VERSION ""

NS_ :

BS_:

BU_: L_3HKBD L_FHPTC L_ATCU L_2HKBD L_PCM L_ATCU_vMON L_EVNT L_HKBD L_RHPTC

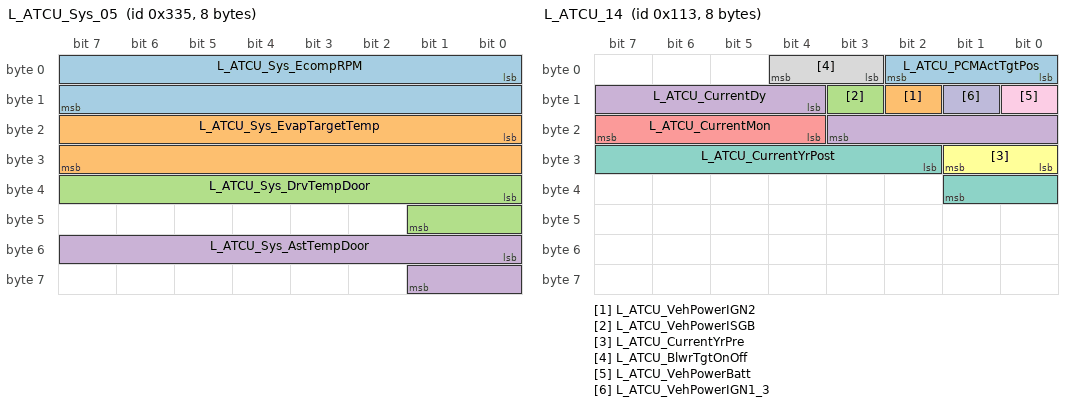
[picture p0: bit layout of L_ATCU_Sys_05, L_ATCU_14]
BO_ 821 L_ATCU_Sys_05: 8 L_ATCU
 SG_ L_ATCU_Sys_EcompRPM : 0|16@1+ (1,0) [0|65535] ""  L_ATCU_vMON
 SG_ L_ATCU_Sys_EvapTargetTemp : 16|16@1+ (0.1,-20) [-20|40] ""  L_ATCU_vMON
 SG_ L_ATCU_Sys_DrvTempDoor : 32|10@1+ (1,0) [0|1023] ""  L_ATCU_vMON
 SG_ L_ATCU_Sys_AstTempDoor : 48|10@1+ (1,0) [0|1023] ""  L_ATCU_vMON

BO_ 275 L_ATCU_14: 8 L_ATCU
 SG_ L_ATCU_PCMActTgtPos : 0|3@1+ (1,0) [0|0] ""  L_PCM
 SG_ L_ATCU_VehPowerIGN2 : 10|1@1+ (1,0) [0|0] ""  L_PCM
 SG_ L_ATCU_VehPowerISGB : 11|1@1+ (1,0) [0|0] ""  L_PCM
 SG_ L_ATCU_CurrentDy : 12|8@1+ (1,0) [0|0] ""  L_PCM
 SG_ L_ATCU_CurrentMon : 20|4@1+ (1,0) [0|0] ""  L_PCM
 SG_ L_ATCU_CurrentYrPre : 24|2@1+ (1,0) [0|0] ""  L_PCM
 SG_ L_ATCU_CurrentYrPost : 26|8@1+ (1,0) [0|0] ""  L_PCM
 SG_ L_ATCU_BlwrTgtOnOff : 3|2@1+ (0.5,0) [0|0] "RPM"  L_PCM
 SG_ L_ATCU_VehPowerBatt : 8|1@1+ (1,0) [0|0] ""  L_PCM
 SG_ L_ATCU_VehPowerIGN1_3 : 9|1@1+ (1,0) [0|0] ""  L_PCM

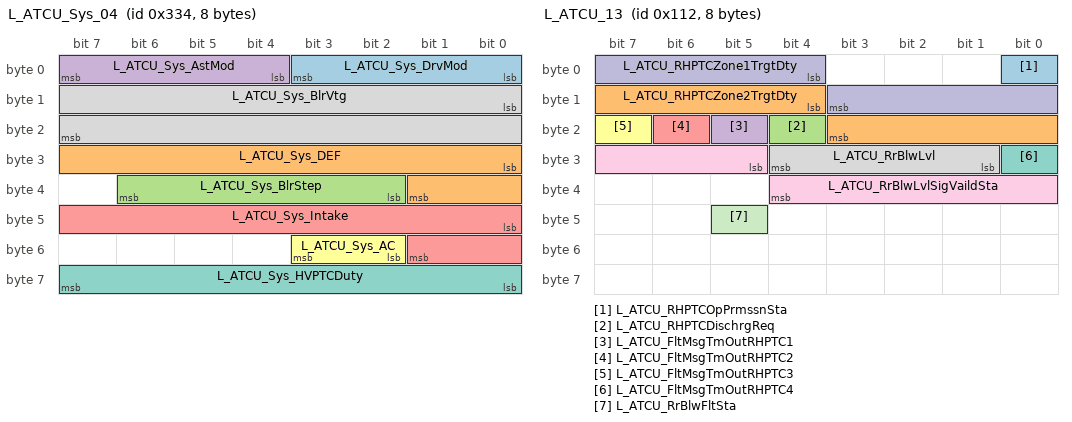
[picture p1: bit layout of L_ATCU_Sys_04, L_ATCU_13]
BO_ 820 L_ATCU_Sys_04: 8 L_ATCU
 SG_ L_ATCU_Sys_DrvMod : 0|4@1+ (1,0) [0|15] ""  L_ATCU_vMON
 SG_ L_ATCU_Sys_DEF : 24|10@1+ (1,0) [0|1023] ""  L_ATCU_vMON
 SG_ L_ATCU_Sys_BlrStep : 34|5@1+ (1,0) [0|31] ""  L_ATCU_vMON
 SG_ L_ATCU_Sys_AstMod : 4|4@1+ (1,0) [0|15] ""  L_ATCU_vMON
 SG_ L_ATCU_Sys_Intake : 40|10@1+ (1,0) [0|1023] ""  L_ATCU_vMON
 SG_ L_ATCU_Sys_AC : 50|2@1+ (1,0) [0|3] ""  L_ATCU_vMON
 SG_ L_ATCU_Sys_HVPTCDuty : 56|8@1+ (1,0) [0|255] ""  L_ATCU_vMON
 SG_ L_ATCU_Sys_BlrVtg : 8|16@1+ (1,0) [0|65535] ""  L_ATCU_vMON

BO_ 274 L_ATCU_13: 8 L_ATCU
 SG_ L_ATCU_RHPTCOpPrmssnSta : 0|1@1+ (1,0) [0|0] ""  L_FHPTC,L_RHPTC
 SG_ L_ATCU_RHPTCZone2TrgtDty : 12|8@1+ (0.5,0) [0|0] "%"  L_FHPTC,L_RHPTC
 SG_ L_ATCU_RHPTCDischrgReq : 20|1@1+ (1,0) [0|0] ""  L_FHPTC,L_RHPTC
 SG_ L_ATCU_FltMsgTmOutRHPTC1 : 21|1@1+ (1,0) [0|0] ""  L_FHPTC,L_RHPTC
 SG_ L_ATCU_FltMsgTmOutRHPTC2 : 22|1@1+ (1,0) [0|0] ""  L_FHPTC,L_RHPTC
 SG_ L_ATCU_FltMsgTmOutRHPTC3 : 23|1@1+ (1,0) [0|0] ""  L_FHPTC,L_RHPTC
 SG_ L_ATCU_FltMsgTmOutRHPTC4 : 24|1@1+ (1,0) [0|0] ""  L_FHPTC,L_RHPTC
 SG_ L_ATCU_RrBlwLvl : 25|4@1+ (1,0) [0|0] ""  L_EVNT,L_FHPTC,L_RHPTC
 SG_ L_ATCU_RrBlwLvlSigVaildSta : 29|8@1+ (1,0) [0|0] ""  L_FHPTC,L_RHPTC
 SG_ L_ATCU_RHPTCZone1TrgtDty : 4|8@1+ (0.5,0) [0|0] "%"  L_FHPTC,L_RHPTC
 SG_ L_ATCU_RrBlwFltSta : 45|1@1+ (1,0) [0|0] ""  L_FHPTC,L_RHPTC

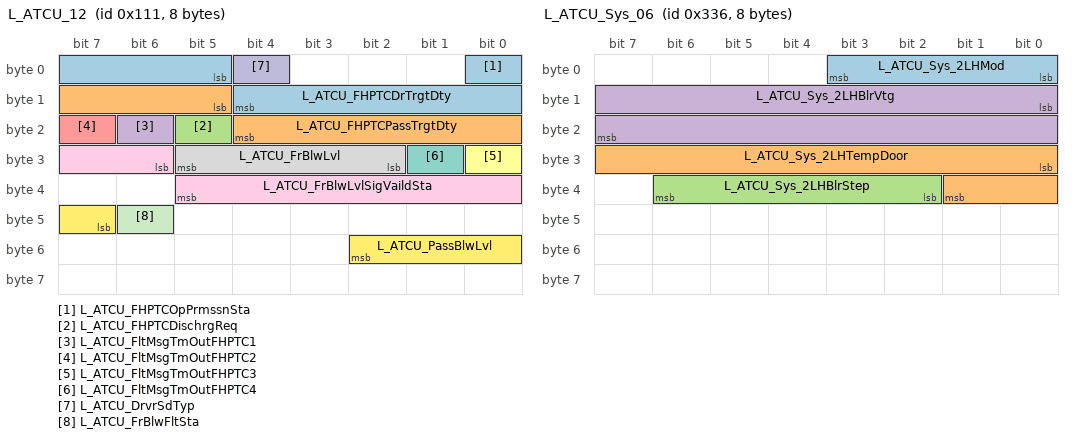
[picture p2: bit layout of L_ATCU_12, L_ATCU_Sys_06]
BO_ 273 L_ATCU_12: 8 L_ATCU
 SG_ L_ATCU_FHPTCOpPrmssnSta : 0|1@1+ (1,0) [0|0] ""  L_FHPTC,L_RHPTC
 SG_ L_ATCU_FHPTCPassTrgtDty : 13|8@1+ (0.5,0) [0|0] "%"  L_FHPTC,L_RHPTC
 SG_ L_ATCU_FHPTCDischrgReq : 21|1@1+ (1,0) [0|0] ""  L_FHPTC,L_RHPTC
 SG_ L_ATCU_FltMsgTmOutFHPTC1 : 22|1@1+ (1,0) [0|0] ""  L_FHPTC,L_RHPTC
 SG_ L_ATCU_FltMsgTmOutFHPTC2 : 23|1@1+ (1,0) [0|0] ""  L_FHPTC,L_RHPTC
 SG_ L_ATCU_FltMsgTmOutFHPTC3 : 24|1@1+ (1,0) [0|0] ""  L_FHPTC,L_RHPTC
 SG_ L_ATCU_FltMsgTmOutFHPTC4 : 25|1@1+ (1,0) [0|0] ""  L_FHPTC,L_RHPTC
 SG_ L_ATCU_FrBlwLvl : 26|4@1+ (1,0) [0|0] ""  L_EVNT,L_FHPTC,L_RHPTC
 SG_ L_ATCU_FrBlwLvlSigVaildSta : 30|8@1+ (1,0) [0|0] ""  L_FHPTC,L_RHPTC
 SG_ L_ATCU_DrvrSdTyp : 4|1@1+ (1,0) [0|0] ""  L_EVNT,L_FHPTC,L_HKBD,L_RHPTC
 SG_ L_ATCU_FrBlwFltSta : 46|1@1+ (1,0) [0|0] ""  L_FHPTC,L_RHPTC
 SG_ L_ATCU_PassBlwLvl : 47|4@1+ (1,0) [0|0] ""  L_EVNT,L_FHPTC,L_RHPTC
 SG_ L_ATCU_FHPTCDrTrgtDty : 5|8@1+ (0.5,0) [0|0] "%"  L_FHPTC,L_RHPTC

BO_ 822 L_ATCU_Sys_06: 8 L_ATCU
 SG_ L_ATCU_Sys_2LHMod : 0|4@1+ (1,0) [0|15] ""  L_ATCU_vMON
 SG_ L_ATCU_Sys_2LHTempDoor : 24|10@1+ (1,0) [0|1023] ""  L_ATCU_vMON
 SG_ L_ATCU_Sys_2LHBlrStep : 34|5@1+ (1,0) [0|31] ""  L_ATCU_vMON
 SG_ L_ATCU_Sys_2LHBlrVtg : 8|16@1+ (1,0) [0|65535] ""  L_ATCU_vMON

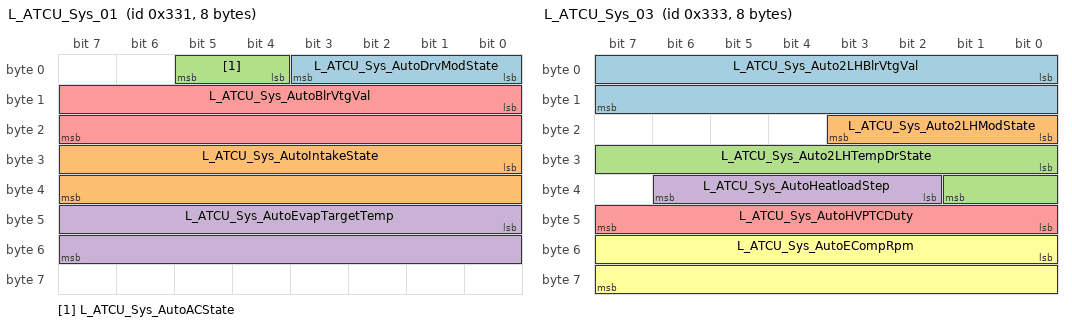
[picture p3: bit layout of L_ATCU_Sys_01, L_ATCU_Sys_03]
BO_ 817 L_ATCU_Sys_01: 8 L_ATCU
 SG_ L_ATCU_Sys_AutoDrvModState : 0|4@1+ (1,0) [0|15] ""  L_ATCU_vMON
 SG_ L_ATCU_Sys_AutoIntakeState : 24|16@1+ (1,0) [0|65535] ""  L_ATCU_vMON
 SG_ L_ATCU_Sys_AutoACState : 4|2@1+ (1,0) [0|3] ""  L_ATCU_vMON
 SG_ L_ATCU_Sys_AutoEvapTargetTemp : 40|16@1+ (0.1,-20) [-20|40] ""  L_ATCU_vMON
 SG_ L_ATCU_Sys_AutoBlrVtgVal : 8|16@1+ (1,0) [0|65535] ""  L_ATCU_vMON

BO_ 278 L_ATCU_17: 8 L_ATCU
 SG_ L_ATCU_HU_MasterProfile_ResetIndex : 0|4@1+ (1,0) [0|0] ""  L_2HKBD,L_3HKBD,L_EVNT,L_HKBD
 SG_ L_ATCU_HU_OptionInfo : 4|16@1+ (1,0) [0|0] ""  L_2HKBD,L_3HKBD,L_EVNT,L_HKBD

BO_ 819 L_ATCU_Sys_03: 8 L_ATCU
 SG_ L_ATCU_Sys_Auto2LHBlrVtgVal : 0|16@1+ (1,0) [0|65535] ""  L_ATCU_vMON
 SG_ L_ATCU_Sys_Auto2LHModState : 16|4@1+ (1,0) [0|15] ""  L_ATCU_vMON
 SG_ L_ATCU_Sys_Auto2LHTempDrState : 24|10@1+ (1,0) [0|1023] ""  L_ATCU_vMON
 SG_ L_ATCU_Sys_AutoHeatloadStep : 34|5@1+ (1,0) [0|31] ""  L_ATCU_vMON
 SG_ L_ATCU_Sys_AutoHVPTCDuty : 40|8@1+ (1,0) [0|255] ""  L_ATCU_vMON
 SG_ L_ATCU_Sys_AutoECompRpm : 48|16@1+ (1,0) [0|65535] ""  L_ATCU_vMON

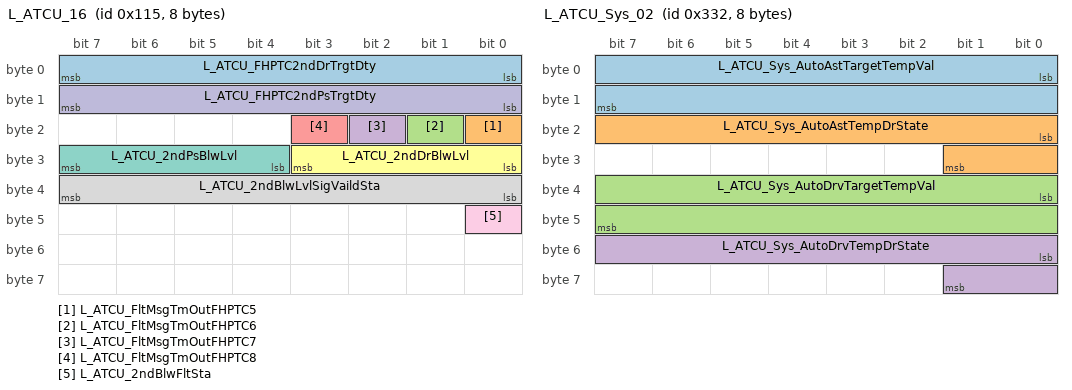
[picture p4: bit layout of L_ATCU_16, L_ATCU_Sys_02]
BO_ 277 L_ATCU_16: 8 L_ATCU
 SG_ L_ATCU_FHPTC2ndDrTrgtDty : 0|8@1+ (0.5,0) [0|0] "%"  L_FHPTC,L_RHPTC
 SG_ L_ATCU_FltMsgTmOutFHPTC5 : 16|1@1+ (1,0) [0|0] ""  L_FHPTC,L_RHPTC
 SG_ L_ATCU_FltMsgTmOutFHPTC6 : 17|1@1+ (1,0) [0|0] ""  L_FHPTC,L_RHPTC
 SG_ L_ATCU_FltMsgTmOutFHPTC7 : 18|1@1+ (1,0) [0|0] ""  L_FHPTC,L_RHPTC
 SG_ L_ATCU_FltMsgTmOutFHPTC8 : 19|1@1+ (1,0) [0|0] ""  L_FHPTC,L_RHPTC
 SG_ L_ATCU_2ndDrBlwLvl : 24|4@1+ (1,0) [0|0] ""  L_EVNT,L_FHPTC,L_RHPTC
 SG_ L_ATCU_2ndPsBlwLvl : 28|4@1+ (1,0) [0|0] ""  L_EVNT,L_FHPTC,L_RHPTC
 SG_ L_ATCU_2ndBlwLvlSigVaildSta : 32|8@1+ (1,0) [0|0] ""  L_FHPTC,L_RHPTC
 SG_ L_ATCU_2ndBlwFltSta : 40|1@1+ (1,0) [0|0] ""  L_FHPTC,L_RHPTC
 SG_ L_ATCU_FHPTC2ndPsTrgtDty : 8|8@1+ (0.5,0) [0|0] "%"  L_FHPTC,L_RHPTC

BO_ 818 L_ATCU_Sys_02: 8 L_ATCU
 SG_ L_ATCU_Sys_AutoAstTargetTempVal : 0|16@1+ (0.1,-40) [-40|60] ""  L_ATCU_vMON
 SG_ L_ATCU_Sys_AutoAstTempDrState : 16|10@1+ (1,0) [0|1023] ""  L_ATCU_vMON
 SG_ L_ATCU_Sys_AutoDrvTargetTempVal : 32|16@1+ (0.1,-40) [-40|60] ""  L_ATCU_vMON
 SG_ L_ATCU_Sys_AutoDrvTempDrState : 48|10@1+ (1,0) [0|1023] ""  L_ATCU_vMON

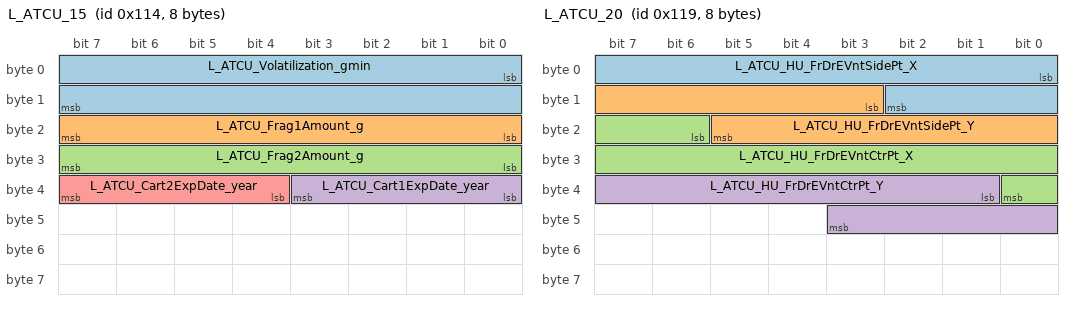
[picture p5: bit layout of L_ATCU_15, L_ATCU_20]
BO_ 276 L_ATCU_15: 8 L_ATCU
 SG_ L_ATCU_Volatilization_gmin : 0|16@1+ (1.0E-6,0) [0|0] "g/min"  L_PCM
 SG_ L_ATCU_Frag1Amount_g : 16|8@1+ (0.1,0) [0|0] "g"  L_PCM
 SG_ L_ATCU_Frag2Amount_g : 24|8@1+ (0.1,0) [0|0] "g"  L_PCM
 SG_ L_ATCU_Cart1ExpDate_year : 32|4@1+ (1,0) [0|0] "Year"  L_PCM
 SG_ L_ATCU_Cart2ExpDate_year : 36|4@1+ (1,0) [0|0] "Year"  L_PCM

BO_ 281 L_ATCU_20: 8 L_ATCU
 SG_ L_ATCU_HU_FrDrEVntSidePt_X : 0|11@1+ (1,0) [0|0] ""  L_EVNT
 SG_ L_ATCU_HU_FrDrEVntSidePt_Y : 11|11@1+ (1,0) [0|0] ""  L_EVNT
 SG_ L_ATCU_HU_FrDrEVntCtrPt_X : 22|11@1+ (1,0) [0|0] ""  L_EVNT
 SG_ L_ATCU_HU_FrDrEVntCtrPt_Y : 33|11@1+ (1,0) [0|0] ""  L_EVNT

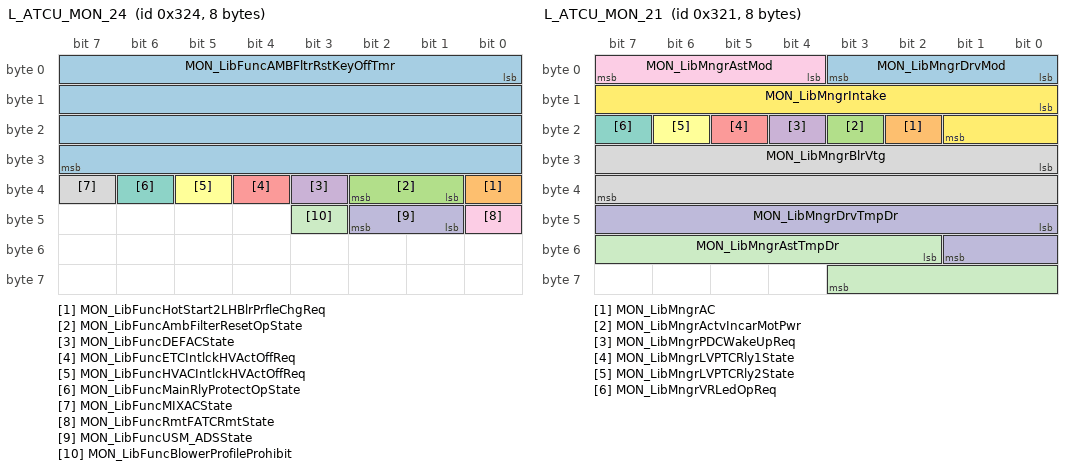
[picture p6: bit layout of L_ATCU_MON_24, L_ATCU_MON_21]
BO_ 804 L_ATCU_MON_24: 8 L_ATCU_vMON
 SG_ MON_LibFuncAMBFltrRstKeyOffTmr : 0|32@1+ (1,0) [0|0] "s"  L_ATCU
 SG_ MON_LibFuncHotStart2LHBlrPrfleChgReq : 32|1@1+ (1,0) [0|0] ""  L_ATCU
 SG_ MON_LibFuncAmbFilterResetOpState : 33|2@1+ (1,0) [0|0] ""  L_ATCU
 SG_ MON_LibFuncDEFACState : 35|1@1+ (1,0) [0|0] ""  L_ATCU
 SG_ MON_LibFuncETCIntlckHVActOffReq : 36|1@1+ (1,0) [0|0] ""  L_ATCU
 SG_ MON_LibFuncHVACIntlckHVActOffReq : 37|1@1+ (1,0) [0|0] ""  L_ATCU
 SG_ MON_LibFuncMainRlyProtectOpState : 38|1@1+ (1,0) [0|0] ""  L_ATCU
 SG_ MON_LibFuncMIXACState : 39|1@1+ (1,0) [0|0] ""  L_ATCU
 SG_ MON_LibFuncRmtFATCRmtState : 40|1@1+ (1,0) [0|0] ""  L_ATCU
 SG_ MON_LibFuncUSM_ADSState : 41|2@1+ (1,0) [0|0] ""  L_ATCU
 SG_ MON_LibFuncBlowerProfileProhibit : 43|1@1+ (1,0) [0|0] ""  L_ATCU

BO_ 805 L_ATCU_MON_25: 8 L_ATCU_vMON
 SG_ MON_LibMEMUSMROMWriteCmd : 0|32@1+ (1,0) [0|0] ""  L_ATCU
 SG_ MON_LibMEMROMWriteMEM : 32|32@1+ (1,0) [0|0] ""  L_ATCU

BO_ 806 L_ATCU_MON_26: 8 L_ATCU_vMON
 SG_ MON_LibFuncAfterBlowStandbyTime : 0|32@1+ (1,0) [0|0] "ms"  L_ATCU
 SG_ MON_LibFuncSchdldVentStandbyTime : 32|32@1+ (1,0) [0|0] "s"  L_ATCU

BO_ 807 L_ATCU_MON_27: 8 L_ATCU_vMON
 SG_ MON_LibFuncHICCSWVer : 0|32@1+ (1,0) [0|0] ""  L_ATCU

BO_ 801 L_ATCU_MON_21: 8 L_ATCU_vMON
 SG_ MON_LibMngrDrvMod : 0|4@1+ (1,0) [0|0] ""  L_ATCU
 SG_ MON_LibMngrAC : 18|1@1+ (1,0) [0|0] ""  L_ATCU
 SG_ MON_LibMngrActvIncarMotPwr : 19|1@1+ (1,0) [0|0] ""  L_ATCU
 SG_ MON_LibMngrPDCWakeUpReq : 20|1@1+ (1,0) [0|0] ""  L_ATCU
 SG_ MON_LibMngrLVPTCRly1State : 21|1@1+ (1,0) [0|0] ""  L_ATCU
 SG_ MON_LibMngrLVPTCRly2State : 22|1@1+ (1,0) [0|0] ""  L_ATCU
 SG_ MON_LibMngrVRLedOpReq : 23|1@1+ (1,0) [0|0] ""  L_ATCU
 SG_ MON_LibMngrBlrVtg : 24|16@1+ (0.001,0) [0|0] "V"  L_ATCU
 SG_ MON_LibMngrAstMod : 4|4@1+ (1,0) [0|0] ""  L_ATCU
 SG_ MON_LibMngrDrvTmpDr : 40|10@1+ (0.1,0) [0|0] "%"  L_ATCU
 SG_ MON_LibMngrAstTmpDr : 50|10@1+ (0.1,0) [0|0] "%"  L_ATCU
 SG_ MON_LibMngrIntake : 8|10@1+ (1,0) [0|0] ""  L_ATCU

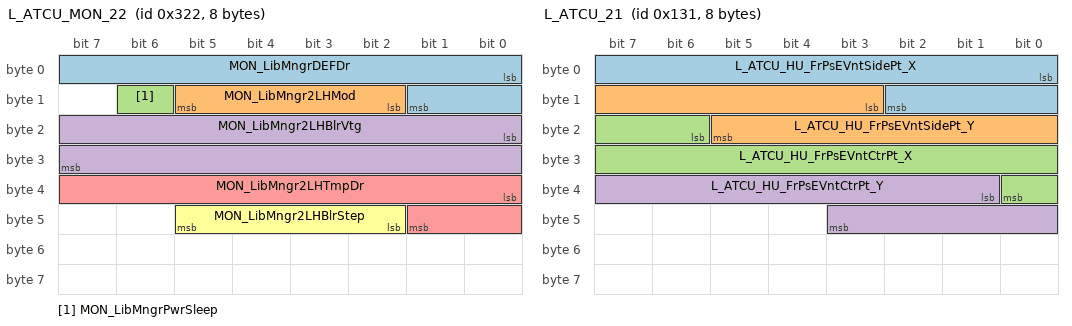
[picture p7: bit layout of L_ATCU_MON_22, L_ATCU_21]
BO_ 802 L_ATCU_MON_22: 8 L_ATCU_vMON
 SG_ MON_LibMngrDEFDr : 0|10@1+ (0.1,0) [0|0] "%"  L_ATCU
 SG_ MON_LibMngr2LHMod : 10|4@1+ (1,0) [0|0] ""  L_ATCU
 SG_ MON_LibMngrPwrSleep : 14|1@1+ (1,0) [0|0] ""  L_ATCU
 SG_ MON_LibMngr2LHBlrVtg : 16|16@1+ (0.001,0) [0|0] "V"  L_ATCU
 SG_ MON_LibMngr2LHTmpDr : 32|10@1+ (0.1,0) [0|0] "%"  L_ATCU
 SG_ MON_LibMngr2LHBlrStep : 42|4@1+ (1,0) [0|0] ""  L_ATCU

BO_ 803 L_ATCU_MON_23: 8 L_ATCU_vMON
 SG_ MON_LibFuncSysKeyState : 0|3@1+ (1,0) [0|0] ""  L_ATCU
 SG_ MON_LibFuncSwBlrStatus : 12|1@1+ (1,0) [0|0] ""  L_ATCU
 SG_ MON_LibFuncSwIntakeStatus : 13|1@1+ (1,0) [0|0] ""  L_ATCU
 SG_ MON_LibFuncSwACStatus : 14|1@1+ (1,0) [0|0] ""  L_ATCU
 SG_ MON_LibFuncAutoSw : 15|1@1+ (1,0) [0|0] ""  L_ATCU
 SG_ MON_LibFuncSwIntakeState : 16|10@1+ (0.1,0) [0|0] ""  L_ATCU
 SG_ MON_LibFuncIntakeRECSw : 26|1@1+ (1,0) [0|0] ""  L_ATCU
 SG_ MON_LibFuncSwDrvTempStepState : 27|5@1+ (1,0) [0|0] ""  L_ATCU
 SG_ MON_LibFuncSwModState : 3|4@1+ (1,0) [0|0] ""  L_ATCU
 SG_ MON_LibFunc2LHSwTempStepState : 32|5@1+ (1,0) [0|0] ""  L_ATCU
 SG_ MON_LibFuncIntakeFRESw : 37|1@1+ (1,0) [0|0] ""  L_ATCU
 SG_ MON_LibFunc2LHSwModStatus : 38|1@1+ (1,0) [0|0] ""  L_ATCU
 SG_ MON_LibFunc2LHBlowerProfileProhibit : 39|1@1+ (1,0) [0|0] ""  L_ATCU
 SG_ MON_LibFunc2LHSwModState : 40|4@1+ (1,0) [0|0] ""  L_ATCU
 SG_ MON_LibFunc2LHBlrStepState : 44|4@1+ (1,0) [0|0] ""  L_ATCU
 SG_ MON_LibFunc2LHAutoSw : 48|1@1+ (1,0) [0|0] ""  L_ATCU
 SG_ MON_LibFunc2LHSwBlrStatus : 49|1@1+ (1,0) [0|0] ""  L_ATCU
 SG_ MON_LibFuncSwModStatus : 7|1@1+ (1,0) [0|0] ""  L_ATCU
 SG_ MON_LibFuncBlrStepState : 8|4@1+ (1,0) [0|0] ""  L_ATCU

BO_ 791 L_ATCU_MON_42: 8 L_ATCU_vMON
 SG_ MON_StatMngr_2ndMngr : 0|64@1+ (1,0) [0|0] ""  L_ATCU

BO_ 305 L_ATCU_21: 8 L_ATCU
 SG_ L_ATCU_HU_FrPsEVntSidePt_X : 0|11@1+ (1,0) [0|0] ""  L_EVNT
 SG_ L_ATCU_HU_FrPsEVntSidePt_Y : 11|11@1+ (1,0) [0|0] ""  L_EVNT
 SG_ L_ATCU_HU_FrPsEVntCtrPt_X : 22|11@1+ (1,0) [0|0] ""  L_EVNT
 SG_ L_ATCU_HU_FrPsEVntCtrPt_Y : 33|11@1+ (1,0) [0|0] ""  L_EVNT

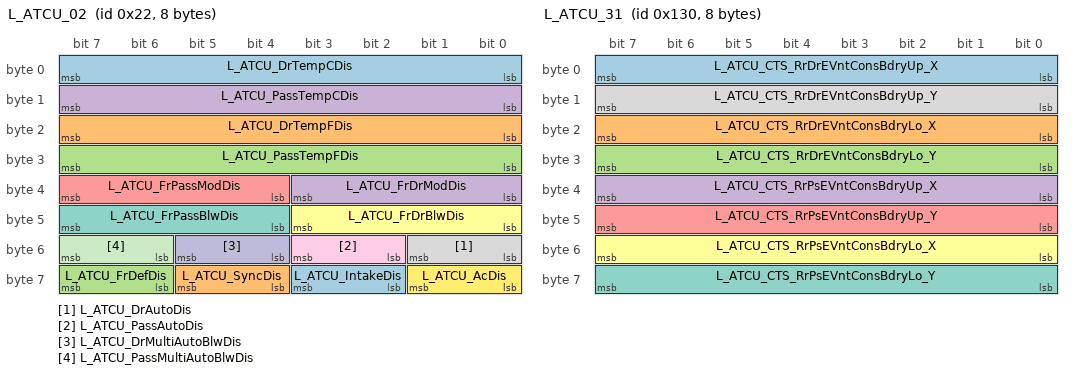
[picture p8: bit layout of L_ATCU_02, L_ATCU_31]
BO_ 34 L_ATCU_02: 8 L_ATCU
 SG_ L_ATCU_DrTempCDis : 0|8@1+ (0.5,14) [0|0] "¡É"  L_HKBD
 SG_ L_ATCU_DrTempFDis : 16|8@1+ (1,56) [0|0] "¢µ"  L_HKBD
 SG_ L_ATCU_PassTempFDis : 24|8@1+ (1,56) [0|0] "¢µ"  L_HKBD
 SG_ L_ATCU_FrDrModDis : 32|4@1+ (1,0) [0|0] ""  L_EVNT,L_HKBD
 SG_ L_ATCU_FrPassModDis : 36|4@1+ (1,0) [0|0] ""  L_EVNT,L_HKBD
 SG_ L_ATCU_FrDrBlwDis : 40|4@1+ (1,0) [0|0] ""  L_HKBD
 SG_ L_ATCU_FrPassBlwDis : 44|4@1+ (1,0) [0|0] ""  L_HKBD
 SG_ L_ATCU_DrAutoDis : 48|2@1+ (1,0) [0|0] ""  L_HKBD
 SG_ L_ATCU_PassAutoDis : 50|2@1+ (1,0) [0|0] ""  L_HKBD
 SG_ L_ATCU_DrMultiAutoBlwDis : 52|2@1+ (1,0) [0|0] ""  L_HKBD
 SG_ L_ATCU_PassMultiAutoBlwDis : 54|2@1+ (1,0) [0|0] ""  L_HKBD
 SG_ L_ATCU_AcDis : 56|2@1+ (1,0) [0|0] ""  L_HKBD
 SG_ L_ATCU_IntakeDis : 58|2@1+ (1,0) [0|0] ""  L_HKBD
 SG_ L_ATCU_SyncDis : 60|2@1+ (1,0) [0|0] ""  L_HKBD
 SG_ L_ATCU_FrDefDis : 62|2@1+ (1,0) [0|0] ""  L_HKBD
 SG_ L_ATCU_PassTempCDis : 8|8@1+ (0.5,14) [0|0] "¡É"  L_HKBD

BO_ 790 L_ATCU_MON_41: 8 L_ATCU_vMON
 SG_ MON_StatMngr_2ndSafetynCool : 0|64@1+ (1,0) [0|0] ""  L_ATCU

BO_ 304 L_ATCU_31: 8 L_ATCU
 SG_ L_ATCU_CTS_RrDrEVntConsBdryUp_X : 0|8@1+ (10,0) [0|0] ""  L_EVNT
 SG_ L_ATCU_CTS_RrDrEVntConsBdryLo_X : 16|8@1+ (10,0) [0|0] ""  L_EVNT
 SG_ L_ATCU_CTS_RrDrEVntConsBdryLo_Y : 24|8@1+ (10,0) [0|0] ""  L_EVNT
 SG_ L_ATCU_CTS_RrPsEVntConsBdryUp_X : 32|8@1+ (10,0) [0|0] ""  L_EVNT
 SG_ L_ATCU_CTS_RrPsEVntConsBdryUp_Y : 40|8@1+ (10,0) [0|0] ""  L_EVNT
 SG_ L_ATCU_CTS_RrPsEVntConsBdryLo_X : 48|8@1+ (10,0) [0|0] ""  L_EVNT
 SG_ L_ATCU_CTS_RrPsEVntConsBdryLo_Y : 56|8@1+ (10,0) [0|0] ""  L_EVNT
 SG_ L_ATCU_CTS_RrDrEVntConsBdryUp_Y : 8|8@1+ (10,0) [0|0] ""  L_EVNT

BO_ 35 L_ATCU_03: 8 L_ATCU
 SG_ L_ATCU_DrOnlyDis : 0|2@1+ (1,0) [0|0] ""  L_EVNT,L_HKBD
 SG_ L_ATCU_SmrtVntDis : 11|2@1+ (1,0) [0|0] ""  L_HKBD
 SG_ L_ATCU_FrWndShldHtInd : 13|2@1+ (1,0) [0|0] ""  L_HKBD
 SG_ L_ATCU_IncarMtrOnReq : 15|1@1+ (1,0) [0|0] ""  L_HKBD
 SG_ L_ATCU_LanguageInfo : 16|8@1+ (1,0) [0|0] ""  L_HKBD
 SG_ L_ATCU_RrDefInd : 2|1@1+ (1,0) [0|0] ""  L_HKBD
 SG_ L_ATCU_AfterBlowDisplay : 24|2@1+ (1,0) [0|0] ""  L_HKBD
 SG_ L_ATCU_SchdldVentDisplay : 26|2@1+ (1,0) [0|0] ""  L_HKBD
 SG_ L_ATCU_FLStHeatSwHInd : 28|1@1+ (1,0) [0|0] ""  L_HKBD
 SG_ L_ATCU_FLStHeatSwMInd : 29|1@1+ (1,0) [0|0] ""  L_HKBD
 SG_ L_ATCU_ADSBlinkDis : 3|2@1+ (1,0) [0|0] ""  L_HKBD
 SG_ L_ATCU_FLStHeatSwLInd : 30|1@1+ (1,0) [0|0] ""  L_HKBD
 SG_ L_ATCU_FLStVntSwHInd : 31|1@1+ (1,0) [0|0] ""  L_HKBD
 SG_ L_ATCU_FLStVntSwMInd : 32|1@1+ (1,0) [0|0] ""  L_HKBD
 SG_ L_ATCU_FLStVntSwLInd : 33|1@1+ (1,0) [0|0] ""  L_HKBD
 SG_ L_ATCU_FRStHeatSwHInd : 34|1@1+ (1,0) [0|0] ""  L_HKBD
 SG_ L_ATCU_FRStHeatSwMInd : 35|1@1+ (1,0) [0|0] ""  L_HKBD
 SG_ L_ATCU_FRStHeatSwLInd : 36|1@1+ (1,0) [0|0] ""  L_HKBD
 SG_ L_ATCU_FRStVntSwHInd : 37|1@1+ (1,0) [0|0] ""  L_HKBD
 SG_ L_ATCU_FRStVntSwMInd : 38|1@1+ (1,0) [0|0] ""  L_HKBD
 SG_ L_ATCU_FRStVntSwLInd : 39|1@1+ (1,0) [0|0] ""  L_HKBD
 SG_ L_ATCU_StrWhlHeatInd : 40|2@1+ (1,0) [0|0] ""  L_HKBD
 SG_ L_ATCU_RhstaLvlSta : 42|5@1+ (1,0) [0|0] ""  L_2HKBD,L_EVNT,L_HKBD
 SG_ L_ATCU_IntTailOnOff : 47|1@1+ (1,0) [0|0] ""  L_2HKBD,L_HKBD
 SG_ L_ATCU_AutoLightSta : 48|1@1+ (1,0) [0|0] ""  L_HKBD
 SG_ L_ATCU_FrBckLightSta : 49|1@1+ (1,0) [0|0] ""  L_HKBD
 SG_ L_ATCU_DisplayTheme : 50|2@1+ (1,0) [0|0] ""  L_HKBD
 SG_ L_ATCU_GUIBlankDis : 52|1@1+ (1,0) [0|0] ""  L_HKBD
 SG_ L_ATCU_HptIntnstySet : 53|4@1+ (1,0) [0|0] ""  L_HKBD
 SG_ L_ATCU_TlltLmpDis : 57|3@1+ (1,0) [0|0] ""  L_HKBD
 SG_ L_ATCU_AvTailOnOff : 60|1@1+ (1,0) [0|0] ""  L_HKBD
 SG_ L_ATCU_SchdldClimateDisplay : 61|2@1+ (1,0) [0|0] ""  L_HKBD
 SG_ L_ATCU_AirClnDis : 7|2@1+ (1,0) [0|0] ""  L_HKBD
 SG_ L_ATCU_CO2WrngDis : 9|2@1+ (1,0) [0|0] ""  L_HKBD

BO_ 789 L_ATCU_MON_40: 8 L_ATCU_vMON
 SG_ MON_StatMngr_2ndTemp : 0|64@1+ (1,0) [0|0] ""  L_ATCU

BO_ 788 L_ATCU_MON_39: 8 L_ATCU_vMON
 SG_ MON_StatMngr_2ndHumid : 0|64@1+ (1,0) [0|0] ""  L_ATCU

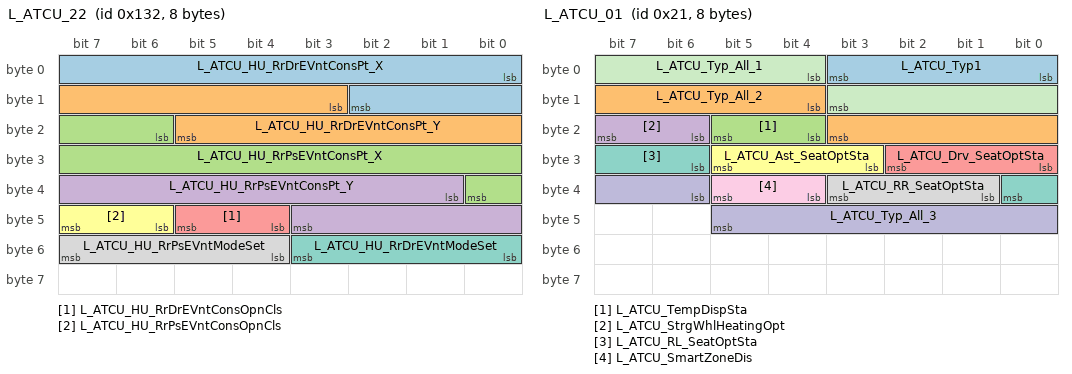
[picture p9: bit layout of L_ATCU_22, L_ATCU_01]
BO_ 306 L_ATCU_22: 8 L_ATCU
 SG_ L_ATCU_HU_RrDrEVntConsPt_X : 0|11@1+ (1,0) [0|0] ""  L_EVNT
 SG_ L_ATCU_HU_RrDrEVntConsPt_Y : 11|11@1+ (1,0) [0|0] ""  L_EVNT
 SG_ L_ATCU_HU_RrPsEVntConsPt_X : 22|11@1+ (1,0) [0|0] ""  L_EVNT
 SG_ L_ATCU_HU_RrPsEVntConsPt_Y : 33|11@1+ (1,0) [0|0] ""  L_EVNT
 SG_ L_ATCU_HU_RrDrEVntConsOpnCls : 44|2@1+ (1,0) [0|0] ""  L_EVNT
 SG_ L_ATCU_HU_RrPsEVntConsOpnCls : 46|2@1+ (1,0) [0|0] ""  L_EVNT
 SG_ L_ATCU_HU_RrDrEVntModeSet : 48|4@1+ (1,0) [0|0] ""  L_EVNT
 SG_ L_ATCU_HU_RrPsEVntModeSet : 52|4@1+ (1,0) [0|0] ""  L_EVNT

BO_ 33 L_ATCU_01: 8 L_ATCU
 SG_ L_ATCU_Typ1 : 0|4@1+ (1,0) [0|0] ""  L_HKBD
 SG_ L_ATCU_Typ_All_2 : 12|8@1+ (1,0) [0|0] ""  L_2HKBD,L_3HKBD,L_HKBD
 SG_ L_ATCU_TempDispSta : 20|2@1+ (1,0) [0|0] ""  L_2HKBD,L_3HKBD,L_HKBD
 SG_ L_ATCU_StrgWhlHeatingOpt : 22|2@1+ (1,0) [0|0] ""  L_2HKBD,L_3HKBD,L_HKBD
 SG_ L_ATCU_Drv_SeatOptSta : 24|3@1+ (1,0) [0|0] ""  L_2HKBD,L_3HKBD,L_HKBD
 SG_ L_ATCU_Ast_SeatOptSta : 27|3@1+ (1,0) [0|0] ""  L_2HKBD,L_3HKBD,L_HKBD
 SG_ L_ATCU_RL_SeatOptSta : 30|3@1+ (1,0) [0|0] ""  L_2HKBD,L_3HKBD,L_HKBD
 SG_ L_ATCU_RR_SeatOptSta : 33|3@1+ (1,0) [0|0] ""  L_2HKBD,L_3HKBD,L_HKBD
 SG_ L_ATCU_SmartZoneDis : 36|2@1+ (1,0) [0|0] ""  L_HKBD
 SG_ L_ATCU_Typ_All_3 : 38|8@1+ (1,0) [0|0] ""  L_2HKBD,L_3HKBD,L_HKBD
 SG_ L_ATCU_Typ_All_1 : 4|8@1+ (1,0) [0|0] ""  L_2HKBD,L_3HKBD,L_HKBD

BO_ 787 L_ATCU_MON_38: 8 L_ATCU_vMON
 SG_ MON_StatMngr_Snsr : 0|64@1+ (1,0) [0|0] ""  L_ATCU

BO_ 38 L_ATCU_06: 8 L_ATCU
 SG_ L_ATCU_3rdRrTempCDis : 0|8@1+ (0.5,14) [0|0] "¡É"  L_3HKBD,L_HKBD
 SG_ L_ATCU_3rdRrModDis : 16|4@1+ (1,0) [0|0] ""  L_3HKBD,L_HKBD
 SG_ L_ATCU_3rdRrBlwDis : 20|4@1+ (1,0) [0|0] ""  L_3HKBD,L_HKBD
 SG_ L_ATCU_3rdRrAutoDis : 24|2@1+ (1,0) [0|0] ""  L_3HKBD,L_HKBD
 SG_ L_ATCU_3rdRrMultiAutoBlwDis : 26|3@1+ (1,0) [0|0] ""  L_3HKBD,L_HKBD
 SG_ L_ATCU_3rdRrSyncDis : 29|2@1+ (1,0) [0|0] ""  L_3HKBD,L_HKBD
 SG_ L_ATCU_3rdRrOnInd : 31|2@1+ (1,0) [0|0] ""  L_3HKBD,L_HKBD
 SG_ L_ATCU_3rdRrLockDis : 33|2@1+ (1,0) [0|0] ""  L_3HKBD,L_HKBD
 SG_ L_ATCU_3rdRrLcdBckLightSta : 35|1@1+ (1,0) [0|0] ""  L_3HKBD,L_HKBD
 SG_ L_ATCU_3rdRrGUIBlankDis : 36|1@1+ (1,0) [0|0] ""  L_3HKBD,L_HKBD
 SG_ L_ATCU_3rdRLStHeatSwHInd : 37|1@1+ (1,0) [0|0] ""  L_3HKBD,L_HKBD
 SG_ L_ATCU_3rdRLStHeatSwMInd : 38|1@1+ (1,0) [0|0] ""  L_3HKBD,L_HKBD
 SG_ L_ATCU_3rdRLStHeatSwLInd : 39|1@1+ (1,0) [0|0] ""  L_3HKBD,L_HKBD
 SG_ L_ATCU_3rdRLStVntSwHInd : 40|1@1+ (1,0) [0|0] ""  L_3HKBD,L_HKBD
 SG_ L_ATCU_3rdRLStVntSwMInd : 41|1@1+ (1,0) [0|0] ""  L_3HKBD,L_HKBD
 SG_ L_ATCU_3rdRLStVntSwLInd : 42|1@1+ (1,0) [0|0] ""  L_3HKBD,L_HKBD
 SG_ L_ATCU_3rdRRStHeatSwHInd : 43|1@1+ (1,0) [0|0] ""  L_3HKBD,L_HKBD
 SG_ L_ATCU_3rdRRStHeatSwMInd : 44|1@1+ (1,0) [0|0] ""  L_3HKBD,L_HKBD
 SG_ L_ATCU_3rdRRStHeatSwLInd : 45|1@1+ (1,0) [0|0] ""  L_3HKBD,L_HKBD
 SG_ L_ATCU_3rdRRStVntSwHInd : 46|1@1+ (1,0) [0|0] ""  L_3HKBD,L_HKBD
 SG_ L_ATCU_3rdRRStVntSwMInd : 47|1@1+ (1,0) [0|0] ""  L_3HKBD,L_HKBD
 SG_ L_ATCU_3rdRRStVntSwLInd : 48|1@1+ (1,0) [0|0] ""  L_3HKBD,L_HKBD
 SG_ L_ATCU_3rdRrMTCOpSta : 49|2@1+ (1,0) [0|0] ""  L_3HKBD,L_HKBD
 SG_ L_ATCU_3rdRrMtcTempLvl : 51|4@1+ (1,0) [0|0] ""  L_3HKBD,L_HKBD
 SG_ L_ATCU_3rdAUTOStep : 55|3@1+ (1,0) [0|0] ""  L_3HKBD,L_HKBD
 SG_ L_ATCU_RrPassMultiAutoBlwDis : 58|3@1+ (1,0) [0|0] ""  L_2HKBD,L_HKBD
 SG_ L_ATCU_DisPnlState : 61|2@1+ (1,0) [0|0] ""  L_HKBD
 SG_ L_ATCU_3rdRrTempFDis : 8|8@1+ (1,56) [0|0] "¢µ"  L_3HKBD,L_HKBD

BO_ 786 L_ATCU_MON_37: 8 L_ATCU_vMON
 SG_ MON_StatMngr_FuelEfficiency : 0|64@1+ (1,0) [0|0] ""  L_ATCU

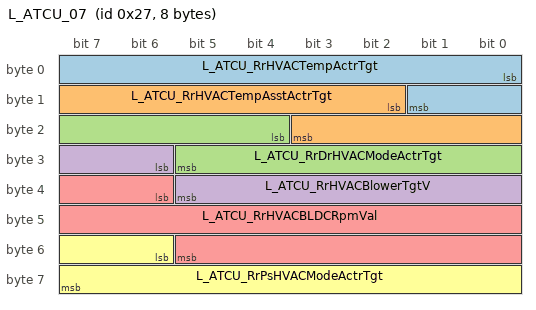
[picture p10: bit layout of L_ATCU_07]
BO_ 39 L_ATCU_07: 8 L_ATCU
 SG_ L_ATCU_RrHVACTempActrTgt : 0|10@1+ (1,0) [0|0] "AD"  L_2HKBD,L_3HKBD,L_HKBD
 SG_ L_ATCU_RrHVACTempAsstActrTgt : 10|10@1+ (1,0) [0|0] "AD"  L_2HKBD,L_3HKBD,L_HKBD
 SG_ L_ATCU_RrDrHVACModeActrTgt : 20|10@1+ (1,0) [0|0] ""  L_2HKBD,L_3HKBD,L_HKBD
 SG_ L_ATCU_RrHVACBlowerTgtV : 30|8@1+ (0.1,0) [0|0] "V"  L_2HKBD,L_3HKBD,L_HKBD
 SG_ L_ATCU_RrHVACBLDCRpmVal : 38|16@1+ (1,0) [0|0] "rpm"  L_2HKBD,L_3HKBD,L_HKBD
 SG_ L_ATCU_RrPsHVACModeActrTgt : 54|10@1+ (1,0) [0|0] ""  L_2HKBD,L_3HKBD,L_HKBD

BO_ 785 L_ATCU_MON_36: 8 L_ATCU_vMON
 SG_ MON_StatMngr_ETC : 0|64@1+ (1,0) [0|0] ""  L_ATCU

CM_ BO_ 33 "[PE] Periodic and On Event";
CM_ SG_ 33 L_ATCU_Typ1 "ATCU_Type1";
CM_ SG_ 33 L_ATCU_Drv_SeatOptSta "ATCU_Drvier_SeatOptionStaus";
CM_ SG_ 33 L_ATCU_Ast_SeatOptSta "ATCU_Ast_SeatOptionStatus";
CM_ SG_ 33 L_ATCU_RL_SeatOptSta "ATCU_RearLeft_SeatOptionStatus";
CM_ SG_ 33 L_ATCU_RR_SeatOptSta "ATCU_RearRight_SeatOperationStatus";
CM_ SG_ 33 L_ATCU_SmartZoneDis "L_ATCU_SmartZoneDisplay";
CM_ BO_ 34 "[PE] Periodic and On Event";
CM_ SG_ 34 L_ATCU_DrTempCDis "ATCU_DrvierTemperatureDisplay(¡É)";
CM_ SG_ 34 L_ATCU_DrTempFDis "ATCU_DriverTemperatureDisplay(¢µ)";
CM_ SG_ 34 L_ATCU_PassTempFDis "ATCU_PassengerTemperatureDisplay(¢µ)";
CM_ SG_ 34 L_ATCU_FrDrModDis "ATCU_FrontDriverModeDisplay";
CM_ SG_ 34 L_ATCU_FrPassModDis "ATCU_FrontPassengerModeDisplay";
CM_ SG_ 34 L_ATCU_FrDrBlwDis "ATCU_FrontDriverBlowerDisplay";
CM_ SG_ 34 L_ATCU_FrPassBlwDis "ATCU_FrontPassengerBlowerDisplay";
CM_ SG_ 34 L_ATCU_DrAutoDis "ATCU_DriverAutoDisplay";
CM_ SG_ 34 L_ATCU_PassAutoDis "ATCU_PassengerAutoDisplay";
CM_ SG_ 34 L_ATCU_DrMultiAutoBlwDis "ATCU_DriverMultiAutoBlowerDisplay";
CM_ SG_ 34 L_ATCU_PassMultiAutoBlwDis "ATCU_PassengerMultiAutoBlowerDisplay";
CM_ SG_ 34 L_ATCU_AcDis "ATCU_AcDisplay";
CM_ SG_ 34 L_ATCU_IntakeDis "ATCU_IntakeDisplay";
CM_ SG_ 34 L_ATCU_SyncDis "ATCU_SyncDisplay";
CM_ SG_ 34 L_ATCU_FrDefDis "ATCU_FrontDefrostDisplay";
CM_ SG_ 34 L_ATCU_PassTempCDis "ATCU_PassengerTemperatureDisplay(¡É)";
CM_ BO_ 35 "[PE] Periodic and On Event";
CM_ SG_ 35 L_ATCU_DrOnlyDis "ATCU_DriverOnlyDisplay";
CM_ SG_ 35 L_ATCU_SmrtVntDis "ATCU_SmartVentilationDisplay";
CM_ SG_ 35 L_ATCU_FrWndShldHtInd "ATCU_FrontWindShieldHeaterIndicator";
CM_ SG_ 35 L_ATCU_IncarMtrOnReq "ATCU_IncarMotorOnRequest";
CM_ SG_ 35 L_ATCU_LanguageInfo "ATCU_LanguageInformation";
CM_ SG_ 35 L_ATCU_RrDefInd "ATCU_RearDEFIndicator";
CM_ SG_ 35 L_ATCU_AfterBlowDisplay "ATCU_AfterBlow Display";
CM_ SG_ 35 L_ATCU_SchdldVentDisplay "ATCU_SchduledVentDispaly";
CM_ SG_ 35 L_ATCU_FLStHeatSwHInd "ATCU_FrontLeftSeatHeatSwitchHighIndicator";
CM_ SG_ 35 L_ATCU_FLStHeatSwMInd "ATCU_FrontLeftSeatHeatSwitchMiddleIndicator";
CM_ SG_ 35 L_ATCU_ADSBlinkDis "ATCU_ADSBlinkDisplay";
CM_ SG_ 35 L_ATCU_FLStHeatSwLInd "ATCU_FrontLeftSeatHeatSwitchLowIndicator";
CM_ SG_ 35 L_ATCU_FLStVntSwHInd "ATCU_FrontLeftSeatVentilationSwitchHighIndicator";
CM_ SG_ 35 L_ATCU_FLStVntSwMInd "ATCU_FrontLeftSeatVentilationSwitchMiddleIndicator";
CM_ SG_ 35 L_ATCU_FLStVntSwLInd "ATCU_FrontLeftSeatVentilationSwitchLowIndicator";
CM_ SG_ 35 L_ATCU_FRStHeatSwHInd "ATCU_FrontRightSeatHeatSwitchHighIndicator";
CM_ SG_ 35 L_ATCU_FRStHeatSwMInd "ATCU_FrontRightSeatHeatSwitchMiddleIndicator";
CM_ SG_ 35 L_ATCU_FRStHeatSwLInd "ATCU_FrontRightSeatHeatSwitchLowIndicator";
CM_ SG_ 35 L_ATCU_FRStVntSwHInd "ATCU_FrontRightSeatVentilationSwitchHighIndicator";
CM_ SG_ 35 L_ATCU_FRStVntSwMInd "ATCU_FrontRightSeatVentilationSwitchMiddleIndicator";
CM_ SG_ 35 L_ATCU_FRStVntSwLInd "ATCU_FrontRightSeatVentilationSwitchLowIndicator";
CM_ SG_ 35 L_ATCU_StrWhlHeatInd "ATCU_SteeringWheelHeatIndicator";
CM_ SG_ 35 L_ATCU_RhstaLvlSta "ATCU_RheostatLevelStatus";
CM_ SG_ 35 L_ATCU_IntTailOnOff "ATCU_InternalTailOnOff";
CM_ SG_ 35 L_ATCU_AutoLightSta "ATCU_AutoLightStatus";
CM_ SG_ 35 L_ATCU_FrBckLightSta "ATCU_FrontBackLightStatus";
CM_ SG_ 35 L_ATCU_DisplayTheme "ATCU_DisplayTheme";
CM_ SG_ 35 L_ATCU_GUIBlankDis "ATCU_GUIBlankDisplay";
CM_ SG_ 35 L_ATCU_HptIntnstySet "ATCU_HapticIntensityLevelSet";
CM_ SG_ 35 L_ATCU_TlltLmpDis "ATCU_TelltaleLampDisplay";
CM_ SG_ 35 L_ATCU_AvTailOnOff "ATCU_AVTailOnOff";
CM_ SG_ 35 L_ATCU_SchdldClimateDisplay "ATCU_ScheduledClimateDisplay";
CM_ SG_ 35 L_ATCU_AirClnDis "ATCU_AirCleaningDisplay";
CM_ SG_ 35 L_ATCU_CO2WrngDis "ATCU_CO2WarningDisplay";
CM_ BO_ 38 "[PE] Periodic and On Event";
CM_ SG_ 38 L_ATCU_3rdRrTempCDis "ATCU_3rdRearTemperature¡ÉDisplay";
CM_ SG_ 38 L_ATCU_3rdRrModDis "ATCU_3rdRearModeDisplay";
CM_ SG_ 38 L_ATCU_3rdRrBlwDis "ATCU_3rdRearBlowerDisplay";
CM_ SG_ 38 L_ATCU_3rdRrAutoDis "ATCU_3rdRearAutoDisplay";
CM_ SG_ 38 L_ATCU_3rdRrMultiAutoBlwDis "ATCU_3rdRearMultiAutoBlowerDisplay";
CM_ SG_ 38 L_ATCU_3rdRrSyncDis "ATCU_3rdRearSyncDisplay";
CM_ SG_ 38 L_ATCU_3rdRrOnInd "ATCU_3rdRearONIndicator";
CM_ SG_ 38 L_ATCU_3rdRrLockDis "ATCU_3rdRearLockDisplay";
CM_ SG_ 38 L_ATCU_3rdRrLcdBckLightSta "ATCU_3rdRearLCDBackLightStatus";
CM_ SG_ 38 L_ATCU_3rdRrGUIBlankDis "ATCU_3rdRearGUIBlankDisplay";
CM_ SG_ 38 L_ATCU_3rdRLStHeatSwHInd "ATCU_3rdRearLeftSeatHeatSwitchHighIndicator";
CM_ SG_ 38 L_ATCU_3rdRLStHeatSwMInd "ATCU_3rdRearLeftSeatHeatSwitchMiddleIndicator";
CM_ SG_ 38 L_ATCU_3rdRLStHeatSwLInd "ATCU_3rdRearLeftSeatHeatSwitchLowIndicator";
CM_ SG_ 38 L_ATCU_3rdRLStVntSwHInd "ATCU_3rdRearLeftSeatVentilationSwitchHighIndicator";
CM_ SG_ 38 L_ATCU_3rdRLStVntSwMInd "ATCU_3rdRearLeftSeatVentilationSwitchMiddleIndicator";
CM_ SG_ 38 L_ATCU_3rdRLStVntSwLInd "ATCU_3rdRearLeftSeatVentilationSwitchLowIndicator";
CM_ SG_ 38 L_ATCU_3rdRRStHeatSwHInd "ATCU_3rdRearRightSeatHeatSwitchHighIndicator";
CM_ SG_ 38 L_ATCU_3rdRRStHeatSwMInd "ATCU_3rdRearRightSeatHeatSwitchMiddleIndicator";
CM_ SG_ 38 L_ATCU_3rdRRStHeatSwLInd "ATCU_3rdRearRightSeatHeatSwitchLowIndicator";
CM_ SG_ 38 L_ATCU_3rdRRStVntSwHInd "ATCU_3rdRearRightSeatVentilationSwitchHighIndicator";
CM_ SG_ 38 L_ATCU_3rdRRStVntSwMInd "ATCU_3rdRearRightSeatVentilationSwitchMiddleIndicator";
CM_ SG_ 38 L_ATCU_3rdRRStVntSwLInd "ATCU_3rdRearRightSeatVentilationSwitchLowIndicator";
CM_ SG_ 38 L_ATCU_3rdRrMTCOpSta "ATCU_3rdRearMTCOperationStatus";
CM_ SG_ 38 L_ATCU_3rdRrMtcTempLvl "ATCU_3rdRearMTCTemperatureLevel";
CM_ SG_ 38 L_ATCU_3rdAUTOStep "ATCU_3rdAUTOStep";
CM_ SG_ 38 L_ATCU_RrPassMultiAutoBlwDis "ATCU_RrPassengerMultiAutoBlowerDisplay";
CM_ SG_ 38 L_ATCU_DisPnlState "ATCU_DisplayPanelState";
CM_ SG_ 38 L_ATCU_3rdRrTempFDis "ATCU_3rdRearTemperature¢µDisplay";
CM_ BO_ 39 "[P] Periodic";
CM_ SG_ 39 L_ATCU_RrHVACTempActrTgt "ATCU_RearHVACTemperatureActuatorTarget";
CM_ SG_ 39 L_ATCU_RrHVACTempAsstActrTgt "ATCU_RearHVCACTempAsstanceActuatorTarget";
CM_ SG_ 39 L_ATCU_RrDrHVACModeActrTgt "ATCU_RearDriverHVACModeActuatorTarget";
CM_ SG_ 39 L_ATCU_RrHVACBlowerTgtV "ATCU_RearHVACBlowerTargetVoltage";
CM_ SG_ 39 L_ATCU_RrHVACBLDCRpmVal "ATCU_RearHVAC BLDC Motor RPM Value";
CM_ SG_ 39 L_ATCU_RrPsHVACModeActrTgt "ATCU_RearPassengerHVACModeActuatorTarget";
CM_ BO_ 273 "[P] Periodic";
CM_ SG_ 273 L_ATCU_FHPTCOpPrmssnSta "ATCU_FHPTCOperationPermissionStatus";
CM_ SG_ 273 L_ATCU_FHPTCPassTrgtDty "ATCU_FHPTCPassengerTargetDuty";
CM_ SG_ 273 L_ATCU_FHPTCDischrgReq "ATCU_FHPTCDischrgeRequest";
CM_ SG_ 273 L_ATCU_FltMsgTmOutFHPTC1 "ATCU_FltMsgTmOutFHPTC1";
CM_ SG_ 273 L_ATCU_FltMsgTmOutFHPTC2 "ATCU_FltMsgTmOutFHPTC2";
CM_ SG_ 273 L_ATCU_FltMsgTmOutFHPTC3 "ATCU_FltMsgTmOutFHPTC3";
CM_ SG_ 273 L_ATCU_FltMsgTmOutFHPTC4 "ATCU_FltMsgTmOutFHPTC4";
CM_ SG_ 273 L_ATCU_FrBlwLvl "ATCU_FrBlowerLevel";
CM_ SG_ 273 L_ATCU_FrBlwLvlSigVaildSta "ATCU_FrBlowrLevelSignalVaildStatus";
CM_ SG_ 273 L_ATCU_DrvrSdTyp "ATCU_DriverSideType";
CM_ SG_ 273 L_ATCU_FrBlwFltSta "ATCU_FrontBlowerFaultStatus";
CM_ SG_ 273 L_ATCU_PassBlwLvl "ATCU_PasssengerBlowerLevel";
CM_ SG_ 273 L_ATCU_FHPTCDrTrgtDty "ATCU_FHPTCDriverTargetDuty";
CM_ BO_ 274 "[P] Periodic";
CM_ SG_ 274 L_ATCU_RHPTCOpPrmssnSta "ATCU_RHPTCOperationPermissionStatus";
CM_ SG_ 274 L_ATCU_RHPTCZone2TrgtDty "ATCU_RHPTCZone2TargetDuty";
CM_ SG_ 274 L_ATCU_RHPTCDischrgReq "ATCU_RHPTCDischrgeRequest";
CM_ SG_ 274 L_ATCU_FltMsgTmOutRHPTC1 "ATCU_FltMsgTmOutRHPTC1";
CM_ SG_ 274 L_ATCU_FltMsgTmOutRHPTC2 "ATCU_FltMsgTmOutRHPTC2";
CM_ SG_ 274 L_ATCU_FltMsgTmOutRHPTC3 "ATCU_FltMsgTmOutRHPTC3";
CM_ SG_ 274 L_ATCU_FltMsgTmOutRHPTC4 "ATCU_FltMsgTmOutRHPTC4";
CM_ SG_ 274 L_ATCU_RrBlwLvl "ATCU_RrBlowerLevel";
CM_ SG_ 274 L_ATCU_RrBlwLvlSigVaildSta "ATCU_RrBlowrLevelSignalVaildStatus";
CM_ SG_ 274 L_ATCU_RHPTCZone1TrgtDty "ATCU_RHPTCZone1TargetDuty";
CM_ SG_ 274 L_ATCU_RrBlwFltSta "ATCU_BlowerFaultStatus";
CM_ BO_ 275 "[P] Periodic";
CM_ SG_ 275 L_ATCU_PCMActTgtPos "Position Target for Fragrance Actuator";
CM_ SG_ 275 L_ATCU_VehPowerIGN2 "Status of Vehicle Ignition #2 Power";
CM_ SG_ 275 L_ATCU_VehPowerISGB "Status of Vehicle ISG B+ Power";
CM_ SG_ 275 L_ATCU_CurrentDy "Current day";
CM_ SG_ 275 L_ATCU_CurrentMon "Current month";
CM_ SG_ 275 L_ATCU_CurrentYrPre "Current year (Prefix 2 digits)";
CM_ SG_ 275 L_ATCU_CurrentYrPost "Current year (Postfix 2 digits)";
CM_ SG_ 275 L_ATCU_BlwrTgtOnOff "On/Off Target for Fragrance Blower";
CM_ SG_ 275 L_ATCU_VehPowerBatt "Status of Vehicle Battery Power";
CM_ SG_ 275 L_ATCU_VehPowerIGN1_3 "Status of Vehicle Ignition #1 Power";
CM_ BO_ 276 "[P] Periodic";
CM_ SG_ 276 L_ATCU_Volatilization_gmin "Volatilized coefficient for Current Fragrance kind and Strength";
CM_ SG_ 276 L_ATCU_Frag1Amount_g "Total Amount of Fragrance #1";
CM_ SG_ 276 L_ATCU_Frag2Amount_g "Total Amount of Fragrance #2";
CM_ SG_ 276 L_ATCU_Cart1ExpDate_year "Expiration date of Fragrance #1";
CM_ SG_ 276 L_ATCU_Cart2ExpDate_year "Expiration date of Fragrance #2";
CM_ BO_ 277 "[P] Periodic";
CM_ SG_ 277 L_ATCU_FHPTC2ndDrTrgtDty "ATCU_FHPTC 2nd Driver Target Duty";
CM_ SG_ 277 L_ATCU_FltMsgTmOutFHPTC5 "ATCU_FltMsgTmOutFHPTC5";
CM_ SG_ 277 L_ATCU_FltMsgTmOutFHPTC6 "ATCU_FltMsgTmOutFHPTC6";
CM_ SG_ 277 L_ATCU_FltMsgTmOutFHPTC7 "ATCU_FltMsgTmOutFHPTC7";
CM_ SG_ 277 L_ATCU_FltMsgTmOutFHPTC8 "ATCU_FltMsgTmOutFHPTC8";
CM_ SG_ 277 L_ATCU_2ndDrBlwLvl "ATCU_2ndDriverBlowerLevel";
CM_ SG_ 277 L_ATCU_2ndPsBlwLvl "ATCU_2ndPassengerBlowerLevel";
CM_ SG_ 277 L_ATCU_2ndBlwLvlSigVaildSta "ATCU_2ndBlowerLevelSignalVaildStatus";
CM_ SG_ 277 L_ATCU_2ndBlwFltSta "ATCU_2ndBlowerFaultStatus";
CM_ SG_ 277 L_ATCU_FHPTC2ndPsTrgtDty "ATCU_FHPTC 2nd Passenger Target Duty";
CM_ BO_ 278 "[PE] Periodic and On Event";
CM_ SG_ 278 L_ATCU_HU_MasterProfile_ResetIndex "L_ATCU_HUMasterProfile_ResetIndex";
CM_ SG_ 278 L_ATCU_HU_OptionInfo "Information of H/U functions";
CM_ BO_ 281 "[EC] On Event and On Change";
CM_ SG_ 281 L_ATCU_HU_FrDrEVntSidePt_X "Front Driver Electric Vent Side Touch Point  X Value";
CM_ SG_ 281 L_ATCU_HU_FrDrEVntSidePt_Y "Front Driver Electric Vent Side Touch Point  Y Value";
CM_ SG_ 281 L_ATCU_HU_FrDrEVntCtrPt_X "Front Driver Electric Vent Center Touch Point  X Value";
CM_ SG_ 281 L_ATCU_HU_FrDrEVntCtrPt_Y "Front Driver Electric Vent Center Touch Point  Y Value";
CM_ BO_ 305 "[EC] On Event and On Change";
CM_ SG_ 305 L_ATCU_HU_FrPsEVntSidePt_X "Front Passenger Electric Vent Side Touch Point  X Value";
CM_ SG_ 305 L_ATCU_HU_FrPsEVntSidePt_Y "Front Passenger Electric Vent Side Touch Point  Y Value";
CM_ SG_ 305 L_ATCU_HU_FrPsEVntCtrPt_X "Front Passenger Electric Center Vent Touch Point  X Value";
CM_ SG_ 305 L_ATCU_HU_FrPsEVntCtrPt_Y "Front Passenger Electric Center Vent Touch Point  Y Value";
CM_ BO_ 306 "[EC] On Event and On Change";
CM_ SG_ 306 L_ATCU_HU_RrDrEVntConsPt_X "Rear Driver Electric Vent Console Touch Point  X Value";
CM_ SG_ 306 L_ATCU_HU_RrDrEVntConsPt_Y "Rear Driver Electric Vent Console Touch Point  Y Value";
CM_ SG_ 306 L_ATCU_HU_RrPsEVntConsPt_X "Rear Passenger Electric Vent Console Touch Point  X Value";
CM_ SG_ 306 L_ATCU_HU_RrPsEVntConsPt_Y "Rear Passenger Electric Vent Console Touch Point  Y Value";
CM_ SG_ 306 L_ATCU_HU_RrDrEVntConsOpnCls "Rear Driver Electric Vent Console Open Close Signal";
CM_ SG_ 306 L_ATCU_HU_RrPsEVntConsOpnCls "Rear Passenger Electric Vent Console Open Close Signal";
CM_ SG_ 306 L_ATCU_HU_RrDrEVntModeSet "Rear Driver Electric Vent Mode Set";
CM_ SG_ 306 L_ATCU_HU_RrPsEVntModeSet "Rear Passenger Electric Vent Mode Set";
CM_ BO_ 304 "[P] Periodic";
CM_ SG_ 304 L_ATCU_CTS_RrDrEVntConsBdryUp_X "Rear Driver Electric Vent Console Boundary Upper X Point";
CM_ SG_ 304 L_ATCU_CTS_RrDrEVntConsBdryLo_X "Rear Driver Electric Vent Console Boundary Lower X Point";
CM_ SG_ 304 L_ATCU_CTS_RrDrEVntConsBdryLo_Y "Rear Driver Electric Vent Console Boundary Lower Y Point";
CM_ SG_ 304 L_ATCU_CTS_RrPsEVntConsBdryUp_X "Rear Passenger Electric Vent Console Boundary Upper X Point";
CM_ SG_ 304 L_ATCU_CTS_RrPsEVntConsBdryUp_Y "Rear Passenger Electric Vent Console Boundary Upper Y Point";
CM_ SG_ 304 L_ATCU_CTS_RrPsEVntConsBdryLo_X "Rear Passenger Electric Vent Console Boundary Lower X Point";
CM_ SG_ 304 L_ATCU_CTS_RrPsEVntConsBdryLo_Y "Rear Passenger Electric Vent Console Boundary Lower Y Point";
CM_ SG_ 304 L_ATCU_CTS_RrDrEVntConsBdryUp_Y "Rear Driver Electric Vent Console Boundary Upper Y Point";
CM_ BO_ 801 "[PE] Periodic and On Event";
CM_ SG_ 801 MON_LibMngrDrvMod "MON_LibraryManagerDriverMode";
CM_ SG_ 801 MON_LibMngrAC "MON_LiabraryManagerAC";
CM_ SG_ 801 MON_LibMngrActvIncarMotPwr "MON_LibraryManagerActiveIncarMotorPower";
CM_ SG_ 801 MON_LibMngrPDCWakeUpReq "MON_LibraryManagerPDCWakeUpRequest";
CM_ SG_ 801 MON_LibMngrLVPTCRly1State "MON_LibraryManagerLowVoltagePTCRelay1State";
CM_ SG_ 801 MON_LibMngrLVPTCRly2State "MON_LibraryManagerLowVoltagePTCRelay12tate";
CM_ SG_ 801 MON_LibMngrVRLedOpReq "MON_LibraryManagerVRLedOperationRequest";
CM_ SG_ 801 MON_LibMngrBlrVtg "MON_LibraryManagerBlowerVoltage";
CM_ SG_ 801 MON_LibMngrAstMod "MON_LibraryManagerAssistanceMode";
CM_ SG_ 801 MON_LibMngrDrvTmpDr "MON_LibraryManagerDriverTempDoor";
CM_ SG_ 801 MON_LibMngrAstTmpDr "MON_LibraryManagerAssistanceTempDoor";
CM_ SG_ 801 MON_LibMngrIntake "MON_LibraryManagerIntake";
CM_ BO_ 802 "[PE] Periodic and On Event";
CM_ SG_ 802 MON_LibMngrDEFDr "MON_LibraryManagerDEFDoor";
CM_ SG_ 802 MON_LibMngr2LHMod "MON_LibraryManager2LHMode";
CM_ SG_ 802 MON_LibMngrPwrSleep "MON_LibraryManagerPowerSleep";
CM_ SG_ 802 MON_LibMngr2LHBlrVtg "MON_LibraryManager2LHBlowerVoltage";
CM_ SG_ 802 MON_LibMngr2LHTmpDr "MON_LibraryManager2LHTempDoor";
CM_ SG_ 802 MON_LibMngr2LHBlrStep "MON_LibraryManager2LHBlowerStep";
CM_ BO_ 803 "[PE] Periodic and On Event";
CM_ SG_ 803 MON_LibFuncSysKeyState "MON_LibraryFuncSystemKeyState";
CM_ SG_ 803 MON_LibFuncSwBlrStatus "MON_LibraryFuncSwBlowerStatus";
CM_ SG_ 803 MON_LibFuncSwIntakeStatus "MON_LibraryFuncSwIntakeStauts";
CM_ SG_ 803 MON_LibFuncSwACStatus "MON_LibraryFuncSwACStatus";
CM_ SG_ 803 MON_LibFuncAutoSw "MON_LibraryFuncAutoSw";
CM_ SG_ 803 MON_LibFuncSwIntakeState "MON_LibraryFuncSwIntakeState";
CM_ SG_ 803 MON_LibFuncIntakeRECSw "MON_LibraryFuncIntakeRECSw";
CM_ SG_ 803 MON_LibFuncSwDrvTempStepState "MON_LibraryFuncSwDriverTempStepState";
CM_ SG_ 803 MON_LibFuncSwModState "MON_LibraryFuncSwModeState";
CM_ SG_ 803 MON_LibFunc2LHSwTempStepState "MON_LibraryFunc2LHSwTempStepState";
CM_ SG_ 803 MON_LibFuncIntakeFRESw "MON_LibraryFuncIntakeFRESw";
CM_ SG_ 803 MON_LibFunc2LHSwModStatus "MON_LibraryFunc2LHSWModeStatus";
CM_ SG_ 803 MON_LibFunc2LHBlowerProfileProhibit "MON_LibraryFunc2LHBlowerProfileProhibit";
CM_ SG_ 803 MON_LibFunc2LHSwModState "MON_LibraryFunc2LHSWModeState";
CM_ SG_ 803 MON_LibFunc2LHBlrStepState "MON_LibraryFunc2LHBlowerStepState";
CM_ SG_ 803 MON_LibFunc2LHAutoSw "MON_LibraryFunc2LHAutoSw";
CM_ SG_ 803 MON_LibFunc2LHSwBlrStatus "MON_LibraryFunc2LHSwBlowerStatus";
CM_ SG_ 803 MON_LibFuncSwModStatus "MON_LibraryFuncSwModStatus";
CM_ SG_ 803 MON_LibFuncBlrStepState "MON_LibraryFuncBlowerStepState";
CM_ BO_ 804 "[PE] Periodic and On Event";
CM_ SG_ 804 MON_LibFuncAMBFltrRstKeyOffTmr "MON_LibraryFuncAmbFilterResetKeyOffTimer";
CM_ SG_ 804 MON_LibFuncHotStart2LHBlrPrfleChgReq "MON_LibraryFuncHotStart2LHBlowerProfileChangeRequest";
CM_ SG_ 804 MON_LibFuncAmbFilterResetOpState "MON_LibraryFuncAmbFilterResetOperationState";
CM_ SG_ 804 MON_LibFuncDEFACState "MON_LibraryFuncDEFACState";
CM_ SG_ 804 MON_LibFuncETCIntlckHVActOffReq "MON_LibraryFuncETCInterlockHVActuatorOffRequest";
CM_ SG_ 804 MON_LibFuncHVACIntlckHVActOffReq "MON_LibraryFuncHVACInterlockHVActuatorOffRequest";
CM_ SG_ 804 MON_LibFuncMainRlyProtectOpState "MON_LibraryFuncMainRelayProtectOperationState";
CM_ SG_ 804 MON_LibFuncMIXACState "MON_LibraryFuncMIXACState";
CM_ SG_ 804 MON_LibFuncRmtFATCRmtState "MON_LibraryFuncRemoteFATCRemoteState";
CM_ SG_ 804 MON_LibFuncUSM_ADSState "MON_LibraryFuncUSM_ADSState";
CM_ SG_ 804 MON_LibFuncBlowerProfileProhibit "MON_LibraryFuncBlowerProfileProhibit";
CM_ BO_ 805 "[PE] Periodic and On Event";
CM_ SG_ 805 MON_LibMEMUSMROMWriteCmd "MON_LibraryMEMUSMROMWriteCmd";
CM_ SG_ 805 MON_LibMEMROMWriteMEM "MON_LibraryMEMROMWriteMEM";
CM_ BO_ 806 "[PE] Periodic and On Event";
CM_ SG_ 806 MON_LibFuncAfterBlowStandbyTime "MON_LibraryFuncAfterBlowStandbyTime";
CM_ SG_ 806 MON_LibFuncSchdldVentStandbyTime "MON_LibraryFuncScheduledVentStandbyTime";
CM_ BO_ 807 "[PE] Periodic and On Event";
CM_ SG_ 807 MON_LibFuncHICCSWVer "MON_LibraryFuncHICCSWVer";
CM_ BO_ 785 "[PE] Periodic and On Event";
CM_ SG_ 785 MON_StatMngr_ETC "ATCU Monitoring Test mode StateManagement Control (ETC)";
CM_ BO_ 786 "[PE] Periodic and On Event";
CM_ SG_ 786 MON_StatMngr_FuelEfficiency "ATCU Monitoring Test mode StateManagement Control (FuelEfficiency)";
CM_ BO_ 787 "[PE] Periodic and On Event";
CM_ SG_ 787 MON_StatMngr_Snsr "ATCU Monitoring Test mode StateManagement Control (Snsr)";
CM_ BO_ 788 "[PE] Periodic and On Event";
CM_ SG_ 788 MON_StatMngr_2ndHumid "ATCU Monitoring Test mode StateManagement Control (2ndHumid)";
CM_ BO_ 789 "[PE] Periodic and On Event";
CM_ SG_ 789 MON_StatMngr_2ndTemp "ATCU Monitoring Test mode StateManagement Control (2ndTemp)";
CM_ BO_ 790 "[PE] Periodic and On Event";
CM_ SG_ 790 MON_StatMngr_2ndSafetynCool "ATCU Monitoring Test mode StateManagement Control (2ndSafetynCool)";
CM_ BO_ 791 "[PE] Periodic and On Event";
CM_ SG_ 791 MON_StatMngr_2ndMngr "ATCU Monitoring Test mode StateManagement Control (2ndMngr)";
CM_ BO_ 817 "[PE] Periodic and On Event";
CM_ SG_ 817 L_ATCU_Sys_AutoDrvModState "ATCU System AutoLogic Driverside Mode";
CM_ SG_ 817 L_ATCU_Sys_AutoIntakeState "ATCU System AutoLogic Intake";
CM_ SG_ 817 L_ATCU_Sys_AutoACState "ATCU System AutoLogic AC";
CM_ SG_ 817 L_ATCU_Sys_AutoEvapTargetTemp "ATCU System AutoLogic Evap Target Temp";
CM_ SG_ 817 L_ATCU_Sys_AutoBlrVtgVal "ATCU System AutoLogic Blower Voltage";
CM_ BO_ 818 "[PE] Periodic and On Event";
CM_ SG_ 818 L_ATCU_Sys_AutoAstTargetTempVal "ATCU System AutoLogic Assistside Target Temp";
CM_ SG_ 818 L_ATCU_Sys_AutoAstTempDrState "ATCU System AutoLogic Assistside Temp Door";
CM_ SG_ 818 L_ATCU_Sys_AutoDrvTargetTempVal "ATCU System AutoLogic Driverside Target Temp";
CM_ SG_ 818 L_ATCU_Sys_AutoDrvTempDrState "ATCU System AutoLogic Driverside Temp Door";
CM_ BO_ 819 "[PE] Periodic and On Event";
CM_ SG_ 819 L_ATCU_Sys_Auto2LHBlrVtgVal "ATCU System AutoLogic 2nd Leftside Blower Voltage";
CM_ SG_ 819 L_ATCU_Sys_Auto2LHModState "ATCU System AutoLogic 2nd Leftside Mode";
CM_ SG_ 819 L_ATCU_Sys_Auto2LHTempDrState "ATCU System AutoLogic 2nd Leftside Temp Door";
CM_ SG_ 819 L_ATCU_Sys_AutoHeatloadStep "ATCU System AutoLogic Heatload Step";
CM_ SG_ 819 L_ATCU_Sys_AutoHVPTCDuty "ATCU System AutoLogic High Voltage PTC Duty";
CM_ SG_ 819 L_ATCU_Sys_AutoECompRpm "ATCU System AutoLogic Electric Comprossor RPM";
CM_ BO_ 820 "[PE] Periodic and On Event";
CM_ SG_ 820 L_ATCU_Sys_DrvMod "ATCU System Output Driverside Mode Door";
CM_ SG_ 820 L_ATCU_Sys_DEF "ATCU System Output DEF Door";
CM_ SG_ 820 L_ATCU_Sys_BlrStep "ATCU System Output Blower Step";
CM_ SG_ 820 L_ATCU_Sys_AstMod "ATCU System Output Assistside Mode Door";
CM_ SG_ 820 L_ATCU_Sys_Intake "ATCU System Output Intake Door";
CM_ SG_ 820 L_ATCU_Sys_AC "ATCU System Output AC";
CM_ SG_ 820 L_ATCU_Sys_HVPTCDuty "ATCU System Output High Voltage PTC Duty";
CM_ SG_ 820 L_ATCU_Sys_BlrVtg "ATCU System Output Blower Voltage";
CM_ BO_ 821 "[PE] Periodic and On Event";
CM_ SG_ 821 L_ATCU_Sys_EcompRPM "ATCU System Output E Compressor RPM";
CM_ SG_ 821 L_ATCU_Sys_EvapTargetTemp "ATCU System Output Evap Target Temp";
CM_ SG_ 821 L_ATCU_Sys_DrvTempDoor "ATCU System Output Driverside Temp Door";
CM_ SG_ 821 L_ATCU_Sys_AstTempDoor "ATCU System Output Assistside Temp Door";
CM_ BO_ 822 "[PE] Periodic and On Event";
CM_ SG_ 822 L_ATCU_Sys_2LHMod "ATCU System Output 2nd Leftside Mode Door";
CM_ SG_ 822 L_ATCU_Sys_2LHTempDoor "ATCU System Output 2nd Leftside Temp Door";
CM_ SG_ 822 L_ATCU_Sys_2LHBlrStep "ATCU System Output 2nd Leftside Blower Step";
CM_ SG_ 822 L_ATCU_Sys_2LHBlrVtg "ATCU System Output 2nd Leftside Blower Voltage";
BA_DEF_ BO_ "UsrMsgIDSforwardDeviation" INT 0 100 ;
BA_DEF_ BO_ "UsrMsgIDSbackwardDeviation" INT 50 1000 ;
BA_DEF_ "BusType" STRING ;
BA_DEF_ "DBName" STRING ;
BA_DEF_ "Baudrate" INT 50000 1000000 ;
BA_DEF_ "GenEnvVarEndingDsp" STRING ;
BA_DEF_ "GenEnvVarEndingSnd" STRING ;
BA_DEF_ "GenEnvVarPrefix" STRING ;
BA_DEF_ "GenNWMApBusSleep" STRING ;
BA_DEF_ "GenNWMApCanNormal" STRING ;
BA_DEF_ "GenNWMApCanOff" STRING ;
BA_DEF_ "GenNWMApCanOn" STRING ;
BA_DEF_ "GenNWMApCanSleep" STRING ;
BA_DEF_ "GenNWMApCanWakeUp" STRING ;
BA_DEF_ "GenNWMGotoMode_Awake" STRING ;
BA_DEF_ "GenNWMGotoMode_BusSleep" STRING ;
BA_DEF_ "GenNWMSleepTime" INT 1375 1650 ;
BA_DEF_ "GenNWMTalkNM" STRING ;
BA_DEF_ "Manufacturer" STRING ;
BA_DEF_ "NmBaseAddress" HEX 0 2047 ;
BA_DEF_ "NmMessageCount" INT 0 128 ;
BA_DEF_ "NmType" STRING ;
BA_DEF_ "SamplePointMax" INT 50 85 ;
BA_DEF_ "SamplePointMin" INT 55 85 ;
BA_DEF_ "SyncJumpWidthMax" INT 1 8 ;
BA_DEF_ "SyncJumpWidthMin" INT 1 4 ;
BA_DEF_ "VersionDay" INT 1 31 ;
BA_DEF_ "VersionMonth" INT 1 12 ;
BA_DEF_ "VersionNumber" INT 0 999999 ;
BA_DEF_ "VersionNumberInternal" INT 0 9999 ;
BA_DEF_ "VersionWeek" INT 1 53 ;
BA_DEF_ "VersionYear" INT 0 9999 ;
BA_DEF_ BU_ "NmStationAddress" HEX 0 255 ;
BA_DEF_ BU_ "NmNode" ENUM "No","Yes" ;
BA_DEF_ BU_ "GenNodSleepTime" INT 1375 1650 ;
BA_DEF_ BU_ "ILUsed" ENUM "No","Yes" ;
BA_DEF_ BU_ "NmCAN" INT 1 2 ;
BA_DEF_ BU_ "NodeLayerModules" STRING ;
BA_DEF_ BU_ "NWM_Knoten" ENUM "No","Yes" ;
BA_DEF_ BO_ "GenMsgCycleTime" INT 0 2000 ;
BA_DEF_ BO_ "GenMsgStartDelayTime" INT 0 2000 ;
BA_DEF_ BO_ "GenMsgSendType" ENUM "Cyclic","NoMsgSendType" ;
BA_DEF_ BO_ "GenMsgCycleTimeFast" INT 0 500 ;
BA_DEF_ BO_ "GenMsgDelayTime" INT 0 20 ;
BA_DEF_ BO_ "GenMsgILSupport" ENUM "No","Yes" ;
BA_DEF_ BO_ "GenMsgNrOfRepetition" INT 0 3 ;
BA_DEF_ BO_ "VFrameFormat" ENUM "StandardCAN","ExtendedCAN","reserved","reserved","reserved","reserved","reserved","reserved","reserved","reserved","reserved","reserved","reserved","reserved","StandardCAN_FD","ExtendedCAN_FD" ;
BA_DEF_ SG_ "UserSigValidity" ENUM "B+","ACC","IG","IG1","IG2","IG3","IG1 or IG2","IG1 or IG3","Undef" ;
BA_DEF_ SG_ "UsrSigPurpose" ENUM "Undef","FN","DIAG","DIAG(Req)","DIAG(Res)","DIAG(Phy)","DEV","CCP(Req)","CCP(Res)","NM","TP" ;
BA_DEF_ SG_ "GenSigStartValue" INT 0 1215752192 ;
BA_DEF_ SG_ "NetworkRequestHoldingTime" INT 0 65535 ;
BA_DEF_ SG_ "Description" STRING ;
BA_DEF_ SG_ "Version" STRING ;
BA_DEF_ SG_ "GenSigEnvVarType" ENUM "Int","Float","Undef" ;
BA_DEF_ SG_ "GenSigSendType" ENUM "Cyclic","OnWrite","OnWriteWithRepetition","OnChange","OnChangeWithRepetition","IfActive","IfActiveWithRepetition","NoSigSendType","OnChangeAndIfActive","OnChangeAndIfActiveWithRepetition" ;
BA_DEF_ SG_ "GwSigLatencyTime" INT 0 65536 ;
BA_DEF_ SG_ "GwSigMissingSourceType" ENUM "Undef","OldValue","DefaultValue","InitialValue" ;
BA_DEF_ SG_ "NWM-WakeupAllowed" ENUM "<n.a.>" ;
BA_DEF_ SG_ "RoutingFactor" INT 1 1215752192 ;
BA_DEF_REL_ BU_SG_REL_ "GenSigTimeoutTime" INT 0 7000 ;
BA_DEF_DEF_ "UsrMsgIDSforwardDeviation" 10 ;
BA_DEF_DEF_ "UsrMsgIDSbackwardDeviation" 100 ;
BA_DEF_DEF_ "BusType" "CAN" ;
BA_DEF_DEF_ "DBName" "" ;
BA_DEF_DEF_ "Baudrate" 500000 ;
BA_DEF_DEF_ "GenEnvVarEndingDsp" "Dsp_" ;
BA_DEF_DEF_ "GenEnvVarEndingSnd" "_" ;
BA_DEF_DEF_ "GenEnvVarPrefix" "Env" ;
BA_DEF_DEF_ "GenNWMApBusSleep" "AppNmCanBusSleep()" ;
BA_DEF_DEF_ "GenNWMApCanNormal" "AppNmCanNormal()" ;
BA_DEF_DEF_ "GenNWMApCanOff" "ApplCanOffline()" ;
BA_DEF_DEF_ "GenNWMApCanOn" "ApplCanOnline()" ;
BA_DEF_DEF_ "GenNWMApCanSleep" "ApplNmCanSleep()" ;
BA_DEF_DEF_ "GenNWMApCanWakeUp" "ApplCanWakeUp()" ;
BA_DEF_DEF_ "GenNWMGotoMode_Awake" "GotoMode_Awake()" ;
BA_DEF_DEF_ "GenNWMGotoMode_BusSleep" "GotoMode_BusSleep()" ;
BA_DEF_DEF_ "GenNWMSleepTime" 1500 ;
BA_DEF_DEF_ "GenNWMTalkNM" "TalkNM()" ;
BA_DEF_DEF_ "Manufacturer" "HMC" ;
BA_DEF_DEF_ "NmBaseAddress" 1280 ;
BA_DEF_DEF_ "NmMessageCount" 128 ;
BA_DEF_DEF_ "NmType" "Vector" ;
BA_DEF_DEF_ "SamplePointMax" 80 ;
BA_DEF_DEF_ "SamplePointMin" 80 ;
BA_DEF_DEF_ "SyncJumpWidthMax" 3 ;
BA_DEF_DEF_ "SyncJumpWidthMin" 2 ;
BA_DEF_DEF_ "VersionDay" 1 ;
BA_DEF_DEF_ "VersionMonth" 1 ;
BA_DEF_DEF_ "VersionNumber" 0 ;
BA_DEF_DEF_ "VersionNumberInternal" 0 ;
BA_DEF_DEF_ "VersionWeek" 1 ;
BA_DEF_DEF_ "VersionYear" 0 ;
BA_DEF_DEF_ "NmStationAddress" 0 ;
BA_DEF_DEF_ "NmNode" "Yes" ;
BA_DEF_DEF_ "GenNodSleepTime" 1500 ;
BA_DEF_DEF_ "ILUsed" "Yes" ;
BA_DEF_DEF_ "NmCAN" 1 ;
BA_DEF_DEF_ "NodeLayerModules" "oseknm01.dll,CANoeILNLVector.dll" ;
BA_DEF_DEF_ "NWM_Knoten" "Yes" ;
BA_DEF_DEF_ "GenMsgCycleTime" 200 ;
BA_DEF_DEF_ "GenMsgStartDelayTime" 0 ;
BA_DEF_DEF_ "GenMsgSendType" "NoMsgSendType" ;
BA_DEF_DEF_ "GenMsgCycleTimeFast" 40 ;
BA_DEF_DEF_ "GenMsgDelayTime" 20 ;
BA_DEF_DEF_ "GenMsgILSupport" "Yes" ;
BA_DEF_DEF_ "GenMsgNrOfRepetition" 3 ;
BA_DEF_DEF_ "VFrameFormat" "StandardCAN" ;
BA_DEF_DEF_ "UserSigValidity" "IG" ;
BA_DEF_DEF_ "UsrSigPurpose" "FN" ;
BA_DEF_DEF_ "GenSigStartValue" 0 ;
BA_DEF_DEF_ "NetworkRequestHoldingTime" 0 ;
BA_DEF_DEF_ "Description" "" ;
BA_DEF_DEF_ "Version" "" ;
BA_DEF_DEF_ "GenSigEnvVarType" "Undef" ;
BA_DEF_DEF_ "GenSigSendType" "NoSigSendType" ;
BA_DEF_DEF_ "GwSigLatencyTime" 40 ;
BA_DEF_DEF_ "GwSigMissingSourceType" "Undef" ;
BA_DEF_DEF_ "NWM-WakeupAllowed" "<n.a.>" ;
BA_DEF_DEF_ "RoutingFactor" 1 ;
BA_DEF_DEF_REL_ "GenSigTimeoutTime" 500 ;
BA_ "DBName" "Local_HS";
BA_ "VersionYear" 1;
BA_ "VersionNumber" 250801;
BA_ "NmNode" BU_ L_2HKBD 0;
BA_ "NmNode" BU_ L_ATCU 0;
BA_ "NmNode" BU_ L_ATCU_vMON 0;
BA_ "NmNode" BU_ L_3HKBD 0;
BA_ "GenMsgSendType" BO_ 33 0;
BA_ "GenMsgCycleTime" BO_ 33 500;
BA_ "NmNode" BU_ L_HKBD 0;
BA_ "Description" SG_ 33 L_ATCU_Typ1 "This signal includes regional information.";
BA_ "GenSigSendType" SG_ 33 L_ATCU_Typ1 4;
BA_ "UserSigValidity" SG_ 33 L_ATCU_Typ1 7;
BA_REL_ "GenSigTimeoutTime" BU_SG_REL_ L_HKBD SG_ 33 L_ATCU_Typ1 5000;
BA_ "Version" SG_ 33 L_ATCU_Typ1 "23.08.13";
BA_ "Description" SG_ 33 L_ATCU_Typ_All_2 "Bit0~1 (2nd Blower Control): 0???None / 1???Single / 2 - Dual / 3???(Reserved)

Bit2~3 (2nd TEMP Control): 0???None / 1???Single / 2 - Dual / 3???(Reserved)

Bit4~5 (2nd MODE Control): 0???None / 1???Single / 2 - Dual / 3???(Reserved)

Bit6~7 (2nd AUTO Control): 0???None / 1???Single / 2 - Dual / 3???(Reserved)";
BA_ "GenSigSendType" SG_ 33 L_ATCU_Typ_All_2 4;
BA_ "UserSigValidity" SG_ 33 L_ATCU_Typ_All_2 7;
BA_REL_ "GenSigTimeoutTime" BU_SG_REL_ L_2HKBD SG_ 33 L_ATCU_Typ_All_2 5000;
BA_REL_ "GenSigTimeoutTime" BU_SG_REL_ L_3HKBD SG_ 33 L_ATCU_Typ_All_2 5000;
BA_REL_ "GenSigTimeoutTime" BU_SG_REL_ L_HKBD SG_ 33 L_ATCU_Typ_All_2 5000;
BA_ "Version" SG_ 33 L_ATCU_Typ_All_2 "24.08.00";
BA_ "Description" SG_ 33 L_ATCU_TempDispSta "Temperature range options";
BA_ "GenSigSendType" SG_ 33 L_ATCU_TempDispSta 4;
BA_ "GenSigStartValue" SG_ 33 L_ATCU_TempDispSta 1;
BA_ "UserSigValidity" SG_ 33 L_ATCU_TempDispSta 7;
BA_REL_ "GenSigTimeoutTime" BU_SG_REL_ L_2HKBD SG_ 33 L_ATCU_TempDispSta 5000;
BA_REL_ "GenSigTimeoutTime" BU_SG_REL_ L_3HKBD SG_ 33 L_ATCU_TempDispSta 5000;
BA_REL_ "GenSigTimeoutTime" BU_SG_REL_ L_HKBD SG_ 33 L_ATCU_TempDispSta 5000;
BA_ "Version" SG_ 33 L_ATCU_TempDispSta "24.08.00";
BA_ "Description" SG_ 33 L_ATCU_StrgWhlHeatingOpt "Steering Wheel Heating Option : Used when receiving CAN signals (C_StrgWhlHeatingOpt @ICU/PDC). If the vehicle does not receive CAN, 0x3: Invalid transmission, unable to transmit singular information.";
BA_ "GenSigSendType" SG_ 33 L_ATCU_StrgWhlHeatingOpt 4;
BA_ "GenSigStartValue" SG_ 33 L_ATCU_StrgWhlHeatingOpt 3;
BA_ "UserSigValidity" SG_ 33 L_ATCU_StrgWhlHeatingOpt 7;
BA_REL_ "GenSigTimeoutTime" BU_SG_REL_ L_2HKBD SG_ 33 L_ATCU_StrgWhlHeatingOpt 5000;
BA_REL_ "GenSigTimeoutTime" BU_SG_REL_ L_3HKBD SG_ 33 L_ATCU_StrgWhlHeatingOpt 5000;
BA_REL_ "GenSigTimeoutTime" BU_SG_REL_ L_HKBD SG_ 33 L_ATCU_StrgWhlHeatingOpt 5000;
BA_ "Version" SG_ 33 L_ATCU_StrgWhlHeatingOpt "24.08.00";
BA_ "Description" SG_ 33 L_ATCU_Drv_SeatOptSta "Heater/ventilation option specification applied to Driver seat (LH side for LHD / RH side for RHD)";
BA_ "GenSigSendType" SG_ 33 L_ATCU_Drv_SeatOptSta 4;
BA_ "UserSigValidity" SG_ 33 L_ATCU_Drv_SeatOptSta 7;
BA_REL_ "GenSigTimeoutTime" BU_SG_REL_ L_2HKBD SG_ 33 L_ATCU_Drv_SeatOptSta 5000;
BA_REL_ "GenSigTimeoutTime" BU_SG_REL_ L_3HKBD SG_ 33 L_ATCU_Drv_SeatOptSta 5000;
BA_REL_ "GenSigTimeoutTime" BU_SG_REL_ L_HKBD SG_ 33 L_ATCU_Drv_SeatOptSta 5000;
BA_ "Version" SG_ 33 L_ATCU_Drv_SeatOptSta "23.08.13";
BA_ "Description" SG_ 33 L_ATCU_Ast_SeatOptSta "Heater/ventilation option specification applied to Driver seat (LH side for LHD / RH side for RHD)";
BA_ "GenSigSendType" SG_ 33 L_ATCU_Ast_SeatOptSta 4;
BA_ "UserSigValidity" SG_ 33 L_ATCU_Ast_SeatOptSta 7;
BA_REL_ "GenSigTimeoutTime" BU_SG_REL_ L_2HKBD SG_ 33 L_ATCU_Ast_SeatOptSta 5000;
BA_REL_ "GenSigTimeoutTime" BU_SG_REL_ L_3HKBD SG_ 33 L_ATCU_Ast_SeatOptSta 5000;
BA_REL_ "GenSigTimeoutTime" BU_SG_REL_ L_HKBD SG_ 33 L_ATCU_Ast_SeatOptSta 5000;
BA_ "Version" SG_ 33 L_ATCU_Ast_SeatOptSta "23.08.13";
BA_ "Description" SG_ 33 L_ATCU_RL_SeatOptSta "Heater/ventilation option specification applied to Driver seat (LH side for LHD / RH side for RHD)";
BA_ "GenSigSendType" SG_ 33 L_ATCU_RL_SeatOptSta 4;
BA_ "UserSigValidity" SG_ 33 L_ATCU_RL_SeatOptSta 7;
BA_REL_ "GenSigTimeoutTime" BU_SG_REL_ L_2HKBD SG_ 33 L_ATCU_RL_SeatOptSta 5000;
BA_REL_ "GenSigTimeoutTime" BU_SG_REL_ L_3HKBD SG_ 33 L_ATCU_RL_SeatOptSta 5000;
BA_REL_ "GenSigTimeoutTime" BU_SG_REL_ L_HKBD SG_ 33 L_ATCU_RL_SeatOptSta 5000;
BA_ "Version" SG_ 33 L_ATCU_RL_SeatOptSta "23.08.13";
BA_ "Description" SG_ 33 L_ATCU_RR_SeatOptSta "Heater/ventilation option specification applied to Driver seat (LH side for LHD / RH side for RHD)";
BA_ "GenSigSendType" SG_ 33 L_ATCU_RR_SeatOptSta 4;
BA_ "UserSigValidity" SG_ 33 L_ATCU_RR_SeatOptSta 7;
BA_REL_ "GenSigTimeoutTime" BU_SG_REL_ L_2HKBD SG_ 33 L_ATCU_RR_SeatOptSta 5000;
BA_REL_ "GenSigTimeoutTime" BU_SG_REL_ L_3HKBD SG_ 33 L_ATCU_RR_SeatOptSta 5000;
BA_REL_ "GenSigTimeoutTime" BU_SG_REL_ L_HKBD SG_ 33 L_ATCU_RR_SeatOptSta 5000;
BA_ "Version" SG_ 33 L_ATCU_RR_SeatOptSta "23.08.13";
BA_ "Description" SG_ 33 L_ATCU_SmartZoneDis "Smart HVAC SmartZone on/off signal";
BA_ "GenSigSendType" SG_ 33 L_ATCU_SmartZoneDis 4;
BA_ "UserSigValidity" SG_ 33 L_ATCU_SmartZoneDis 7;
BA_REL_ "GenSigTimeoutTime" BU_SG_REL_ L_HKBD SG_ 33 L_ATCU_SmartZoneDis 1500;
BA_ "Version" SG_ 33 L_ATCU_SmartZoneDis "24.11.00";
BA_ "Description" SG_ 33 L_ATCU_Typ_All_3 "Bit0~1 (3rd Blower Control): 0???None / 1???Single / 2 - Dual / 3???(Reserved)

Bit2~3 (3rd TEMP Control): 0???None / 1???Single / 2 - Dual / 3???(Reserved)

Bit4~5 (3rd MODE Control): 0???None / 1???Single / 2 - Dual / 3???(Reserved)

Bit6~7 (3rd AUTO Control): 0???None / 1???Single / 2 - Dual / 3???(Reserved)";
BA_ "GenSigSendType" SG_ 33 L_ATCU_Typ_All_3 4;
BA_ "UserSigValidity" SG_ 33 L_ATCU_Typ_All_3 7;
BA_REL_ "GenSigTimeoutTime" BU_SG_REL_ L_2HKBD SG_ 33 L_ATCU_Typ_All_3 5000;
BA_REL_ "GenSigTimeoutTime" BU_SG_REL_ L_3HKBD SG_ 33 L_ATCU_Typ_All_3 5000;
BA_REL_ "GenSigTimeoutTime" BU_SG_REL_ L_HKBD SG_ 33 L_ATCU_Typ_All_3 5000;
BA_ "Version" SG_ 33 L_ATCU_Typ_All_3 "24.08.00";
BA_ "Description" SG_ 33 L_ATCU_Typ_All_1 "Bit0~1 (Front Blower Control): 0 ? None / 1 ? Single / 2 - Dual / 3 ? (Reserved)

Bit2~3 (Front TEMP Control): 0 ? None / 1 ? Single / 2 - Dual / 3 ? (Reserved)

Bit4~5 (Front MODE Control): 0 ? None / 1 ? Single / 2 - Dual / 3 ? (Reserved)

Bit6~7 (Front AUTO Control): 0 ? None / 1 ? Single / 2 - Dual / 3 ? (Reserved)";
BA_ "GenSigSendType" SG_ 33 L_ATCU_Typ_All_1 4;
BA_ "UserSigValidity" SG_ 33 L_ATCU_Typ_All_1 7;
BA_REL_ "GenSigTimeoutTime" BU_SG_REL_ L_2HKBD SG_ 33 L_ATCU_Typ_All_1 5000;
BA_REL_ "GenSigTimeoutTime" BU_SG_REL_ L_3HKBD SG_ 33 L_ATCU_Typ_All_1 5000;
BA_REL_ "GenSigTimeoutTime" BU_SG_REL_ L_HKBD SG_ 33 L_ATCU_Typ_All_1 5000;
BA_ "Version" SG_ 33 L_ATCU_Typ_All_1 "24.08.00";
BA_ "GenMsgSendType" BO_ 34 0;
BA_ "Description" SG_ 34 L_ATCU_DrTempCDis "This signal indicates Outside temperature (¡É).

(Use for display only)";
BA_ "GenSigSendType" SG_ 34 L_ATCU_DrTempCDis 4;
BA_ "UserSigValidity" SG_ 34 L_ATCU_DrTempCDis 7;
BA_REL_ "GenSigTimeoutTime" BU_SG_REL_ L_HKBD SG_ 34 L_ATCU_DrTempCDis 1500;
BA_ "Version" SG_ 34 L_ATCU_DrTempCDis "23.08.13";
BA_ "GenSigSendType" SG_ 34 L_ATCU_DrTempFDis 4;
BA_ "UserSigValidity" SG_ 34 L_ATCU_DrTempFDis 7;
BA_REL_ "GenSigTimeoutTime" BU_SG_REL_ L_HKBD SG_ 34 L_ATCU_DrTempFDis 1500;
BA_ "Version" SG_ 34 L_ATCU_DrTempFDis "23.08.13";
BA_ "GenSigSendType" SG_ 34 L_ATCU_PassTempFDis 4;
BA_ "UserSigValidity" SG_ 34 L_ATCU_PassTempFDis 7;
BA_REL_ "GenSigTimeoutTime" BU_SG_REL_ L_HKBD SG_ 34 L_ATCU_PassTempFDis 1500;
BA_ "Version" SG_ 34 L_ATCU_PassTempFDis "23.08.13";
BA_ "NmNode" BU_ L_EVNT 0;
BA_ "Description" SG_ 34 L_ATCU_FrDrModDis "ATCU_FrontDriverModeDisplay";
BA_ "GenSigSendType" SG_ 34 L_ATCU_FrDrModDis 4;
BA_ "UserSigValidity" SG_ 34 L_ATCU_FrDrModDis 7;
BA_REL_ "GenSigTimeoutTime" BU_SG_REL_ L_EVNT SG_ 34 L_ATCU_FrDrModDis 1500;
BA_REL_ "GenSigTimeoutTime" BU_SG_REL_ L_HKBD SG_ 34 L_ATCU_FrDrModDis 1500;
BA_ "Version" SG_ 34 L_ATCU_FrDrModDis "24.05.08";
BA_ "Description" SG_ 34 L_ATCU_FrPassModDis "ATCU_FrontPassengerModeDisplay";
BA_ "GenSigSendType" SG_ 34 L_ATCU_FrPassModDis 4;
BA_ "UserSigValidity" SG_ 34 L_ATCU_FrPassModDis 7;
BA_REL_ "GenSigTimeoutTime" BU_SG_REL_ L_EVNT SG_ 34 L_ATCU_FrPassModDis 1500;
BA_REL_ "GenSigTimeoutTime" BU_SG_REL_ L_HKBD SG_ 34 L_ATCU_FrPassModDis 1500;
BA_ "Version" SG_ 34 L_ATCU_FrPassModDis "24.05.08";
BA_ "Description" SG_ 34 L_ATCU_FrDrBlwDis "This signal indicates step of Front Blower graphic.

This signal occurs when Front Blower siwtch(button) is selected either manually or automatically.";
BA_ "GenSigSendType" SG_ 34 L_ATCU_FrDrBlwDis 4;
BA_ "UserSigValidity" SG_ 34 L_ATCU_FrDrBlwDis 7;
BA_REL_ "GenSigTimeoutTime" BU_SG_REL_ L_HKBD SG_ 34 L_ATCU_FrDrBlwDis 1500;
BA_ "Version" SG_ 34 L_ATCU_FrDrBlwDis "23.08.13";
BA_ "GenSigSendType" SG_ 34 L_ATCU_FrPassBlwDis 4;
BA_ "UserSigValidity" SG_ 34 L_ATCU_FrPassBlwDis 7;
BA_REL_ "GenSigTimeoutTime" BU_SG_REL_ L_HKBD SG_ 34 L_ATCU_FrPassBlwDis 1500;
BA_ "Version" SG_ 34 L_ATCU_FrPassBlwDis "23.08.13";
BA_ "GenSigSendType" SG_ 34 L_ATCU_DrAutoDis 4;
BA_ "UserSigValidity" SG_ 34 L_ATCU_DrAutoDis 7;
BA_REL_ "GenSigTimeoutTime" BU_SG_REL_ L_HKBD SG_ 34 L_ATCU_DrAutoDis 1500;
BA_ "Version" SG_ 34 L_ATCU_DrAutoDis "23.08.13";
BA_ "GenSigSendType" SG_ 34 L_ATCU_PassAutoDis 4;
BA_ "UserSigValidity" SG_ 34 L_ATCU_PassAutoDis 7;
BA_REL_ "GenSigTimeoutTime" BU_SG_REL_ L_HKBD SG_ 34 L_ATCU_PassAutoDis 1500;
BA_ "Version" SG_ 34 L_ATCU_PassAutoDis "23.08.13";
BA_ "GenSigSendType" SG_ 34 L_ATCU_DrMultiAutoBlwDis 4;
BA_ "UserSigValidity" SG_ 34 L_ATCU_DrMultiAutoBlwDis 7;
BA_REL_ "GenSigTimeoutTime" BU_SG_REL_ L_HKBD SG_ 34 L_ATCU_DrMultiAutoBlwDis 1500;
BA_ "Version" SG_ 34 L_ATCU_DrMultiAutoBlwDis "23.08.13";
BA_ "GenSigSendType" SG_ 34 L_ATCU_PassMultiAutoBlwDis 4;
BA_ "UserSigValidity" SG_ 34 L_ATCU_PassMultiAutoBlwDis 7;
BA_REL_ "GenSigTimeoutTime" BU_SG_REL_ L_HKBD SG_ 34 L_ATCU_PassMultiAutoBlwDis 1500;
BA_ "Version" SG_ 34 L_ATCU_PassMultiAutoBlwDis "23.08.13";
BA_ "GenSigSendType" SG_ 34 L_ATCU_AcDis 4;
BA_ "UserSigValidity" SG_ 34 L_ATCU_AcDis 7;
BA_REL_ "GenSigTimeoutTime" BU_SG_REL_ L_HKBD SG_ 34 L_ATCU_AcDis 1500;
BA_ "Version" SG_ 34 L_ATCU_AcDis "23.08.13";
BA_ "GenSigSendType" SG_ 34 L_ATCU_IntakeDis 4;
BA_ "UserSigValidity" SG_ 34 L_ATCU_IntakeDis 7;
BA_REL_ "GenSigTimeoutTime" BU_SG_REL_ L_HKBD SG_ 34 L_ATCU_IntakeDis 1500;
BA_ "Version" SG_ 34 L_ATCU_IntakeDis "23.11.06";
BA_ "GenSigSendType" SG_ 34 L_ATCU_SyncDis 4;
BA_ "UserSigValidity" SG_ 34 L_ATCU_SyncDis 7;
BA_REL_ "GenSigTimeoutTime" BU_SG_REL_ L_HKBD SG_ 34 L_ATCU_SyncDis 1500;
BA_ "Version" SG_ 34 L_ATCU_SyncDis "23.08.13";
BA_ "GenSigSendType" SG_ 34 L_ATCU_FrDefDis 4;
BA_ "UserSigValidity" SG_ 34 L_ATCU_FrDefDis 7;
BA_REL_ "GenSigTimeoutTime" BU_SG_REL_ L_HKBD SG_ 34 L_ATCU_FrDefDis 1500;
BA_ "Version" SG_ 34 L_ATCU_FrDefDis "23.08.13";
BA_ "Description" SG_ 34 L_ATCU_PassTempCDis "This signal indicates Outside Temperature (¢µ)

(Use for display only)";
BA_ "GenSigSendType" SG_ 34 L_ATCU_PassTempCDis 4;
BA_ "UserSigValidity" SG_ 34 L_ATCU_PassTempCDis 7;
BA_REL_ "GenSigTimeoutTime" BU_SG_REL_ L_HKBD SG_ 34 L_ATCU_PassTempCDis 1500;
BA_ "Version" SG_ 34 L_ATCU_PassTempCDis "23.08.13";
BA_ "GenMsgSendType" BO_ 35 0;
BA_ "GenSigSendType" SG_ 35 L_ATCU_DrOnlyDis 4;
BA_ "UserSigValidity" SG_ 35 L_ATCU_DrOnlyDis 7;
BA_REL_ "GenSigTimeoutTime" BU_SG_REL_ L_EVNT SG_ 35 L_ATCU_DrOnlyDis 1500;
BA_REL_ "GenSigTimeoutTime" BU_SG_REL_ L_HKBD SG_ 35 L_ATCU_DrOnlyDis 1500;
BA_ "Version" SG_ 35 L_ATCU_DrOnlyDis "23.08.13";
BA_ "GenSigSendType" SG_ 35 L_ATCU_SmrtVntDis 4;
BA_ "UserSigValidity" SG_ 35 L_ATCU_SmrtVntDis 7;
BA_REL_ "GenSigTimeoutTime" BU_SG_REL_ L_HKBD SG_ 35 L_ATCU_SmrtVntDis 1500;
BA_ "Version" SG_ 35 L_ATCU_SmrtVntDis "23.08.13";
BA_ "GenSigSendType" SG_ 35 L_ATCU_FrWndShldHtInd 4;
BA_ "UserSigValidity" SG_ 35 L_ATCU_FrWndShldHtInd 7;
BA_REL_ "GenSigTimeoutTime" BU_SG_REL_ L_HKBD SG_ 35 L_ATCU_FrWndShldHtInd 1500;
BA_ "Version" SG_ 35 L_ATCU_FrWndShldHtInd "23.08.13";
BA_ "GenSigSendType" SG_ 35 L_ATCU_IncarMtrOnReq 4;
BA_ "UserSigValidity" SG_ 35 L_ATCU_IncarMtrOnReq 7;
BA_REL_ "GenSigTimeoutTime" BU_SG_REL_ L_HKBD SG_ 35 L_ATCU_IncarMtrOnReq 1500;
BA_ "Version" SG_ 35 L_ATCU_IncarMtrOnReq "23.11.06";
BA_ "Description" SG_ 35 L_ATCU_LanguageInfo "This signal indicates System Language information for Font display";
BA_ "GenSigSendType" SG_ 35 L_ATCU_LanguageInfo 4;
BA_ "GenSigStartValue" SG_ 35 L_ATCU_LanguageInfo 255;
BA_ "UserSigValidity" SG_ 35 L_ATCU_LanguageInfo 7;
BA_REL_ "GenSigTimeoutTime" BU_SG_REL_ L_HKBD SG_ 35 L_ATCU_LanguageInfo 1500;
BA_ "Version" SG_ 35 L_ATCU_LanguageInfo "24.01.00";
BA_ "GenSigSendType" SG_ 35 L_ATCU_RrDefInd 4;
BA_ "UserSigValidity" SG_ 35 L_ATCU_RrDefInd 7;
BA_REL_ "GenSigTimeoutTime" BU_SG_REL_ L_HKBD SG_ 35 L_ATCU_RrDefInd 1500;
BA_ "Version" SG_ 35 L_ATCU_RrDefInd "23.08.13";
BA_ "GenSigSendType" SG_ 35 L_ATCU_AfterBlowDisplay 4;
BA_ "UserSigValidity" SG_ 35 L_ATCU_AfterBlowDisplay 7;
BA_REL_ "GenSigTimeoutTime" BU_SG_REL_ L_HKBD SG_ 35 L_ATCU_AfterBlowDisplay 1500;
BA_ "Version" SG_ 35 L_ATCU_AfterBlowDisplay "23.11.09";
BA_ "Description" SG_ 35 L_ATCU_SchdldVentDisplay "Operate Blower based on set time and date by user for better cabin room ventilation.";
BA_ "GenSigSendType" SG_ 35 L_ATCU_SchdldVentDisplay 4;
BA_ "UserSigValidity" SG_ 35 L_ATCU_SchdldVentDisplay 7;
BA_REL_ "GenSigTimeoutTime" BU_SG_REL_ L_HKBD SG_ 35 L_ATCU_SchdldVentDisplay 1500;
BA_ "Version" SG_ 35 L_ATCU_SchdldVentDisplay "24.01.00";
BA_ "GenSigSendType" SG_ 35 L_ATCU_FLStHeatSwHInd 4;
BA_ "UserSigValidity" SG_ 35 L_ATCU_FLStHeatSwHInd 7;
BA_REL_ "GenSigTimeoutTime" BU_SG_REL_ L_HKBD SG_ 35 L_ATCU_FLStHeatSwHInd 1500;
BA_ "Version" SG_ 35 L_ATCU_FLStHeatSwHInd "23.08.13";
BA_ "GenSigSendType" SG_ 35 L_ATCU_FLStHeatSwMInd 4;
BA_ "UserSigValidity" SG_ 35 L_ATCU_FLStHeatSwMInd 7;
BA_REL_ "GenSigTimeoutTime" BU_SG_REL_ L_HKBD SG_ 35 L_ATCU_FLStHeatSwMInd 1500;
BA_ "Version" SG_ 35 L_ATCU_FLStHeatSwMInd "23.08.13";
BA_ "GenSigSendType" SG_ 35 L_ATCU_ADSBlinkDis 4;
BA_ "UserSigValidity" SG_ 35 L_ATCU_ADSBlinkDis 7;
BA_REL_ "GenSigTimeoutTime" BU_SG_REL_ L_HKBD SG_ 35 L_ATCU_ADSBlinkDis 1500;
BA_ "Version" SG_ 35 L_ATCU_ADSBlinkDis "23.08.13";
BA_ "GenSigSendType" SG_ 35 L_ATCU_FLStHeatSwLInd 4;
BA_ "UserSigValidity" SG_ 35 L_ATCU_FLStHeatSwLInd 7;
BA_REL_ "GenSigTimeoutTime" BU_SG_REL_ L_HKBD SG_ 35 L_ATCU_FLStHeatSwLInd 1500;
BA_ "Version" SG_ 35 L_ATCU_FLStHeatSwLInd "23.08.13";
BA_ "GenSigSendType" SG_ 35 L_ATCU_FLStVntSwHInd 4;
BA_ "UserSigValidity" SG_ 35 L_ATCU_FLStVntSwHInd 7;
BA_REL_ "GenSigTimeoutTime" BU_SG_REL_ L_HKBD SG_ 35 L_ATCU_FLStVntSwHInd 1500;
BA_ "Version" SG_ 35 L_ATCU_FLStVntSwHInd "23.08.13";
BA_ "GenSigSendType" SG_ 35 L_ATCU_FLStVntSwMInd 4;
BA_ "UserSigValidity" SG_ 35 L_ATCU_FLStVntSwMInd 7;
BA_REL_ "GenSigTimeoutTime" BU_SG_REL_ L_HKBD SG_ 35 L_ATCU_FLStVntSwMInd 1500;
BA_ "Version" SG_ 35 L_ATCU_FLStVntSwMInd "23.08.13";
BA_ "GenSigSendType" SG_ 35 L_ATCU_FLStVntSwLInd 4;
BA_ "UserSigValidity" SG_ 35 L_ATCU_FLStVntSwLInd 7;
BA_REL_ "GenSigTimeoutTime" BU_SG_REL_ L_HKBD SG_ 35 L_ATCU_FLStVntSwLInd 1500;
BA_ "Version" SG_ 35 L_ATCU_FLStVntSwLInd "23.08.13";
BA_ "GenSigSendType" SG_ 35 L_ATCU_FRStHeatSwHInd 4;
BA_ "UserSigValidity" SG_ 35 L_ATCU_FRStHeatSwHInd 7;
BA_REL_ "GenSigTimeoutTime" BU_SG_REL_ L_HKBD SG_ 35 L_ATCU_FRStHeatSwHInd 1500;
BA_ "Version" SG_ 35 L_ATCU_FRStHeatSwHInd "23.08.13";
BA_ "GenSigSendType" SG_ 35 L_ATCU_FRStHeatSwMInd 4;
BA_ "UserSigValidity" SG_ 35 L_ATCU_FRStHeatSwMInd 7;
BA_REL_ "GenSigTimeoutTime" BU_SG_REL_ L_HKBD SG_ 35 L_ATCU_FRStHeatSwMInd 1500;
BA_ "Version" SG_ 35 L_ATCU_FRStHeatSwMInd "23.08.13";
BA_ "GenSigSendType" SG_ 35 L_ATCU_FRStHeatSwLInd 4;
BA_ "UserSigValidity" SG_ 35 L_ATCU_FRStHeatSwLInd 7;
BA_REL_ "GenSigTimeoutTime" BU_SG_REL_ L_HKBD SG_ 35 L_ATCU_FRStHeatSwLInd 1500;
BA_ "Version" SG_ 35 L_ATCU_FRStHeatSwLInd "23.08.13";
BA_ "GenSigSendType" SG_ 35 L_ATCU_FRStVntSwHInd 4;
BA_ "UserSigValidity" SG_ 35 L_ATCU_FRStVntSwHInd 7;
BA_REL_ "GenSigTimeoutTime" BU_SG_REL_ L_HKBD SG_ 35 L_ATCU_FRStVntSwHInd 1500;
BA_ "Version" SG_ 35 L_ATCU_FRStVntSwHInd "23.08.13";
BA_ "GenSigSendType" SG_ 35 L_ATCU_FRStVntSwMInd 4;
BA_ "UserSigValidity" SG_ 35 L_ATCU_FRStVntSwMInd 7;
BA_REL_ "GenSigTimeoutTime" BU_SG_REL_ L_HKBD SG_ 35 L_ATCU_FRStVntSwMInd 1500;
BA_ "Version" SG_ 35 L_ATCU_FRStVntSwMInd "23.08.13";
BA_ "GenSigSendType" SG_ 35 L_ATCU_FRStVntSwLInd 4;
BA_ "UserSigValidity" SG_ 35 L_ATCU_FRStVntSwLInd 7;
BA_REL_ "GenSigTimeoutTime" BU_SG_REL_ L_HKBD SG_ 35 L_ATCU_FRStVntSwLInd 1500;
BA_ "Version" SG_ 35 L_ATCU_FRStVntSwLInd "23.08.13";
BA_ "Description" SG_ 35 L_ATCU_StrWhlHeatInd "This signal indicates the status of Steering Wheel Heater";
BA_ "GenSigSendType" SG_ 35 L_ATCU_StrWhlHeatInd 4;
BA_ "UserSigValidity" SG_ 35 L_ATCU_StrWhlHeatInd 7;
BA_REL_ "GenSigTimeoutTime" BU_SG_REL_ L_HKBD SG_ 35 L_ATCU_StrWhlHeatInd 1500;
BA_ "Version" SG_ 35 L_ATCU_StrWhlHeatInd "23.08.13";
BA_ "Description" SG_ 35 L_ATCU_RhstaLvlSta "This signal is used for a rheostat level of CLUSTER from 1 to 21 level (21 level:Detent) for a Unified Illumination System



¡Ø Start Value:Current Value";
BA_ "GenSigSendType" SG_ 35 L_ATCU_RhstaLvlSta 4;
BA_ "UserSigValidity" SG_ 35 L_ATCU_RhstaLvlSta 7;
BA_REL_ "GenSigTimeoutTime" BU_SG_REL_ L_2HKBD SG_ 35 L_ATCU_RhstaLvlSta 1500;
BA_REL_ "GenSigTimeoutTime" BU_SG_REL_ L_EVNT SG_ 35 L_ATCU_RhstaLvlSta 1500;
BA_REL_ "GenSigTimeoutTime" BU_SG_REL_ L_HKBD SG_ 35 L_ATCU_RhstaLvlSta 1500;
BA_ "Version" SG_ 35 L_ATCU_RhstaLvlSta "24.08.00";
BA_ "GenSigSendType" SG_ 35 L_ATCU_IntTailOnOff 4;
BA_ "UserSigValidity" SG_ 35 L_ATCU_IntTailOnOff 7;
BA_REL_ "GenSigTimeoutTime" BU_SG_REL_ L_2HKBD SG_ 35 L_ATCU_IntTailOnOff 1500;
BA_REL_ "GenSigTimeoutTime" BU_SG_REL_ L_HKBD SG_ 35 L_ATCU_IntTailOnOff 1500;
BA_ "Version" SG_ 35 L_ATCU_IntTailOnOff "23.08.13";
BA_ "Description" SG_ 35 L_ATCU_AutoLightSta "This signal indicates autolight sensor output";
BA_ "GenSigSendType" SG_ 35 L_ATCU_AutoLightSta 4;
BA_ "UserSigValidity" SG_ 35 L_ATCU_AutoLightSta 7;
BA_REL_ "GenSigTimeoutTime" BU_SG_REL_ L_HKBD SG_ 35 L_ATCU_AutoLightSta 1500;
BA_ "Version" SG_ 35 L_ATCU_AutoLightSta "23.08.13";
BA_ "GenSigSendType" SG_ 35 L_ATCU_FrBckLightSta 4;
BA_ "UserSigValidity" SG_ 35 L_ATCU_FrBckLightSta 7;
BA_REL_ "GenSigTimeoutTime" BU_SG_REL_ L_HKBD SG_ 35 L_ATCU_FrBckLightSta 1500;
BA_ "Version" SG_ 35 L_ATCU_FrBckLightSta "23.08.13";
BA_ "GenSigSendType" SG_ 35 L_ATCU_DisplayTheme 4;
BA_ "UserSigValidity" SG_ 35 L_ATCU_DisplayTheme 7;
BA_REL_ "GenSigTimeoutTime" BU_SG_REL_ L_HKBD SG_ 35 L_ATCU_DisplayTheme 1500;
BA_ "Version" SG_ 35 L_ATCU_DisplayTheme "23.08.13";
BA_ "GenSigSendType" SG_ 35 L_ATCU_GUIBlankDis 4;
BA_ "UserSigValidity" SG_ 35 L_ATCU_GUIBlankDis 7;
BA_REL_ "GenSigTimeoutTime" BU_SG_REL_ L_HKBD SG_ 35 L_ATCU_GUIBlankDis 1500;
BA_ "Version" SG_ 35 L_ATCU_GUIBlankDis "23.08.13";
BA_ "GenSigSendType" SG_ 35 L_ATCU_HptIntnstySet 4;
BA_ "UserSigValidity" SG_ 35 L_ATCU_HptIntnstySet 7;
BA_REL_ "GenSigTimeoutTime" BU_SG_REL_ L_HKBD SG_ 35 L_ATCU_HptIntnstySet 1500;
BA_ "Version" SG_ 35 L_ATCU_HptIntnstySet "23.11.06";
BA_ "Description" SG_ 35 L_ATCU_TlltLmpDis "This signal means information regarding Occupant status.

0) 00Xb:X position means PAB OFF Lamp indication. When this bit set as 1 PAB OFF lamp turns ON. 

    0Y0b:Y position means PAB ON Lamp indication. When this bit set as 1 PAB ON lamp turns ON.



1) Default value:0x2 (PAB ON Lamp on, PAB OFF Lamp off,)

2) Default value Transmit condition

    - When the input condition is not determined.

    - When the input condition is not supported.";
BA_ "GenSigSendType" SG_ 35 L_ATCU_TlltLmpDis 4;
BA_ "UserSigValidity" SG_ 35 L_ATCU_TlltLmpDis 7;
BA_REL_ "GenSigTimeoutTime" BU_SG_REL_ L_HKBD SG_ 35 L_ATCU_TlltLmpDis 1500;
BA_ "Version" SG_ 35 L_ATCU_TlltLmpDis "23.08.13";
BA_ "GenSigSendType" SG_ 35 L_ATCU_AvTailOnOff 4;
BA_ "UserSigValidity" SG_ 35 L_ATCU_AvTailOnOff 7;
BA_REL_ "GenSigTimeoutTime" BU_SG_REL_ L_HKBD SG_ 35 L_ATCU_AvTailOnOff 1500;
BA_ "Version" SG_ 35 L_ATCU_AvTailOnOff "23.08.13";
BA_ "Description" SG_ 35 L_ATCU_SchdldClimateDisplay "Operate Climate system based on set time and date by user in EV vehicle.";
BA_ "GenSigSendType" SG_ 35 L_ATCU_SchdldClimateDisplay 4;
BA_ "UserSigValidity" SG_ 35 L_ATCU_SchdldClimateDisplay 7;
BA_REL_ "GenSigTimeoutTime" BU_SG_REL_ L_HKBD SG_ 35 L_ATCU_SchdldClimateDisplay 1500;
BA_ "Version" SG_ 35 L_ATCU_SchdldClimateDisplay "24.01.00";
BA_ "GenSigSendType" SG_ 35 L_ATCU_AirClnDis 4;
BA_ "UserSigValidity" SG_ 35 L_ATCU_AirClnDis 7;
BA_REL_ "GenSigTimeoutTime" BU_SG_REL_ L_HKBD SG_ 35 L_ATCU_AirClnDis 1500;
BA_ "Version" SG_ 35 L_ATCU_AirClnDis "23.08.13";
BA_ "GenSigSendType" SG_ 35 L_ATCU_CO2WrngDis 4;
BA_ "UserSigValidity" SG_ 35 L_ATCU_CO2WrngDis 7;
BA_REL_ "GenSigTimeoutTime" BU_SG_REL_ L_HKBD SG_ 35 L_ATCU_CO2WrngDis 1500;
BA_ "Version" SG_ 35 L_ATCU_CO2WrngDis "23.08.13";
BA_ "NmNode" BU_ L_PCM 0;
BA_ "GenMsgSendType" BO_ 38 0;
BA_ "Description" SG_ 38 L_ATCU_3rdRrTempCDis "This signal indicates Outside temperature (¡É).

(Use for display only)";
BA_ "GenSigSendType" SG_ 38 L_ATCU_3rdRrTempCDis 4;
BA_ "UserSigValidity" SG_ 38 L_ATCU_3rdRrTempCDis 7;
BA_REL_ "GenSigTimeoutTime" BU_SG_REL_ L_3HKBD SG_ 38 L_ATCU_3rdRrTempCDis 1500;
BA_REL_ "GenSigTimeoutTime" BU_SG_REL_ L_HKBD SG_ 38 L_ATCU_3rdRrTempCDis 1500;
BA_ "Version" SG_ 38 L_ATCU_3rdRrTempCDis "23.08.13";
BA_ "GenSigSendType" SG_ 38 L_ATCU_3rdRrModDis 4;
BA_ "UserSigValidity" SG_ 38 L_ATCU_3rdRrModDis 7;
BA_REL_ "GenSigTimeoutTime" BU_SG_REL_ L_3HKBD SG_ 38 L_ATCU_3rdRrModDis 1500;
BA_REL_ "GenSigTimeoutTime" BU_SG_REL_ L_HKBD SG_ 38 L_ATCU_3rdRrModDis 1500;
BA_ "Version" SG_ 38 L_ATCU_3rdRrModDis "23.08.13";
BA_ "GenSigSendType" SG_ 38 L_ATCU_3rdRrBlwDis 4;
BA_ "UserSigValidity" SG_ 38 L_ATCU_3rdRrBlwDis 7;
BA_REL_ "GenSigTimeoutTime" BU_SG_REL_ L_3HKBD SG_ 38 L_ATCU_3rdRrBlwDis 1500;
BA_REL_ "GenSigTimeoutTime" BU_SG_REL_ L_HKBD SG_ 38 L_ATCU_3rdRrBlwDis 1500;
BA_ "Version" SG_ 38 L_ATCU_3rdRrBlwDis "23.08.13";
BA_ "GenSigSendType" SG_ 38 L_ATCU_3rdRrAutoDis 4;
BA_ "UserSigValidity" SG_ 38 L_ATCU_3rdRrAutoDis 7;
BA_REL_ "GenSigTimeoutTime" BU_SG_REL_ L_3HKBD SG_ 38 L_ATCU_3rdRrAutoDis 1500;
BA_REL_ "GenSigTimeoutTime" BU_SG_REL_ L_HKBD SG_ 38 L_ATCU_3rdRrAutoDis 1500;
BA_ "Version" SG_ 38 L_ATCU_3rdRrAutoDis "23.08.13";
BA_ "GenSigSendType" SG_ 38 L_ATCU_3rdRrMultiAutoBlwDis 4;
BA_ "UserSigValidity" SG_ 38 L_ATCU_3rdRrMultiAutoBlwDis 7;
BA_REL_ "GenSigTimeoutTime" BU_SG_REL_ L_3HKBD SG_ 38 L_ATCU_3rdRrMultiAutoBlwDis 1500;
BA_REL_ "GenSigTimeoutTime" BU_SG_REL_ L_HKBD SG_ 38 L_ATCU_3rdRrMultiAutoBlwDis 1500;
BA_ "Version" SG_ 38 L_ATCU_3rdRrMultiAutoBlwDis "23.08.13";
BA_ "GenSigSendType" SG_ 38 L_ATCU_3rdRrSyncDis 4;
BA_ "UserSigValidity" SG_ 38 L_ATCU_3rdRrSyncDis 7;
BA_REL_ "GenSigTimeoutTime" BU_SG_REL_ L_3HKBD SG_ 38 L_ATCU_3rdRrSyncDis 1500;
BA_REL_ "GenSigTimeoutTime" BU_SG_REL_ L_HKBD SG_ 38 L_ATCU_3rdRrSyncDis 1500;
BA_ "Version" SG_ 38 L_ATCU_3rdRrSyncDis "23.08.13";
BA_ "GenSigSendType" SG_ 38 L_ATCU_3rdRrOnInd 4;
BA_ "UserSigValidity" SG_ 38 L_ATCU_3rdRrOnInd 7;
BA_REL_ "GenSigTimeoutTime" BU_SG_REL_ L_3HKBD SG_ 38 L_ATCU_3rdRrOnInd 1500;
BA_REL_ "GenSigTimeoutTime" BU_SG_REL_ L_HKBD SG_ 38 L_ATCU_3rdRrOnInd 1500;
BA_ "Version" SG_ 38 L_ATCU_3rdRrOnInd "23.08.13";
BA_ "GenSigSendType" SG_ 38 L_ATCU_3rdRrLockDis 4;
BA_ "UserSigValidity" SG_ 38 L_ATCU_3rdRrLockDis 7;
BA_REL_ "GenSigTimeoutTime" BU_SG_REL_ L_3HKBD SG_ 38 L_ATCU_3rdRrLockDis 1500;
BA_REL_ "GenSigTimeoutTime" BU_SG_REL_ L_HKBD SG_ 38 L_ATCU_3rdRrLockDis 1500;
BA_ "Version" SG_ 38 L_ATCU_3rdRrLockDis "23.08.13";
BA_ "GenSigSendType" SG_ 38 L_ATCU_3rdRrLcdBckLightSta 4;
BA_ "UserSigValidity" SG_ 38 L_ATCU_3rdRrLcdBckLightSta 7;
BA_REL_ "GenSigTimeoutTime" BU_SG_REL_ L_3HKBD SG_ 38 L_ATCU_3rdRrLcdBckLightSta 1500;
BA_REL_ "GenSigTimeoutTime" BU_SG_REL_ L_HKBD SG_ 38 L_ATCU_3rdRrLcdBckLightSta 1500;
BA_ "Version" SG_ 38 L_ATCU_3rdRrLcdBckLightSta "23.08.13";
BA_ "GenSigSendType" SG_ 38 L_ATCU_3rdRrGUIBlankDis 4;
BA_ "UserSigValidity" SG_ 38 L_ATCU_3rdRrGUIBlankDis 7;
BA_REL_ "GenSigTimeoutTime" BU_SG_REL_ L_3HKBD SG_ 38 L_ATCU_3rdRrGUIBlankDis 1500;
BA_REL_ "GenSigTimeoutTime" BU_SG_REL_ L_HKBD SG_ 38 L_ATCU_3rdRrGUIBlankDis 1500;
BA_ "Version" SG_ 38 L_ATCU_3rdRrGUIBlankDis "23.08.13";
BA_ "GenSigSendType" SG_ 38 L_ATCU_3rdRLStHeatSwHInd 4;
BA_ "UserSigValidity" SG_ 38 L_ATCU_3rdRLStHeatSwHInd 7;
BA_REL_ "GenSigTimeoutTime" BU_SG_REL_ L_3HKBD SG_ 38 L_ATCU_3rdRLStHeatSwHInd 1500;
BA_REL_ "GenSigTimeoutTime" BU_SG_REL_ L_HKBD SG_ 38 L_ATCU_3rdRLStHeatSwHInd 1500;
BA_ "Version" SG_ 38 L_ATCU_3rdRLStHeatSwHInd "23.08.13";
BA_ "GenSigSendType" SG_ 38 L_ATCU_3rdRLStHeatSwMInd 4;
BA_ "UserSigValidity" SG_ 38 L_ATCU_3rdRLStHeatSwMInd 7;
BA_REL_ "GenSigTimeoutTime" BU_SG_REL_ L_3HKBD SG_ 38 L_ATCU_3rdRLStHeatSwMInd 1500;
BA_REL_ "GenSigTimeoutTime" BU_SG_REL_ L_HKBD SG_ 38 L_ATCU_3rdRLStHeatSwMInd 1500;
BA_ "Version" SG_ 38 L_ATCU_3rdRLStHeatSwMInd "23.08.13";
BA_ "GenSigSendType" SG_ 38 L_ATCU_3rdRLStHeatSwLInd 4;
BA_ "UserSigValidity" SG_ 38 L_ATCU_3rdRLStHeatSwLInd 7;
BA_REL_ "GenSigTimeoutTime" BU_SG_REL_ L_3HKBD SG_ 38 L_ATCU_3rdRLStHeatSwLInd 1500;
BA_REL_ "GenSigTimeoutTime" BU_SG_REL_ L_HKBD SG_ 38 L_ATCU_3rdRLStHeatSwLInd 1500;
BA_ "Version" SG_ 38 L_ATCU_3rdRLStHeatSwLInd "23.08.13";
BA_ "GenSigSendType" SG_ 38 L_ATCU_3rdRLStVntSwHInd 4;
BA_ "UserSigValidity" SG_ 38 L_ATCU_3rdRLStVntSwHInd 7;
BA_REL_ "GenSigTimeoutTime" BU_SG_REL_ L_3HKBD SG_ 38 L_ATCU_3rdRLStVntSwHInd 1500;
BA_REL_ "GenSigTimeoutTime" BU_SG_REL_ L_HKBD SG_ 38 L_ATCU_3rdRLStVntSwHInd 1500;
BA_ "Version" SG_ 38 L_ATCU_3rdRLStVntSwHInd "23.08.13";
BA_ "GenSigSendType" SG_ 38 L_ATCU_3rdRLStVntSwMInd 4;
BA_ "UserSigValidity" SG_ 38 L_ATCU_3rdRLStVntSwMInd 7;
BA_REL_ "GenSigTimeoutTime" BU_SG_REL_ L_3HKBD SG_ 38 L_ATCU_3rdRLStVntSwMInd 1500;
BA_REL_ "GenSigTimeoutTime" BU_SG_REL_ L_HKBD SG_ 38 L_ATCU_3rdRLStVntSwMInd 1500;
BA_ "Version" SG_ 38 L_ATCU_3rdRLStVntSwMInd "23.08.13";
BA_ "GenSigSendType" SG_ 38 L_ATCU_3rdRLStVntSwLInd 4;
BA_ "UserSigValidity" SG_ 38 L_ATCU_3rdRLStVntSwLInd 7;
BA_REL_ "GenSigTimeoutTime" BU_SG_REL_ L_3HKBD SG_ 38 L_ATCU_3rdRLStVntSwLInd 1500;
BA_REL_ "GenSigTimeoutTime" BU_SG_REL_ L_HKBD SG_ 38 L_ATCU_3rdRLStVntSwLInd 1500;
BA_ "Version" SG_ 38 L_ATCU_3rdRLStVntSwLInd "23.08.13";
BA_ "GenSigSendType" SG_ 38 L_ATCU_3rdRRStHeatSwHInd 4;
BA_ "UserSigValidity" SG_ 38 L_ATCU_3rdRRStHeatSwHInd 7;
BA_REL_ "GenSigTimeoutTime" BU_SG_REL_ L_3HKBD SG_ 38 L_ATCU_3rdRRStHeatSwHInd 1500;
BA_REL_ "GenSigTimeoutTime" BU_SG_REL_ L_HKBD SG_ 38 L_ATCU_3rdRRStHeatSwHInd 1500;
BA_ "Version" SG_ 38 L_ATCU_3rdRRStHeatSwHInd "23.08.13";
BA_ "GenSigSendType" SG_ 38 L_ATCU_3rdRRStHeatSwMInd 4;
BA_ "UserSigValidity" SG_ 38 L_ATCU_3rdRRStHeatSwMInd 7;
BA_REL_ "GenSigTimeoutTime" BU_SG_REL_ L_3HKBD SG_ 38 L_ATCU_3rdRRStHeatSwMInd 1500;
BA_REL_ "GenSigTimeoutTime" BU_SG_REL_ L_HKBD SG_ 38 L_ATCU_3rdRRStHeatSwMInd 1500;
BA_ "Version" SG_ 38 L_ATCU_3rdRRStHeatSwMInd "23.08.13";
BA_ "GenSigSendType" SG_ 38 L_ATCU_3rdRRStHeatSwLInd 4;
BA_ "UserSigValidity" SG_ 38 L_ATCU_3rdRRStHeatSwLInd 7;
BA_REL_ "GenSigTimeoutTime" BU_SG_REL_ L_3HKBD SG_ 38 L_ATCU_3rdRRStHeatSwLInd 1500;
BA_REL_ "GenSigTimeoutTime" BU_SG_REL_ L_HKBD SG_ 38 L_ATCU_3rdRRStHeatSwLInd 1500;
BA_ "Version" SG_ 38 L_ATCU_3rdRRStHeatSwLInd "23.08.13";
BA_ "GenSigSendType" SG_ 38 L_ATCU_3rdRRStVntSwHInd 4;
BA_ "UserSigValidity" SG_ 38 L_ATCU_3rdRRStVntSwHInd 7;
BA_REL_ "GenSigTimeoutTime" BU_SG_REL_ L_3HKBD SG_ 38 L_ATCU_3rdRRStVntSwHInd 1500;
BA_REL_ "GenSigTimeoutTime" BU_SG_REL_ L_HKBD SG_ 38 L_ATCU_3rdRRStVntSwHInd 1500;
BA_ "Version" SG_ 38 L_ATCU_3rdRRStVntSwHInd "23.08.13";
BA_ "GenSigSendType" SG_ 38 L_ATCU_3rdRRStVntSwMInd 4;
BA_ "UserSigValidity" SG_ 38 L_ATCU_3rdRRStVntSwMInd 7;
BA_REL_ "GenSigTimeoutTime" BU_SG_REL_ L_3HKBD SG_ 38 L_ATCU_3rdRRStVntSwMInd 1500;
BA_REL_ "GenSigTimeoutTime" BU_SG_REL_ L_HKBD SG_ 38 L_ATCU_3rdRRStVntSwMInd 1500;
BA_ "Version" SG_ 38 L_ATCU_3rdRRStVntSwMInd "23.08.13";
BA_ "GenSigSendType" SG_ 38 L_ATCU_3rdRRStVntSwLInd 4;
BA_ "UserSigValidity" SG_ 38 L_ATCU_3rdRRStVntSwLInd 7;
BA_REL_ "GenSigTimeoutTime" BU_SG_REL_ L_3HKBD SG_ 38 L_ATCU_3rdRRStVntSwLInd 1500;
BA_REL_ "GenSigTimeoutTime" BU_SG_REL_ L_HKBD SG_ 38 L_ATCU_3rdRRStVntSwLInd 1500;
BA_ "Version" SG_ 38 L_ATCU_3rdRRStVntSwLInd "23.08.13";
BA_ "GenSigSendType" SG_ 38 L_ATCU_3rdRrMTCOpSta 4;
BA_ "UserSigValidity" SG_ 38 L_ATCU_3rdRrMTCOpSta 7;
BA_REL_ "GenSigTimeoutTime" BU_SG_REL_ L_3HKBD SG_ 38 L_ATCU_3rdRrMTCOpSta 1500;
BA_REL_ "GenSigTimeoutTime" BU_SG_REL_ L_HKBD SG_ 38 L_ATCU_3rdRrMTCOpSta 1500;
BA_ "Version" SG_ 38 L_ATCU_3rdRrMTCOpSta "23.08.13";
BA_ "GenSigSendType" SG_ 38 L_ATCU_3rdRrMtcTempLvl 4;
BA_ "UserSigValidity" SG_ 38 L_ATCU_3rdRrMtcTempLvl 7;
BA_REL_ "GenSigTimeoutTime" BU_SG_REL_ L_3HKBD SG_ 38 L_ATCU_3rdRrMtcTempLvl 1500;
BA_REL_ "GenSigTimeoutTime" BU_SG_REL_ L_HKBD SG_ 38 L_ATCU_3rdRrMtcTempLvl 1500;
BA_ "Version" SG_ 38 L_ATCU_3rdRrMtcTempLvl "23.08.13";
BA_ "GenSigSendType" SG_ 38 L_ATCU_3rdAUTOStep 4;
BA_ "UserSigValidity" SG_ 38 L_ATCU_3rdAUTOStep 7;
BA_REL_ "GenSigTimeoutTime" BU_SG_REL_ L_3HKBD SG_ 38 L_ATCU_3rdAUTOStep 1500;
BA_REL_ "GenSigTimeoutTime" BU_SG_REL_ L_HKBD SG_ 38 L_ATCU_3rdAUTOStep 1500;
BA_ "Version" SG_ 38 L_ATCU_3rdAUTOStep "23.08.13";
BA_ "GenSigSendType" SG_ 38 L_ATCU_RrPassMultiAutoBlwDis 4;
BA_ "UserSigValidity" SG_ 38 L_ATCU_RrPassMultiAutoBlwDis 7;
BA_REL_ "GenSigTimeoutTime" BU_SG_REL_ L_2HKBD SG_ 38 L_ATCU_RrPassMultiAutoBlwDis 1500;
BA_REL_ "GenSigTimeoutTime" BU_SG_REL_ L_HKBD SG_ 38 L_ATCU_RrPassMultiAutoBlwDis 1500;
BA_ "Version" SG_ 38 L_ATCU_RrPassMultiAutoBlwDis "23.08.13";
BA_ "GenSigSendType" SG_ 38 L_ATCU_DisPnlState 4;
BA_ "UserSigValidity" SG_ 38 L_ATCU_DisPnlState 7;
BA_REL_ "GenSigTimeoutTime" BU_SG_REL_ L_HKBD SG_ 38 L_ATCU_DisPnlState 1500;
BA_ "Version" SG_ 38 L_ATCU_DisPnlState "24.02.08";
BA_ "Description" SG_ 38 L_ATCU_3rdRrTempFDis "This signal indicates Outside Temperature (¢µ)

(Use for display only)";
BA_ "GenSigSendType" SG_ 38 L_ATCU_3rdRrTempFDis 4;
BA_ "UserSigValidity" SG_ 38 L_ATCU_3rdRrTempFDis 7;
BA_REL_ "GenSigTimeoutTime" BU_SG_REL_ L_3HKBD SG_ 38 L_ATCU_3rdRrTempFDis 1500;
BA_REL_ "GenSigTimeoutTime" BU_SG_REL_ L_HKBD SG_ 38 L_ATCU_3rdRrTempFDis 1500;
BA_ "Version" SG_ 38 L_ATCU_3rdRrTempFDis "23.08.13";
BA_ "GenMsgSendType" BO_ 39 0;
BA_ "GenMsgCycleTime" BO_ 39 20;
BA_ "GenMsgCycleTimeFast" BO_ 39 0;
BA_ "GenMsgNrOfRepetition" BO_ 39 0;
BA_ "GenMsgDelayTime" BO_ 39 0;
BA_ "UserSigValidity" SG_ 39 L_ATCU_RrHVACTempActrTgt 7;
BA_ "Version" SG_ 39 L_ATCU_RrHVACTempActrTgt "23.08.13";
BA_ "UserSigValidity" SG_ 39 L_ATCU_RrHVACTempAsstActrTgt 7;
BA_ "Version" SG_ 39 L_ATCU_RrHVACTempAsstActrTgt "23.08.13";
BA_ "UserSigValidity" SG_ 39 L_ATCU_RrDrHVACModeActrTgt 7;
BA_ "Version" SG_ 39 L_ATCU_RrDrHVACModeActrTgt "24.02.01";
BA_ "UserSigValidity" SG_ 39 L_ATCU_RrHVACBlowerTgtV 7;
BA_ "Version" SG_ 39 L_ATCU_RrHVACBlowerTgtV "23.08.13";
BA_ "UserSigValidity" SG_ 39 L_ATCU_RrHVACBLDCRpmVal 7;
BA_ "Version" SG_ 39 L_ATCU_RrHVACBLDCRpmVal "24.02.01";
BA_ "UserSigValidity" SG_ 39 L_ATCU_RrPsHVACModeActrTgt 7;
BA_ "Version" SG_ 39 L_ATCU_RrPsHVACModeActrTgt "24.02.01";
BA_ "NmNode" BU_ L_FHPTC 0;
BA_ "NmNode" BU_ L_RHPTC 0;
BA_ "GenMsgSendType" BO_ 273 0;
BA_ "GenMsgCycleTime" BO_ 273 20;
BA_ "GenMsgCycleTimeFast" BO_ 273 0;
BA_ "GenMsgNrOfRepetition" BO_ 273 0;
BA_ "GenMsgDelayTime" BO_ 273 0;
BA_ "UserSigValidity" SG_ 273 L_ATCU_FHPTCOpPrmssnSta 7;
BA_ "Version" SG_ 273 L_ATCU_FHPTCOpPrmssnSta "23.08.13";
BA_ "UserSigValidity" SG_ 273 L_ATCU_FHPTCPassTrgtDty 7;
BA_ "Version" SG_ 273 L_ATCU_FHPTCPassTrgtDty "23.08.13";
BA_ "UserSigValidity" SG_ 273 L_ATCU_FHPTCDischrgReq 7;
BA_ "Version" SG_ 273 L_ATCU_FHPTCDischrgReq "23.08.13";
BA_ "Description" SG_ 273 L_ATCU_FltMsgTmOutFHPTC1 "Message Timeout of FHPTC_01";
BA_ "UserSigValidity" SG_ 273 L_ATCU_FltMsgTmOutFHPTC1 7;
BA_ "Version" SG_ 273 L_ATCU_FltMsgTmOutFHPTC1 "23.08.13";
BA_ "Description" SG_ 273 L_ATCU_FltMsgTmOutFHPTC2 "Message Timeout of FHPTC_02";
BA_ "UserSigValidity" SG_ 273 L_ATCU_FltMsgTmOutFHPTC2 7;
BA_ "Version" SG_ 273 L_ATCU_FltMsgTmOutFHPTC2 "23.08.13";
BA_ "Description" SG_ 273 L_ATCU_FltMsgTmOutFHPTC3 "Message Timeout of FHPTC_03";
BA_ "UserSigValidity" SG_ 273 L_ATCU_FltMsgTmOutFHPTC3 7;
BA_ "Version" SG_ 273 L_ATCU_FltMsgTmOutFHPTC3 "23.08.13";
BA_ "Description" SG_ 273 L_ATCU_FltMsgTmOutFHPTC4 "Message Timeout of FHPTC_04";
BA_ "UserSigValidity" SG_ 273 L_ATCU_FltMsgTmOutFHPTC4 7;
BA_ "Version" SG_ 273 L_ATCU_FltMsgTmOutFHPTC4 "23.08.13";
BA_ "Description" SG_ 273 L_ATCU_FrBlwLvl "This signal indicates step of Front blower operation";
BA_ "UserSigValidity" SG_ 273 L_ATCU_FrBlwLvl 7;
BA_ "Version" SG_ 273 L_ATCU_FrBlwLvl "23.08.13";
BA_ "Description" SG_ 273 L_ATCU_FrBlwLvlSigVaildSta "This signal sindicates the validation of 'blower level signal'

Initial value is 0x0(Invalid, do not send information of blower level)";
BA_ "UserSigValidity" SG_ 273 L_ATCU_FrBlwLvlSigVaildSta 7;
BA_ "Version" SG_ 273 L_ATCU_FrBlwLvlSigVaildSta "23.08.13";
BA_ "Description" SG_ 273 L_ATCU_DrvrSdTyp "This signal indicates information of driver type (LHD/RHD)";
BA_ "UserSigValidity" SG_ 273 L_ATCU_DrvrSdTyp 7;
BA_ "Version" SG_ 273 L_ATCU_DrvrSdTyp "23.08.13";
BA_ "UserSigValidity" SG_ 273 L_ATCU_FrBlwFltSta 7;
BA_ "Version" SG_ 273 L_ATCU_FrBlwFltSta "23.08.13";
BA_ "UserSigValidity" SG_ 273 L_ATCU_PassBlwLvl 7;
BA_ "Version" SG_ 273 L_ATCU_PassBlwLvl "23.08.13";
BA_ "UserSigValidity" SG_ 273 L_ATCU_FHPTCDrTrgtDty 7;
BA_ "Version" SG_ 273 L_ATCU_FHPTCDrTrgtDty "23.08.13";
BA_ "GenMsgSendType" BO_ 274 0;
BA_ "GenMsgCycleTime" BO_ 274 20;
BA_ "GenMsgCycleTimeFast" BO_ 274 0;
BA_ "GenMsgNrOfRepetition" BO_ 274 0;
BA_ "GenMsgDelayTime" BO_ 274 0;
BA_ "UserSigValidity" SG_ 274 L_ATCU_RHPTCOpPrmssnSta 7;
BA_ "Version" SG_ 274 L_ATCU_RHPTCOpPrmssnSta "23.08.13";
BA_ "Description" SG_ 274 L_ATCU_RHPTCZone2TrgtDty "Zone2 : Ps or Floor";
BA_ "UserSigValidity" SG_ 274 L_ATCU_RHPTCZone2TrgtDty 7;
BA_ "Version" SG_ 274 L_ATCU_RHPTCZone2TrgtDty "24.02.01";
BA_ "UserSigValidity" SG_ 274 L_ATCU_RHPTCDischrgReq 7;
BA_ "Version" SG_ 274 L_ATCU_RHPTCDischrgReq "23.08.13";
BA_ "Description" SG_ 274 L_ATCU_FltMsgTmOutRHPTC1 "Message Timeout of RHPTC_01";
BA_ "UserSigValidity" SG_ 274 L_ATCU_FltMsgTmOutRHPTC1 7;
BA_ "Version" SG_ 274 L_ATCU_FltMsgTmOutRHPTC1 "23.08.13";
BA_ "Description" SG_ 274 L_ATCU_FltMsgTmOutRHPTC2 "Message Timeout of RHPTC_02";
BA_ "UserSigValidity" SG_ 274 L_ATCU_FltMsgTmOutRHPTC2 7;
BA_ "Version" SG_ 274 L_ATCU_FltMsgTmOutRHPTC2 "23.08.13";
BA_ "Description" SG_ 274 L_ATCU_FltMsgTmOutRHPTC3 "Message Timeout of RHPTC_03";
BA_ "UserSigValidity" SG_ 274 L_ATCU_FltMsgTmOutRHPTC3 7;
BA_ "Version" SG_ 274 L_ATCU_FltMsgTmOutRHPTC3 "23.08.13";
BA_ "Description" SG_ 274 L_ATCU_FltMsgTmOutRHPTC4 "Message Timeout of RHPTC_04";
BA_ "UserSigValidity" SG_ 274 L_ATCU_FltMsgTmOutRHPTC4 7;
BA_ "Version" SG_ 274 L_ATCU_FltMsgTmOutRHPTC4 "23.08.13";
BA_ "Description" SG_ 274 L_ATCU_RrBlwLvl "This signal indicates step of Rear blower operation";
BA_ "UserSigValidity" SG_ 274 L_ATCU_RrBlwLvl 7;
BA_ "Version" SG_ 274 L_ATCU_RrBlwLvl "23.08.13";
BA_ "Description" SG_ 274 L_ATCU_RrBlwLvlSigVaildSta "This signal sindicates the validation of 'blower level signal'

Initial value is 0x0(Invalid, do not send information of blower level)";
BA_ "UserSigValidity" SG_ 274 L_ATCU_RrBlwLvlSigVaildSta 7;
BA_ "Version" SG_ 274 L_ATCU_RrBlwLvlSigVaildSta "23.08.13";
BA_ "Description" SG_ 274 L_ATCU_RHPTCZone1TrgtDty "Zone1 : Dr or Roof";
BA_ "UserSigValidity" SG_ 274 L_ATCU_RHPTCZone1TrgtDty 7;
BA_ "Version" SG_ 274 L_ATCU_RHPTCZone1TrgtDty "24.02.01";
BA_ "UserSigValidity" SG_ 274 L_ATCU_RrBlwFltSta 7;
BA_ "Version" SG_ 274 L_ATCU_RrBlwFltSta "23.08.13";
BA_ "GenMsgSendType" BO_ 275 0;
BA_ "GenMsgCycleTime" BO_ 275 20;
BA_ "GenMsgCycleTimeFast" BO_ 275 0;
BA_ "GenMsgNrOfRepetition" BO_ 275 0;
BA_ "GenMsgDelayTime" BO_ 275 0;
BA_ "UserSigValidity" SG_ 275 L_ATCU_PCMActTgtPos 7;
BA_ "Version" SG_ 275 L_ATCU_PCMActTgtPos "24.02.06";
BA_ "UserSigValidity" SG_ 275 L_ATCU_VehPowerIGN2 7;
BA_ "Version" SG_ 275 L_ATCU_VehPowerIGN2 "24.02.06";
BA_ "UserSigValidity" SG_ 275 L_ATCU_VehPowerISGB 7;
BA_ "Version" SG_ 275 L_ATCU_VehPowerISGB "24.02.06";
BA_ "UserSigValidity" SG_ 275 L_ATCU_CurrentDy 7;
BA_ "Version" SG_ 275 L_ATCU_CurrentDy "24.02.06";
BA_ "UserSigValidity" SG_ 275 L_ATCU_CurrentMon 7;
BA_ "Version" SG_ 275 L_ATCU_CurrentMon "24.02.06";
BA_ "UserSigValidity" SG_ 275 L_ATCU_CurrentYrPre 7;
BA_ "Version" SG_ 275 L_ATCU_CurrentYrPre "24.02.06";
BA_ "UserSigValidity" SG_ 275 L_ATCU_CurrentYrPost 7;
BA_ "Version" SG_ 275 L_ATCU_CurrentYrPost "24.02.06";
BA_ "UserSigValidity" SG_ 275 L_ATCU_BlwrTgtOnOff 7;
BA_ "Version" SG_ 275 L_ATCU_BlwrTgtOnOff "24.02.06";
BA_ "UserSigValidity" SG_ 275 L_ATCU_VehPowerBatt 7;
BA_ "Version" SG_ 275 L_ATCU_VehPowerBatt "24.02.06";
BA_ "UserSigValidity" SG_ 275 L_ATCU_VehPowerIGN1_3 7;
BA_ "Version" SG_ 275 L_ATCU_VehPowerIGN1_3 "24.02.06";
BA_ "GenMsgSendType" BO_ 276 0;
BA_ "GenMsgCycleTime" BO_ 276 20;
BA_ "GenMsgCycleTimeFast" BO_ 276 0;
BA_ "GenMsgNrOfRepetition" BO_ 276 0;
BA_ "GenMsgDelayTime" BO_ 276 0;
BA_ "UserSigValidity" SG_ 276 L_ATCU_Volatilization_gmin 7;
BA_ "Version" SG_ 276 L_ATCU_Volatilization_gmin "24.02.06";
BA_ "UserSigValidity" SG_ 276 L_ATCU_Frag1Amount_g 7;
BA_ "Version" SG_ 276 L_ATCU_Frag1Amount_g "24.02.06";
BA_ "UserSigValidity" SG_ 276 L_ATCU_Frag2Amount_g 7;
BA_ "Version" SG_ 276 L_ATCU_Frag2Amount_g "24.02.06";
BA_ "UserSigValidity" SG_ 276 L_ATCU_Cart1ExpDate_year 7;
BA_ "Version" SG_ 276 L_ATCU_Cart1ExpDate_year "24.02.06";
BA_ "UserSigValidity" SG_ 276 L_ATCU_Cart2ExpDate_year 7;
BA_ "Version" SG_ 276 L_ATCU_Cart2ExpDate_year "24.02.06";
BA_ "GenMsgSendType" BO_ 277 0;
BA_ "GenMsgCycleTime" BO_ 277 20;
BA_ "GenMsgCycleTimeFast" BO_ 277 0;
BA_ "GenMsgNrOfRepetition" BO_ 277 0;
BA_ "GenMsgDelayTime" BO_ 277 0;
BA_ "UserSigValidity" SG_ 277 L_ATCU_FHPTC2ndDrTrgtDty 7;
BA_ "Version" SG_ 277 L_ATCU_FHPTC2ndDrTrgtDty "24.02.06";
BA_ "Description" SG_ 277 L_ATCU_FltMsgTmOutFHPTC5 "Message Timeout of FHPTC_05";
BA_ "UserSigValidity" SG_ 277 L_ATCU_FltMsgTmOutFHPTC5 7;
BA_ "Version" SG_ 277 L_ATCU_FltMsgTmOutFHPTC5 "24.02.06";
BA_ "Description" SG_ 277 L_ATCU_FltMsgTmOutFHPTC6 "Message Timeout of FHPTC_06";
BA_ "UserSigValidity" SG_ 277 L_ATCU_FltMsgTmOutFHPTC6 7;
BA_ "Version" SG_ 277 L_ATCU_FltMsgTmOutFHPTC6 "24.02.06";
BA_ "Description" SG_ 277 L_ATCU_FltMsgTmOutFHPTC7 "Message Timeout of FHPTC_07";
BA_ "UserSigValidity" SG_ 277 L_ATCU_FltMsgTmOutFHPTC7 7;
BA_ "Version" SG_ 277 L_ATCU_FltMsgTmOutFHPTC7 "24.02.06";
BA_ "Description" SG_ 277 L_ATCU_FltMsgTmOutFHPTC8 "Message Timeout of FHPTC_08";
BA_ "UserSigValidity" SG_ 277 L_ATCU_FltMsgTmOutFHPTC8 7;
BA_ "Version" SG_ 277 L_ATCU_FltMsgTmOutFHPTC8 "24.02.06";
BA_ "Description" SG_ 277 L_ATCU_2ndDrBlwLvl "This signal indicates step of driver side Console blower operation";
BA_ "UserSigValidity" SG_ 277 L_ATCU_2ndDrBlwLvl 7;
BA_ "Version" SG_ 277 L_ATCU_2ndDrBlwLvl "24.05.08";
BA_ "Description" SG_ 277 L_ATCU_2ndPsBlwLvl "This signal indicates step of passenger side Console blower operation";
BA_ "UserSigValidity" SG_ 277 L_ATCU_2ndPsBlwLvl 7;
BA_ "Version" SG_ 277 L_ATCU_2ndPsBlwLvl "24.05.08";
BA_ "Description" SG_ 277 L_ATCU_2ndBlwLvlSigVaildSta "This signal sindicates the validation of 'blower level signal'

Initial value is 0x0(Invalid, do not send information of blower level)";
BA_ "UserSigValidity" SG_ 277 L_ATCU_2ndBlwLvlSigVaildSta 7;
BA_ "Version" SG_ 277 L_ATCU_2ndBlwLvlSigVaildSta "24.02.06";
BA_ "UserSigValidity" SG_ 277 L_ATCU_2ndBlwFltSta 7;
BA_ "Version" SG_ 277 L_ATCU_2ndBlwFltSta "24.02.06";
BA_ "UserSigValidity" SG_ 277 L_ATCU_FHPTC2ndPsTrgtDty 7;
BA_ "Version" SG_ 277 L_ATCU_FHPTC2ndPsTrgtDty "24.02.06";
BA_ "GenMsgSendType" BO_ 278 0;
BA_ "GenSigSendType" SG_ 278 L_ATCU_HU_MasterProfile_ResetIndex 4;
BA_ "UserSigValidity" SG_ 278 L_ATCU_HU_MasterProfile_ResetIndex 7;
BA_REL_ "GenSigTimeoutTime" BU_SG_REL_ L_2HKBD SG_ 278 L_ATCU_HU_MasterProfile_ResetIndex 1500;
BA_REL_ "GenSigTimeoutTime" BU_SG_REL_ L_3HKBD SG_ 278 L_ATCU_HU_MasterProfile_ResetIndex 1500;
BA_REL_ "GenSigTimeoutTime" BU_SG_REL_ L_EVNT SG_ 278 L_ATCU_HU_MasterProfile_ResetIndex 1500;
BA_REL_ "GenSigTimeoutTime" BU_SG_REL_ L_HKBD SG_ 278 L_ATCU_HU_MasterProfile_ResetIndex 1500;
BA_ "Version" SG_ 278 L_ATCU_HU_MasterProfile_ResetIndex "25.08.06";
BA_ "Description" SG_ 278 L_ATCU_HU_OptionInfo "Bit0 : Navi (0: Not Support / 1: Support)

Bit1 : USM (0: Not Support / 1: Support)

Bit2 : TMS (0: Not Support / 1: Support)

Bit3 : Multi Profile (0: Not Support(No Profile or Single Profile)  / 1: Support)

Bit4 : Camera Guideline (0: Displayed by Camera / 1: Displayed by H/U)

Bit5 : LVDS Interface (0:MIPI, 1:Non-MIPI)

Bit6 : Welcome/Goodbye Animation Support (0: Not Support / 1: Support)

Bit7 : Drive/Custom Mode Support (0: Not Support / 1 : Support)

Bit8 : Automatic brightness adjustment function Support (0: Not Support / 1 : Support) 

Bit9 : Navigation map display for Cluster (0: Not Support / 1 : Support) 

Bit10 : AAOS(0: Not Support / 1: Support)

Bit11~12 : Platform Type(0x0: Premium / 0x1: Standard / 0x2: Lite / 0x3: Basic)

Bit13 : New Profile Policy (0: Not Support / 1: Support)

Bit14 : Reserved

Bit15 : Invalid";
BA_ "GenSigSendType" SG_ 278 L_ATCU_HU_OptionInfo 4;
BA_ "GenSigStartValue" SG_ 278 L_ATCU_HU_OptionInfo 32768;
BA_ "UserSigValidity" SG_ 278 L_ATCU_HU_OptionInfo 0;
BA_REL_ "GenSigTimeoutTime" BU_SG_REL_ L_2HKBD SG_ 278 L_ATCU_HU_OptionInfo 1500;
BA_REL_ "GenSigTimeoutTime" BU_SG_REL_ L_3HKBD SG_ 278 L_ATCU_HU_OptionInfo 1500;
BA_REL_ "GenSigTimeoutTime" BU_SG_REL_ L_EVNT SG_ 278 L_ATCU_HU_OptionInfo 1500;
BA_REL_ "GenSigTimeoutTime" BU_SG_REL_ L_HKBD SG_ 278 L_ATCU_HU_OptionInfo 1500;
BA_ "Version" SG_ 278 L_ATCU_HU_OptionInfo "25.08.06";
BA_ "GenMsgCycleTime" BO_ 281 0;
BA_ "Description" SG_ 281 L_ATCU_HU_FrDrEVntSidePt_X "Electric Vent Frt Driver Side Electric Vent Touch Range X Coordinate";
BA_ "GenSigSendType" SG_ 281 L_ATCU_HU_FrDrEVntSidePt_X 4;
BA_ "UserSigValidity" SG_ 281 L_ATCU_HU_FrDrEVntSidePt_X 7;
BA_REL_ "GenSigTimeoutTime" BU_SG_REL_ L_EVNT SG_ 281 L_ATCU_HU_FrDrEVntSidePt_X 0;
BA_ "Version" SG_ 281 L_ATCU_HU_FrDrEVntSidePt_X "24.05.11";
BA_ "Description" SG_ 281 L_ATCU_HU_FrDrEVntSidePt_Y "Electric Vent Frt Driver Side Electric Vent Touch Range Y Coordinate";
BA_ "GenSigSendType" SG_ 281 L_ATCU_HU_FrDrEVntSidePt_Y 4;
BA_ "UserSigValidity" SG_ 281 L_ATCU_HU_FrDrEVntSidePt_Y 7;
BA_REL_ "GenSigTimeoutTime" BU_SG_REL_ L_EVNT SG_ 281 L_ATCU_HU_FrDrEVntSidePt_Y 0;
BA_ "Version" SG_ 281 L_ATCU_HU_FrDrEVntSidePt_Y "24.05.11";
BA_ "Description" SG_ 281 L_ATCU_HU_FrDrEVntCtrPt_X "Electric Vent Frt Driver Center Electric Vent Touch Range X Coordinate";
BA_ "GenSigSendType" SG_ 281 L_ATCU_HU_FrDrEVntCtrPt_X 4;
BA_ "UserSigValidity" SG_ 281 L_ATCU_HU_FrDrEVntCtrPt_X 7;
BA_REL_ "GenSigTimeoutTime" BU_SG_REL_ L_EVNT SG_ 281 L_ATCU_HU_FrDrEVntCtrPt_X 0;
BA_ "Version" SG_ 281 L_ATCU_HU_FrDrEVntCtrPt_X "24.05.11";
BA_ "Description" SG_ 281 L_ATCU_HU_FrDrEVntCtrPt_Y "Electric Vent Frt Driver Center Electric Vent Touch Range Y Coordinate";
BA_ "GenSigSendType" SG_ 281 L_ATCU_HU_FrDrEVntCtrPt_Y 4;
BA_ "UserSigValidity" SG_ 281 L_ATCU_HU_FrDrEVntCtrPt_Y 7;
BA_REL_ "GenSigTimeoutTime" BU_SG_REL_ L_EVNT SG_ 281 L_ATCU_HU_FrDrEVntCtrPt_Y 0;
BA_ "Version" SG_ 281 L_ATCU_HU_FrDrEVntCtrPt_Y "24.05.11";
BA_ "GenMsgCycleTime" BO_ 305 0;
BA_ "Description" SG_ 305 L_ATCU_HU_FrPsEVntSidePt_X "Electric Vent Frt Passenger Side Electric Vent Touch Range X Coordinate";
BA_ "GenSigSendType" SG_ 305 L_ATCU_HU_FrPsEVntSidePt_X 4;
BA_ "UserSigValidity" SG_ 305 L_ATCU_HU_FrPsEVntSidePt_X 7;
BA_REL_ "GenSigTimeoutTime" BU_SG_REL_ L_EVNT SG_ 305 L_ATCU_HU_FrPsEVntSidePt_X 0;
BA_ "Version" SG_ 305 L_ATCU_HU_FrPsEVntSidePt_X "24.05.11";
BA_ "Description" SG_ 305 L_ATCU_HU_FrPsEVntSidePt_Y "Electric Vent Frt Passenger Side Electric Vent Touch Range Y Coordinate";
BA_ "GenSigSendType" SG_ 305 L_ATCU_HU_FrPsEVntSidePt_Y 4;
BA_ "UserSigValidity" SG_ 305 L_ATCU_HU_FrPsEVntSidePt_Y 7;
BA_REL_ "GenSigTimeoutTime" BU_SG_REL_ L_EVNT SG_ 305 L_ATCU_HU_FrPsEVntSidePt_Y 0;
BA_ "Version" SG_ 305 L_ATCU_HU_FrPsEVntSidePt_Y "24.05.11";
BA_ "Description" SG_ 305 L_ATCU_HU_FrPsEVntCtrPt_X "Electric Vent Frt Passenger Center Electric Vent Touch Range X Coordinate";
BA_ "GenSigSendType" SG_ 305 L_ATCU_HU_FrPsEVntCtrPt_X 4;
BA_ "UserSigValidity" SG_ 305 L_ATCU_HU_FrPsEVntCtrPt_X 7;
BA_REL_ "GenSigTimeoutTime" BU_SG_REL_ L_EVNT SG_ 305 L_ATCU_HU_FrPsEVntCtrPt_X 0;
BA_ "Version" SG_ 305 L_ATCU_HU_FrPsEVntCtrPt_X "24.05.11";
BA_ "Description" SG_ 305 L_ATCU_HU_FrPsEVntCtrPt_Y "Electric Vent Frt Passenger Center Electric Vent Touch Range Y Coordinate";
BA_ "GenSigSendType" SG_ 305 L_ATCU_HU_FrPsEVntCtrPt_Y 4;
BA_ "UserSigValidity" SG_ 305 L_ATCU_HU_FrPsEVntCtrPt_Y 7;
BA_REL_ "GenSigTimeoutTime" BU_SG_REL_ L_EVNT SG_ 305 L_ATCU_HU_FrPsEVntCtrPt_Y 0;
BA_ "Version" SG_ 305 L_ATCU_HU_FrPsEVntCtrPt_Y "24.05.11";
BA_ "GenMsgCycleTime" BO_ 306 0;
BA_ "Description" SG_ 306 L_ATCU_HU_RrDrEVntConsPt_X "Electric Vent Rear Driver Console Touch Range X Coordinate";
BA_ "GenSigSendType" SG_ 306 L_ATCU_HU_RrDrEVntConsPt_X 4;
BA_ "UserSigValidity" SG_ 306 L_ATCU_HU_RrDrEVntConsPt_X 7;
BA_REL_ "GenSigTimeoutTime" BU_SG_REL_ L_EVNT SG_ 306 L_ATCU_HU_RrDrEVntConsPt_X 0;
BA_ "Version" SG_ 306 L_ATCU_HU_RrDrEVntConsPt_X "24.05.11";
BA_ "Description" SG_ 306 L_ATCU_HU_RrDrEVntConsPt_Y "Electric Vent Rear Driver Console Touch Range Y Coordinate";
BA_ "GenSigSendType" SG_ 306 L_ATCU_HU_RrDrEVntConsPt_Y 4;
BA_ "UserSigValidity" SG_ 306 L_ATCU_HU_RrDrEVntConsPt_Y 7;
BA_REL_ "GenSigTimeoutTime" BU_SG_REL_ L_EVNT SG_ 306 L_ATCU_HU_RrDrEVntConsPt_Y 0;
BA_ "Version" SG_ 306 L_ATCU_HU_RrDrEVntConsPt_Y "24.05.11";
BA_ "Description" SG_ 306 L_ATCU_HU_RrPsEVntConsPt_X "Electric Vent Rear Passenger Console Touch Range X Coordinate";
BA_ "GenSigSendType" SG_ 306 L_ATCU_HU_RrPsEVntConsPt_X 4;
BA_ "UserSigValidity" SG_ 306 L_ATCU_HU_RrPsEVntConsPt_X 7;
BA_REL_ "GenSigTimeoutTime" BU_SG_REL_ L_EVNT SG_ 306 L_ATCU_HU_RrPsEVntConsPt_X 0;
BA_ "Version" SG_ 306 L_ATCU_HU_RrPsEVntConsPt_X "24.05.11";
BA_ "Description" SG_ 306 L_ATCU_HU_RrPsEVntConsPt_Y "Electric Vent Rear Passenger Console Touch Range Y Coordinate";
BA_ "GenSigSendType" SG_ 306 L_ATCU_HU_RrPsEVntConsPt_Y 4;
BA_ "UserSigValidity" SG_ 306 L_ATCU_HU_RrPsEVntConsPt_Y 7;
BA_REL_ "GenSigTimeoutTime" BU_SG_REL_ L_EVNT SG_ 306 L_ATCU_HU_RrPsEVntConsPt_Y 0;
BA_ "Version" SG_ 306 L_ATCU_HU_RrPsEVntConsPt_Y "24.05.11";
BA_ "Description" SG_ 306 L_ATCU_HU_RrDrEVntConsOpnCls "Electric Vent Rear Driver Console Vent Open/Close Signal";
BA_ "GenSigSendType" SG_ 306 L_ATCU_HU_RrDrEVntConsOpnCls 4;
BA_ "UserSigValidity" SG_ 306 L_ATCU_HU_RrDrEVntConsOpnCls 7;
BA_REL_ "GenSigTimeoutTime" BU_SG_REL_ L_EVNT SG_ 306 L_ATCU_HU_RrDrEVntConsOpnCls 0;
BA_ "Version" SG_ 306 L_ATCU_HU_RrDrEVntConsOpnCls "24.05.11";
BA_ "Description" SG_ 306 L_ATCU_HU_RrPsEVntConsOpnCls "Electric Vent Rear Passenger Console Vent Open/Close Signal";
BA_ "GenSigSendType" SG_ 306 L_ATCU_HU_RrPsEVntConsOpnCls 4;
BA_ "UserSigValidity" SG_ 306 L_ATCU_HU_RrPsEVntConsOpnCls 7;
BA_REL_ "GenSigTimeoutTime" BU_SG_REL_ L_EVNT SG_ 306 L_ATCU_HU_RrPsEVntConsOpnCls 0;
BA_ "Version" SG_ 306 L_ATCU_HU_RrPsEVntConsOpnCls "24.05.11";
BA_ "Description" SG_ 306 L_ATCU_HU_RrDrEVntModeSet "Electric Vent Rear Driver Console Vent Mode Signal";
BA_ "GenSigSendType" SG_ 306 L_ATCU_HU_RrDrEVntModeSet 4;
BA_ "UserSigValidity" SG_ 306 L_ATCU_HU_RrDrEVntModeSet 7;
BA_REL_ "GenSigTimeoutTime" BU_SG_REL_ L_EVNT SG_ 306 L_ATCU_HU_RrDrEVntModeSet 0;
BA_ "Version" SG_ 306 L_ATCU_HU_RrDrEVntModeSet "25.04.02";
BA_ "Description" SG_ 306 L_ATCU_HU_RrPsEVntModeSet "Electric Vent Rear Passenger Console Vent Mode Signal";
BA_ "GenSigSendType" SG_ 306 L_ATCU_HU_RrPsEVntModeSet 4;
BA_ "UserSigValidity" SG_ 306 L_ATCU_HU_RrPsEVntModeSet 7;
BA_REL_ "GenSigTimeoutTime" BU_SG_REL_ L_EVNT SG_ 306 L_ATCU_HU_RrPsEVntModeSet 0;
BA_ "Version" SG_ 306 L_ATCU_HU_RrPsEVntModeSet "25.04.02";
BA_ "GenMsgSendType" BO_ 304 0;
BA_ "GenMsgCycleTime" BO_ 304 1000;
BA_ "GenMsgCycleTimeFast" BO_ 304 0;
BA_ "GenMsgNrOfRepetition" BO_ 304 0;
BA_ "Description" SG_ 304 L_ATCU_CTS_RrDrEVntConsBdryUp_X "Electric Vent RR Dr Console Electric Vent Upper Range X Coordinate";
BA_ "UserSigValidity" SG_ 304 L_ATCU_CTS_RrDrEVntConsBdryUp_X 7;
BA_REL_ "GenSigTimeoutTime" BU_SG_REL_ L_EVNT SG_ 304 L_ATCU_CTS_RrDrEVntConsBdryUp_X 5000;
BA_ "Version" SG_ 304 L_ATCU_CTS_RrDrEVntConsBdryUp_X "24.05.11";
BA_ "Description" SG_ 304 L_ATCU_CTS_RrDrEVntConsBdryLo_X "Electric Vent RR Dr Console Electric Vent Lower Range X Coordinate";
BA_ "UserSigValidity" SG_ 304 L_ATCU_CTS_RrDrEVntConsBdryLo_X 7;
BA_REL_ "GenSigTimeoutTime" BU_SG_REL_ L_EVNT SG_ 304 L_ATCU_CTS_RrDrEVntConsBdryLo_X 5000;
BA_ "Version" SG_ 304 L_ATCU_CTS_RrDrEVntConsBdryLo_X "24.05.11";
BA_ "Description" SG_ 304 L_ATCU_CTS_RrDrEVntConsBdryLo_Y "Electric Vent RR Dr Console Electric Vent Lower Range Y Coordinate";
BA_ "UserSigValidity" SG_ 304 L_ATCU_CTS_RrDrEVntConsBdryLo_Y 7;
BA_REL_ "GenSigTimeoutTime" BU_SG_REL_ L_EVNT SG_ 304 L_ATCU_CTS_RrDrEVntConsBdryLo_Y 5000;
BA_ "Version" SG_ 304 L_ATCU_CTS_RrDrEVntConsBdryLo_Y "24.05.11";
BA_ "Description" SG_ 304 L_ATCU_CTS_RrPsEVntConsBdryUp_X "Electric Vent RR Ps Console Electric Vent Upper Range X Coordinate";
BA_ "UserSigValidity" SG_ 304 L_ATCU_CTS_RrPsEVntConsBdryUp_X 7;
BA_REL_ "GenSigTimeoutTime" BU_SG_REL_ L_EVNT SG_ 304 L_ATCU_CTS_RrPsEVntConsBdryUp_X 5000;
BA_ "Version" SG_ 304 L_ATCU_CTS_RrPsEVntConsBdryUp_X "24.05.11";
BA_ "Description" SG_ 304 L_ATCU_CTS_RrPsEVntConsBdryUp_Y "Electric Vent RR Ps Console Electric Vent Upper Range Y Coordinate";
BA_ "UserSigValidity" SG_ 304 L_ATCU_CTS_RrPsEVntConsBdryUp_Y 7;
BA_REL_ "GenSigTimeoutTime" BU_SG_REL_ L_EVNT SG_ 304 L_ATCU_CTS_RrPsEVntConsBdryUp_Y 5000;
BA_ "Version" SG_ 304 L_ATCU_CTS_RrPsEVntConsBdryUp_Y "24.05.11";
BA_ "Description" SG_ 304 L_ATCU_CTS_RrPsEVntConsBdryLo_X "Electric Vent RR Ps Console Electric Vent Lower Range X Coordinate";
BA_ "UserSigValidity" SG_ 304 L_ATCU_CTS_RrPsEVntConsBdryLo_X 7;
BA_REL_ "GenSigTimeoutTime" BU_SG_REL_ L_EVNT SG_ 304 L_ATCU_CTS_RrPsEVntConsBdryLo_X 5000;
BA_ "Version" SG_ 304 L_ATCU_CTS_RrPsEVntConsBdryLo_X "24.05.11";
BA_ "Description" SG_ 304 L_ATCU_CTS_RrPsEVntConsBdryLo_Y "Electric Vent RR Ps Console Electric Vent Lower Range Y Coordinate";
BA_ "UserSigValidity" SG_ 304 L_ATCU_CTS_RrPsEVntConsBdryLo_Y 7;
BA_REL_ "GenSigTimeoutTime" BU_SG_REL_ L_EVNT SG_ 304 L_ATCU_CTS_RrPsEVntConsBdryLo_Y 5000;
BA_ "Version" SG_ 304 L_ATCU_CTS_RrPsEVntConsBdryLo_Y "24.05.11";
BA_ "Description" SG_ 304 L_ATCU_CTS_RrDrEVntConsBdryUp_Y "Electric Vent RR Dr Console Electric Vent Upper Range Y Coordinate";
BA_ "UserSigValidity" SG_ 304 L_ATCU_CTS_RrDrEVntConsBdryUp_Y 7;
BA_REL_ "GenSigTimeoutTime" BU_SG_REL_ L_EVNT SG_ 304 L_ATCU_CTS_RrDrEVntConsBdryUp_Y 5000;
BA_ "Version" SG_ 304 L_ATCU_CTS_RrDrEVntConsBdryUp_Y "24.05.11";
BA_ "GenMsgSendType" BO_ 801 0;
BA_ "GenMsgCycleTime" BO_ 801 500;
BA_ "GenSigSendType" SG_ 801 MON_LibMngrDrvMod 4;
BA_ "UserSigValidity" SG_ 801 MON_LibMngrDrvMod 7;
BA_REL_ "GenSigTimeoutTime" BU_SG_REL_ L_ATCU SG_ 801 MON_LibMngrDrvMod 5000;
BA_ "Version" SG_ 801 MON_LibMngrDrvMod "24.08.08";
BA_ "GenSigSendType" SG_ 801 MON_LibMngrAC 4;
BA_ "GenSigStartValue" SG_ 801 MON_LibMngrAC 3;
BA_ "UserSigValidity" SG_ 801 MON_LibMngrAC 7;
BA_REL_ "GenSigTimeoutTime" BU_SG_REL_ L_ATCU SG_ 801 MON_LibMngrAC 5000;
BA_ "Version" SG_ 801 MON_LibMngrAC "24.08.08";
BA_ "GenSigSendType" SG_ 801 MON_LibMngrActvIncarMotPwr 4;
BA_ "UserSigValidity" SG_ 801 MON_LibMngrActvIncarMotPwr 7;
BA_REL_ "GenSigTimeoutTime" BU_SG_REL_ L_ATCU SG_ 801 MON_LibMngrActvIncarMotPwr 5000;
BA_ "Version" SG_ 801 MON_LibMngrActvIncarMotPwr "24.08.08";
BA_ "GenSigSendType" SG_ 801 MON_LibMngrPDCWakeUpReq 4;
BA_ "UserSigValidity" SG_ 801 MON_LibMngrPDCWakeUpReq 7;
BA_REL_ "GenSigTimeoutTime" BU_SG_REL_ L_ATCU SG_ 801 MON_LibMngrPDCWakeUpReq 5000;
BA_ "Version" SG_ 801 MON_LibMngrPDCWakeUpReq "24.08.08";
BA_ "GenSigSendType" SG_ 801 MON_LibMngrLVPTCRly1State 4;
BA_ "UserSigValidity" SG_ 801 MON_LibMngrLVPTCRly1State 7;
BA_REL_ "GenSigTimeoutTime" BU_SG_REL_ L_ATCU SG_ 801 MON_LibMngrLVPTCRly1State 1500;
BA_ "Version" SG_ 801 MON_LibMngrLVPTCRly1State "24.08.08";
BA_ "GenSigSendType" SG_ 801 MON_LibMngrLVPTCRly2State 4;
BA_ "UserSigValidity" SG_ 801 MON_LibMngrLVPTCRly2State 7;
BA_REL_ "GenSigTimeoutTime" BU_SG_REL_ L_ATCU SG_ 801 MON_LibMngrLVPTCRly2State 5000;
BA_ "Version" SG_ 801 MON_LibMngrLVPTCRly2State "24.08.08";
BA_ "GenSigSendType" SG_ 801 MON_LibMngrVRLedOpReq 4;
BA_ "UserSigValidity" SG_ 801 MON_LibMngrVRLedOpReq 7;
BA_REL_ "GenSigTimeoutTime" BU_SG_REL_ L_ATCU SG_ 801 MON_LibMngrVRLedOpReq 5000;
BA_ "Version" SG_ 801 MON_LibMngrVRLedOpReq "24.08.08";
BA_ "GenSigSendType" SG_ 801 MON_LibMngrBlrVtg 4;
BA_ "UserSigValidity" SG_ 801 MON_LibMngrBlrVtg 7;
BA_REL_ "GenSigTimeoutTime" BU_SG_REL_ L_ATCU SG_ 801 MON_LibMngrBlrVtg 5000;
BA_ "Version" SG_ 801 MON_LibMngrBlrVtg "24.08.08";
BA_ "GenSigSendType" SG_ 801 MON_LibMngrAstMod 4;
BA_ "UserSigValidity" SG_ 801 MON_LibMngrAstMod 7;
BA_REL_ "GenSigTimeoutTime" BU_SG_REL_ L_ATCU SG_ 801 MON_LibMngrAstMod 5000;
BA_ "Version" SG_ 801 MON_LibMngrAstMod "24.08.08";
BA_ "Description" SG_ 801 MON_LibMngrDrvTmpDr "0~100, %,  [0~1000, 0, 0.1]";
BA_ "GenSigSendType" SG_ 801 MON_LibMngrDrvTmpDr 4;
BA_ "UserSigValidity" SG_ 801 MON_LibMngrDrvTmpDr 7;
BA_REL_ "GenSigTimeoutTime" BU_SG_REL_ L_ATCU SG_ 801 MON_LibMngrDrvTmpDr 5000;
BA_ "Version" SG_ 801 MON_LibMngrDrvTmpDr "24.08.08";
BA_ "Description" SG_ 801 MON_LibMngrAstTmpDr "0~100, %,  [0~1000, 0, 0.1]";
BA_ "GenSigSendType" SG_ 801 MON_LibMngrAstTmpDr 4;
BA_ "UserSigValidity" SG_ 801 MON_LibMngrAstTmpDr 7;
BA_REL_ "GenSigTimeoutTime" BU_SG_REL_ L_ATCU SG_ 801 MON_LibMngrAstTmpDr 5000;
BA_ "Version" SG_ 801 MON_LibMngrAstTmpDr "24.08.08";
BA_ "Description" SG_ 801 MON_LibMngrIntake "³»/¿Ü±â Á¦¾î Ãâ·Â ½ÅÈ£



¿¹½Ã °ª) 

0 : FRE

200 : REC_20%

700 : REC_70%

950 : FRE_5%

1000 : REC

1001 : ITK_NUM (*)

1023 : ITK_NONE";
BA_ "GenSigSendType" SG_ 801 MON_LibMngrIntake 4;
BA_ "UserSigValidity" SG_ 801 MON_LibMngrIntake 7;
BA_REL_ "GenSigTimeoutTime" BU_SG_REL_ L_ATCU SG_ 801 MON_LibMngrIntake 5000;
BA_ "Version" SG_ 801 MON_LibMngrIntake "24.08.08";
BA_ "GenMsgSendType" BO_ 802 0;
BA_ "GenMsgCycleTime" BO_ 802 500;
BA_ "Description" SG_ 802 MON_LibMngrDEFDr "0~100, %,  [0~1000, 0, 0.1]";
BA_ "GenSigSendType" SG_ 802 MON_LibMngrDEFDr 4;
BA_ "UserSigValidity" SG_ 802 MON_LibMngrDEFDr 7;
BA_REL_ "GenSigTimeoutTime" BU_SG_REL_ L_ATCU SG_ 802 MON_LibMngrDEFDr 5000;
BA_ "Version" SG_ 802 MON_LibMngrDEFDr "24.08.08";
BA_ "GenSigSendType" SG_ 802 MON_LibMngr2LHMod 4;
BA_ "UserSigValidity" SG_ 802 MON_LibMngr2LHMod 7;
BA_REL_ "GenSigTimeoutTime" BU_SG_REL_ L_ATCU SG_ 802 MON_LibMngr2LHMod 5000;
BA_ "Version" SG_ 802 MON_LibMngr2LHMod "24.08.08";
BA_ "Description" SG_ 802 MON_LibMngrPwrSleep "OFF=Sleep Not OK-Running, ON=Sleep OK-Not Running";
BA_ "GenSigSendType" SG_ 802 MON_LibMngrPwrSleep 4;
BA_ "UserSigValidity" SG_ 802 MON_LibMngrPwrSleep 7;
BA_REL_ "GenSigTimeoutTime" BU_SG_REL_ L_ATCU SG_ 802 MON_LibMngrPwrSleep 5000;
BA_ "Version" SG_ 802 MON_LibMngrPwrSleep "24.08.08";
BA_ "GenSigSendType" SG_ 802 MON_LibMngr2LHBlrVtg 4;
BA_ "UserSigValidity" SG_ 802 MON_LibMngr2LHBlrVtg 7;
BA_REL_ "GenSigTimeoutTime" BU_SG_REL_ L_ATCU SG_ 802 MON_LibMngr2LHBlrVtg 5000;
BA_ "Version" SG_ 802 MON_LibMngr2LHBlrVtg "24.08.08";
BA_ "Description" SG_ 802 MON_LibMngr2LHTmpDr "0~100, % [0~1000, 0, 0.1]";
BA_ "GenSigSendType" SG_ 802 MON_LibMngr2LHTmpDr 4;
BA_ "UserSigValidity" SG_ 802 MON_LibMngr2LHTmpDr 7;
BA_REL_ "GenSigTimeoutTime" BU_SG_REL_ L_ATCU SG_ 802 MON_LibMngr2LHTmpDr 5000;
BA_ "Version" SG_ 802 MON_LibMngr2LHTmpDr "24.08.08";
BA_ "GenSigSendType" SG_ 802 MON_LibMngr2LHBlrStep 4;
BA_ "UserSigValidity" SG_ 802 MON_LibMngr2LHBlrStep 7;
BA_REL_ "GenSigTimeoutTime" BU_SG_REL_ L_ATCU SG_ 802 MON_LibMngr2LHBlrStep 5000;
BA_ "Version" SG_ 802 MON_LibMngr2LHBlrStep "24.08.08";
BA_ "GenMsgSendType" BO_ 803 0;
BA_ "GenMsgCycleTime" BO_ 803 500;
BA_ "GenSigSendType" SG_ 803 MON_LibFuncSysKeyState 4;
BA_ "UserSigValidity" SG_ 803 MON_LibFuncSysKeyState 7;
BA_REL_ "GenSigTimeoutTime" BU_SG_REL_ L_ATCU SG_ 803 MON_LibFuncSysKeyState 5000;
BA_ "Version" SG_ 803 MON_LibFuncSysKeyState "24.08.08";
BA_ "GenSigSendType" SG_ 803 MON_LibFuncSwBlrStatus 4;
BA_ "UserSigValidity" SG_ 803 MON_LibFuncSwBlrStatus 7;
BA_REL_ "GenSigTimeoutTime" BU_SG_REL_ L_ATCU SG_ 803 MON_LibFuncSwBlrStatus 5000;
BA_ "Version" SG_ 803 MON_LibFuncSwBlrStatus "24.08.08";
BA_ "GenSigSendType" SG_ 803 MON_LibFuncSwIntakeStatus 4;
BA_ "UserSigValidity" SG_ 803 MON_LibFuncSwIntakeStatus 7;
BA_REL_ "GenSigTimeoutTime" BU_SG_REL_ L_ATCU SG_ 803 MON_LibFuncSwIntakeStatus 5000;
BA_ "Version" SG_ 803 MON_LibFuncSwIntakeStatus "24.08.08";
BA_ "GenSigSendType" SG_ 803 MON_LibFuncSwACStatus 4;
BA_ "UserSigValidity" SG_ 803 MON_LibFuncSwACStatus 7;
BA_REL_ "GenSigTimeoutTime" BU_SG_REL_ L_ATCU SG_ 803 MON_LibFuncSwACStatus 5000;
BA_ "Version" SG_ 803 MON_LibFuncSwACStatus "24.08.08";
BA_ "GenSigSendType" SG_ 803 MON_LibFuncAutoSw 4;
BA_ "UserSigValidity" SG_ 803 MON_LibFuncAutoSw 7;
BA_REL_ "GenSigTimeoutTime" BU_SG_REL_ L_ATCU SG_ 803 MON_LibFuncAutoSw 5000;
BA_ "Version" SG_ 803 MON_LibFuncAutoSw "24.08.08";
BA_ "Description" SG_ 803 MON_LibFuncSwIntakeState "0~100, % [0~1000, 1023, 0.1]

¿¹½Ã °ª) 

0 : FRE

200 : REC_20%

700 : REC_70%

950 : FRE_5%

1000 : REC

1001 : ITK_NUM 

1023 : ITK_NONE (*)";
BA_ "GenSigSendType" SG_ 803 MON_LibFuncSwIntakeState 4;
BA_ "UserSigValidity" SG_ 803 MON_LibFuncSwIntakeState 7;
BA_REL_ "GenSigTimeoutTime" BU_SG_REL_ L_ATCU SG_ 803 MON_LibFuncSwIntakeState 5000;
BA_ "Version" SG_ 803 MON_LibFuncSwIntakeState "24.08.08";
BA_ "GenSigSendType" SG_ 803 MON_LibFuncIntakeRECSw 4;
BA_ "UserSigValidity" SG_ 803 MON_LibFuncIntakeRECSw 7;
BA_REL_ "GenSigTimeoutTime" BU_SG_REL_ L_ATCU SG_ 803 MON_LibFuncIntakeRECSw 5000;
BA_ "Version" SG_ 803 MON_LibFuncIntakeRECSw "24.08.08";
BA_ "GenSigSendType" SG_ 803 MON_LibFuncSwDrvTempStepState 4;
BA_ "UserSigValidity" SG_ 803 MON_LibFuncSwDrvTempStepState 7;
BA_REL_ "GenSigTimeoutTime" BU_SG_REL_ L_ATCU SG_ 803 MON_LibFuncSwDrvTempStepState 5000;
BA_ "Version" SG_ 803 MON_LibFuncSwDrvTempStepState "24.08.08";
BA_ "GenSigSendType" SG_ 803 MON_LibFuncSwModState 4;
BA_ "UserSigValidity" SG_ 803 MON_LibFuncSwModState 7;
BA_REL_ "GenSigTimeoutTime" BU_SG_REL_ L_ATCU SG_ 803 MON_LibFuncSwModState 5000;
BA_ "Version" SG_ 803 MON_LibFuncSwModState "24.08.08";
BA_ "GenSigSendType" SG_ 803 MON_LibFunc2LHSwTempStepState 4;
BA_ "UserSigValidity" SG_ 803 MON_LibFunc2LHSwTempStepState 7;
BA_REL_ "GenSigTimeoutTime" BU_SG_REL_ L_ATCU SG_ 803 MON_LibFunc2LHSwTempStepState 5000;
BA_ "Version" SG_ 803 MON_LibFunc2LHSwTempStepState "24.08.08";
BA_ "GenSigSendType" SG_ 803 MON_LibFuncIntakeFRESw 4;
BA_ "UserSigValidity" SG_ 803 MON_LibFuncIntakeFRESw 7;
BA_REL_ "GenSigTimeoutTime" BU_SG_REL_ L_ATCU SG_ 803 MON_LibFuncIntakeFRESw 5000;
BA_ "Version" SG_ 803 MON_LibFuncIntakeFRESw "24.08.08";
BA_ "GenSigSendType" SG_ 803 MON_LibFunc2LHSwModStatus 4;
BA_ "UserSigValidity" SG_ 803 MON_LibFunc2LHSwModStatus 7;
BA_REL_ "GenSigTimeoutTime" BU_SG_REL_ L_ATCU SG_ 803 MON_LibFunc2LHSwModStatus 5000;
BA_ "Version" SG_ 803 MON_LibFunc2LHSwModStatus "24.08.08";
BA_ "GenSigSendType" SG_ 803 MON_LibFunc2LHBlowerProfileProhibit 4;
BA_ "UserSigValidity" SG_ 803 MON_LibFunc2LHBlowerProfileProhibit 7;
BA_REL_ "GenSigTimeoutTime" BU_SG_REL_ L_ATCU SG_ 803 MON_LibFunc2LHBlowerProfileProhibit 5000;
BA_ "Version" SG_ 803 MON_LibFunc2LHBlowerProfileProhibit "24.08.08";
BA_ "GenSigSendType" SG_ 803 MON_LibFunc2LHSwModState 4;
BA_ "UserSigValidity" SG_ 803 MON_LibFunc2LHSwModState 7;
BA_REL_ "GenSigTimeoutTime" BU_SG_REL_ L_ATCU SG_ 803 MON_LibFunc2LHSwModState 5000;
BA_ "Version" SG_ 803 MON_LibFunc2LHSwModState "24.08.08";
BA_ "GenSigSendType" SG_ 803 MON_LibFunc2LHBlrStepState 4;
BA_ "UserSigValidity" SG_ 803 MON_LibFunc2LHBlrStepState 7;
BA_REL_ "GenSigTimeoutTime" BU_SG_REL_ L_ATCU SG_ 803 MON_LibFunc2LHBlrStepState 5000;
BA_ "Version" SG_ 803 MON_LibFunc2LHBlrStepState "24.08.08";
BA_ "GenSigSendType" SG_ 803 MON_LibFunc2LHAutoSw 4;
BA_ "UserSigValidity" SG_ 803 MON_LibFunc2LHAutoSw 7;
BA_REL_ "GenSigTimeoutTime" BU_SG_REL_ L_ATCU SG_ 803 MON_LibFunc2LHAutoSw 5000;
BA_ "Version" SG_ 803 MON_LibFunc2LHAutoSw "24.08.08";
BA_ "GenSigSendType" SG_ 803 MON_LibFunc2LHSwBlrStatus 4;
BA_ "UserSigValidity" SG_ 803 MON_LibFunc2LHSwBlrStatus 7;
BA_REL_ "GenSigTimeoutTime" BU_SG_REL_ L_ATCU SG_ 803 MON_LibFunc2LHSwBlrStatus 5000;
BA_ "Version" SG_ 803 MON_LibFunc2LHSwBlrStatus "24.08.08";
BA_ "GenSigSendType" SG_ 803 MON_LibFuncSwModStatus 4;
BA_ "UserSigValidity" SG_ 803 MON_LibFuncSwModStatus 7;
BA_REL_ "GenSigTimeoutTime" BU_SG_REL_ L_ATCU SG_ 803 MON_LibFuncSwModStatus 5000;
BA_ "Version" SG_ 803 MON_LibFuncSwModStatus "24.08.08";
BA_ "GenSigSendType" SG_ 803 MON_LibFuncBlrStepState 4;
BA_ "UserSigValidity" SG_ 803 MON_LibFuncBlrStepState 7;
BA_REL_ "GenSigTimeoutTime" BU_SG_REL_ L_ATCU SG_ 803 MON_LibFuncBlrStepState 5000;
BA_ "Version" SG_ 803 MON_LibFuncBlrStepState "24.08.08";
BA_ "GenMsgSendType" BO_ 804 0;
BA_ "GenMsgCycleTime" BO_ 804 500;
BA_ "Description" SG_ 804 MON_LibFuncAMBFltrRstKeyOffTmr "0~4294967290, s, [0~429496729, 0, 1]";
BA_ "GenSigSendType" SG_ 804 MON_LibFuncAMBFltrRstKeyOffTmr 4;
BA_ "UserSigValidity" SG_ 804 MON_LibFuncAMBFltrRstKeyOffTmr 7;
BA_REL_ "GenSigTimeoutTime" BU_SG_REL_ L_ATCU SG_ 804 MON_LibFuncAMBFltrRstKeyOffTmr 5000;
BA_ "Version" SG_ 804 MON_LibFuncAMBFltrRstKeyOffTmr "24.08.08";
BA_ "GenSigSendType" SG_ 804 MON_LibFuncHotStart2LHBlrPrfleChgReq 4;
BA_ "UserSigValidity" SG_ 804 MON_LibFuncHotStart2LHBlrPrfleChgReq 7;
BA_REL_ "GenSigTimeoutTime" BU_SG_REL_ L_ATCU SG_ 804 MON_LibFuncHotStart2LHBlrPrfleChgReq 5000;
BA_ "Version" SG_ 804 MON_LibFuncHotStart2LHBlrPrfleChgReq "24.08.08";
BA_ "GenSigSendType" SG_ 804 MON_LibFuncAmbFilterResetOpState 4;
BA_ "UserSigValidity" SG_ 804 MON_LibFuncAmbFilterResetOpState 7;
BA_REL_ "GenSigTimeoutTime" BU_SG_REL_ L_ATCU SG_ 804 MON_LibFuncAmbFilterResetOpState 5000;
BA_ "Version" SG_ 804 MON_LibFuncAmbFilterResetOpState "24.08.08";
BA_ "GenSigSendType" SG_ 804 MON_LibFuncDEFACState 4;
BA_ "UserSigValidity" SG_ 804 MON_LibFuncDEFACState 7;
BA_REL_ "GenSigTimeoutTime" BU_SG_REL_ L_ATCU SG_ 804 MON_LibFuncDEFACState 5000;
BA_ "Version" SG_ 804 MON_LibFuncDEFACState "24.08.08";
BA_ "GenSigSendType" SG_ 804 MON_LibFuncETCIntlckHVActOffReq 4;
BA_ "UserSigValidity" SG_ 804 MON_LibFuncETCIntlckHVActOffReq 7;
BA_REL_ "GenSigTimeoutTime" BU_SG_REL_ L_ATCU SG_ 804 MON_LibFuncETCIntlckHVActOffReq 5000;
BA_ "Version" SG_ 804 MON_LibFuncETCIntlckHVActOffReq "24.08.08";
BA_ "GenSigSendType" SG_ 804 MON_LibFuncHVACIntlckHVActOffReq 4;
BA_ "UserSigValidity" SG_ 804 MON_LibFuncHVACIntlckHVActOffReq 7;
BA_REL_ "GenSigTimeoutTime" BU_SG_REL_ L_ATCU SG_ 804 MON_LibFuncHVACIntlckHVActOffReq 5000;
BA_ "Version" SG_ 804 MON_LibFuncHVACIntlckHVActOffReq "24.08.08";
BA_ "GenSigSendType" SG_ 804 MON_LibFuncMainRlyProtectOpState 4;
BA_ "UserSigValidity" SG_ 804 MON_LibFuncMainRlyProtectOpState 7;
BA_REL_ "GenSigTimeoutTime" BU_SG_REL_ L_ATCU SG_ 804 MON_LibFuncMainRlyProtectOpState 5000;
BA_ "Version" SG_ 804 MON_LibFuncMainRlyProtectOpState "24.08.08";
BA_ "GenSigSendType" SG_ 804 MON_LibFuncMIXACState 4;
BA_ "UserSigValidity" SG_ 804 MON_LibFuncMIXACState 7;
BA_REL_ "GenSigTimeoutTime" BU_SG_REL_ L_ATCU SG_ 804 MON_LibFuncMIXACState 5000;
BA_ "Version" SG_ 804 MON_LibFuncMIXACState "24.08.08";
BA_ "GenSigSendType" SG_ 804 MON_LibFuncRmtFATCRmtState 4;
BA_ "UserSigValidity" SG_ 804 MON_LibFuncRmtFATCRmtState 7;
BA_REL_ "GenSigTimeoutTime" BU_SG_REL_ L_ATCU SG_ 804 MON_LibFuncRmtFATCRmtState 5000;
BA_ "Version" SG_ 804 MON_LibFuncRmtFATCRmtState "24.08.08";
BA_ "GenSigSendType" SG_ 804 MON_LibFuncUSM_ADSState 4;
BA_ "UserSigValidity" SG_ 804 MON_LibFuncUSM_ADSState 7;
BA_REL_ "GenSigTimeoutTime" BU_SG_REL_ L_ATCU SG_ 804 MON_LibFuncUSM_ADSState 5000;
BA_ "Version" SG_ 804 MON_LibFuncUSM_ADSState "24.08.08";
BA_ "GenSigSendType" SG_ 804 MON_LibFuncBlowerProfileProhibit 4;
BA_ "UserSigValidity" SG_ 804 MON_LibFuncBlowerProfileProhibit 7;
BA_REL_ "GenSigTimeoutTime" BU_SG_REL_ L_ATCU SG_ 804 MON_LibFuncBlowerProfileProhibit 5000;
BA_ "Version" SG_ 804 MON_LibFuncBlowerProfileProhibit "24.08.08";
BA_ "GenMsgSendType" BO_ 805 0;
BA_ "GenMsgCycleTime" BO_ 805 500;
BA_ "Description" SG_ 805 MON_LibMEMUSMROMWriteCmd "set each bit 0 if is false and 1 if is true

bit 0 : Write Off 

bit 1 Switch ROM Write Profile 1

bit 2 USM ROM Write Profile 1

bit 3 Switch ROM Write Profile 2  

bit 4 USM ROM Write Profile 2  

bit 5 Switch ROM Write Profile Guest  

bit 6 USM ROM Write Profile Guest  

bit 7 Current Profile Save - Profile 1

bit 8 Current Profile Save - Profile 2

bit 9 Current Profile Save - Profile Guest 

bit 10 Option Confirm & ROM Write";
BA_ "GenSigSendType" SG_ 805 MON_LibMEMUSMROMWriteCmd 4;
BA_ "UserSigValidity" SG_ 805 MON_LibMEMUSMROMWriteCmd 7;
BA_REL_ "GenSigTimeoutTime" BU_SG_REL_ L_ATCU SG_ 805 MON_LibMEMUSMROMWriteCmd 5000;
BA_ "Version" SG_ 805 MON_LibMEMUSMROMWriteCmd "24.08.08";
BA_ "Description" SG_ 805 MON_LibMEMROMWriteMEM "Struct {

  uint32 gbMem_SwRomGuest[5];

  uint32 gbMem_SwRomProfile1[5];

  uint32 gbMem_SwRomProfile2[5];

  uint32 gbMem_Profile;

  uint32 gbMem_USMRomGuest;

  uint32 gbMem_USMRomProfile1;

  uint32 gbMem_USMRomProfile2;

  uint32 gbMem_OPTRom;

  uint32 gbMem_ROMValid;

}";
BA_ "GenSigSendType" SG_ 805 MON_LibMEMROMWriteMEM 4;
BA_ "UserSigValidity" SG_ 805 MON_LibMEMROMWriteMEM 7;
BA_REL_ "GenSigTimeoutTime" BU_SG_REL_ L_ATCU SG_ 805 MON_LibMEMROMWriteMEM 5000;
BA_ "Version" SG_ 805 MON_LibMEMROMWriteMEM "24.08.08";
BA_ "GenMsgSendType" BO_ 806 0;
BA_ "GenMsgCycleTime" BO_ 806 500;
BA_ "Description" SG_ 806 MON_LibFuncAfterBlowStandbyTime "0~4294967290, ms, [0~429496729, 0, 10]";
BA_ "GenSigSendType" SG_ 806 MON_LibFuncAfterBlowStandbyTime 4;
BA_ "UserSigValidity" SG_ 806 MON_LibFuncAfterBlowStandbyTime 7;
BA_REL_ "GenSigTimeoutTime" BU_SG_REL_ L_ATCU SG_ 806 MON_LibFuncAfterBlowStandbyTime 5000;
BA_ "Version" SG_ 806 MON_LibFuncAfterBlowStandbyTime "24.08.08";
BA_ "Description" SG_ 806 MON_LibFuncSchdldVentStandbyTime "0~86400, Sec, [0~86400, 0, 1]";
BA_ "GenSigSendType" SG_ 806 MON_LibFuncSchdldVentStandbyTime 4;
BA_ "UserSigValidity" SG_ 806 MON_LibFuncSchdldVentStandbyTime 7;
BA_REL_ "GenSigTimeoutTime" BU_SG_REL_ L_ATCU SG_ 806 MON_LibFuncSchdldVentStandbyTime 5000;
BA_ "Version" SG_ 806 MON_LibFuncSchdldVentStandbyTime "24.08.08";
BA_ "GenMsgSendType" BO_ 807 0;
BA_ "GenMsgCycleTime" BO_ 807 500;
BA_ "Description" SG_ 807 MON_LibFuncHICCSWVer "HICC Library Software Ver.

Ex) v12.0.01.13 -> 0x1200113";
BA_ "GenSigSendType" SG_ 807 MON_LibFuncHICCSWVer 4;
BA_ "UserSigValidity" SG_ 807 MON_LibFuncHICCSWVer 7;
BA_REL_ "GenSigTimeoutTime" BU_SG_REL_ L_ATCU SG_ 807 MON_LibFuncHICCSWVer 5000;
BA_ "Version" SG_ 807 MON_LibFuncHICCSWVer "24.08.08";
BA_ "GenMsgSendType" BO_ 785 0;
BA_ "GenMsgCycleTime" BO_ 785 2000;
BA_ "Description" SG_ 785 MON_StatMngr_ETC "This value only use for ATCU Library data monitoring (Only use before SOP)";
BA_ "GenSigSendType" SG_ 785 MON_StatMngr_ETC 4;
BA_ "UserSigValidity" SG_ 785 MON_StatMngr_ETC 0;
BA_REL_ "GenSigTimeoutTime" BU_SG_REL_ L_ATCU SG_ 785 MON_StatMngr_ETC 5000;
BA_ "Version" SG_ 785 MON_StatMngr_ETC "24.09.01";
BA_ "GenMsgSendType" BO_ 786 0;
BA_ "GenMsgCycleTime" BO_ 786 2000;
BA_ "Description" SG_ 786 MON_StatMngr_FuelEfficiency "This value only use for ATCU Library data monitoring (Only use before SOP)";
BA_ "GenSigSendType" SG_ 786 MON_StatMngr_FuelEfficiency 4;
BA_ "UserSigValidity" SG_ 786 MON_StatMngr_FuelEfficiency 0;
BA_REL_ "GenSigTimeoutTime" BU_SG_REL_ L_ATCU SG_ 786 MON_StatMngr_FuelEfficiency 5000;
BA_ "Version" SG_ 786 MON_StatMngr_FuelEfficiency "24.09.01";
BA_ "GenMsgSendType" BO_ 787 0;
BA_ "GenMsgCycleTime" BO_ 787 2000;
BA_ "Description" SG_ 787 MON_StatMngr_Snsr "This value only use for ATCU Library data monitoring (Only use before SOP)";
BA_ "GenSigSendType" SG_ 787 MON_StatMngr_Snsr 4;
BA_ "UserSigValidity" SG_ 787 MON_StatMngr_Snsr 0;
BA_REL_ "GenSigTimeoutTime" BU_SG_REL_ L_ATCU SG_ 787 MON_StatMngr_Snsr 5000;
BA_ "Version" SG_ 787 MON_StatMngr_Snsr "24.09.01";
BA_ "GenMsgSendType" BO_ 788 0;
BA_ "GenMsgCycleTime" BO_ 788 2000;
BA_ "Description" SG_ 788 MON_StatMngr_2ndHumid "This value only use for ATCU Library data monitoring (Only use before SOP)";
BA_ "GenSigSendType" SG_ 788 MON_StatMngr_2ndHumid 4;
BA_ "UserSigValidity" SG_ 788 MON_StatMngr_2ndHumid 0;
BA_REL_ "GenSigTimeoutTime" BU_SG_REL_ L_ATCU SG_ 788 MON_StatMngr_2ndHumid 5000;
BA_ "Version" SG_ 788 MON_StatMngr_2ndHumid "24.09.01";
BA_ "GenMsgSendType" BO_ 789 0;
BA_ "GenMsgCycleTime" BO_ 789 2000;
BA_ "Description" SG_ 789 MON_StatMngr_2ndTemp "This value only use for ATCU Library data monitoring (Only use before SOP)";
BA_ "GenSigSendType" SG_ 789 MON_StatMngr_2ndTemp 4;
BA_ "UserSigValidity" SG_ 789 MON_StatMngr_2ndTemp 0;
BA_REL_ "GenSigTimeoutTime" BU_SG_REL_ L_ATCU SG_ 789 MON_StatMngr_2ndTemp 5000;
BA_ "Version" SG_ 789 MON_StatMngr_2ndTemp "24.09.01";
BA_ "GenMsgSendType" BO_ 790 0;
BA_ "GenMsgCycleTime" BO_ 790 2000;
BA_ "Description" SG_ 790 MON_StatMngr_2ndSafetynCool "This value only use for ATCU Library data monitoring (Only use before SOP)";
BA_ "GenSigSendType" SG_ 790 MON_StatMngr_2ndSafetynCool 4;
BA_ "UserSigValidity" SG_ 790 MON_StatMngr_2ndSafetynCool 0;
BA_REL_ "GenSigTimeoutTime" BU_SG_REL_ L_ATCU SG_ 790 MON_StatMngr_2ndSafetynCool 5000;
BA_ "Version" SG_ 790 MON_StatMngr_2ndSafetynCool "24.09.01";
BA_ "GenMsgSendType" BO_ 791 0;
BA_ "GenMsgCycleTime" BO_ 791 2000;
BA_ "Description" SG_ 791 MON_StatMngr_2ndMngr "This value only use for ATCU Library data monitoring (Only use before SOP)";
BA_ "GenSigSendType" SG_ 791 MON_StatMngr_2ndMngr 4;
BA_ "UserSigValidity" SG_ 791 MON_StatMngr_2ndMngr 0;
BA_REL_ "GenSigTimeoutTime" BU_SG_REL_ L_ATCU SG_ 791 MON_StatMngr_2ndMngr 5000;
BA_ "Version" SG_ 791 MON_StatMngr_2ndMngr "24.09.01";
BA_ "GenMsgSendType" BO_ 817 0;
BA_ "GenMsgCycleTime" BO_ 817 500;
BA_ "Description" SG_ 817 L_ATCU_Sys_AutoDrvModState "This value only use for ATCU Library data monitoring (Only use before SOP)";
BA_ "GenSigSendType" SG_ 817 L_ATCU_Sys_AutoDrvModState 4;
BA_ "UserSigValidity" SG_ 817 L_ATCU_Sys_AutoDrvModState 0;
BA_REL_ "GenSigTimeoutTime" BU_SG_REL_ L_ATCU_vMON SG_ 817 L_ATCU_Sys_AutoDrvModState 5000;
BA_ "Version" SG_ 817 L_ATCU_Sys_AutoDrvModState "23.11.10";
BA_ "Description" SG_ 817 L_ATCU_Sys_AutoIntakeState "This value only use for ATCU Library data monitoring (Only use before SOP)";
BA_ "GenSigSendType" SG_ 817 L_ATCU_Sys_AutoIntakeState 4;
BA_ "UserSigValidity" SG_ 817 L_ATCU_Sys_AutoIntakeState 0;
BA_REL_ "GenSigTimeoutTime" BU_SG_REL_ L_ATCU_vMON SG_ 817 L_ATCU_Sys_AutoIntakeState 5000;
BA_ "Version" SG_ 817 L_ATCU_Sys_AutoIntakeState "23.11.10";
BA_ "Description" SG_ 817 L_ATCU_Sys_AutoACState "This value only use for ATCU Library data monitoring (Only use before SOP)";
BA_ "GenSigSendType" SG_ 817 L_ATCU_Sys_AutoACState 4;
BA_ "UserSigValidity" SG_ 817 L_ATCU_Sys_AutoACState 0;
BA_REL_ "GenSigTimeoutTime" BU_SG_REL_ L_ATCU_vMON SG_ 817 L_ATCU_Sys_AutoACState 5000;
BA_ "Version" SG_ 817 L_ATCU_Sys_AutoACState "23.11.10";
BA_ "Description" SG_ 817 L_ATCU_Sys_AutoEvapTargetTemp "This value only use for ATCU Library data monitoring (Only use before SOP)";
BA_ "GenSigSendType" SG_ 817 L_ATCU_Sys_AutoEvapTargetTemp 4;
BA_ "UserSigValidity" SG_ 817 L_ATCU_Sys_AutoEvapTargetTemp 0;
BA_REL_ "GenSigTimeoutTime" BU_SG_REL_ L_ATCU_vMON SG_ 817 L_ATCU_Sys_AutoEvapTargetTemp 5000;
BA_ "Version" SG_ 817 L_ATCU_Sys_AutoEvapTargetTemp "23.11.10";
BA_ "Description" SG_ 817 L_ATCU_Sys_AutoBlrVtgVal "This value only use for ATCU Library data monitoring (Only use before SOP)";
BA_ "GenSigSendType" SG_ 817 L_ATCU_Sys_AutoBlrVtgVal 4;
BA_ "UserSigValidity" SG_ 817 L_ATCU_Sys_AutoBlrVtgVal 0;
BA_REL_ "GenSigTimeoutTime" BU_SG_REL_ L_ATCU_vMON SG_ 817 L_ATCU_Sys_AutoBlrVtgVal 5000;
BA_ "Version" SG_ 817 L_ATCU_Sys_AutoBlrVtgVal "23.11.10";
BA_ "GenMsgSendType" BO_ 818 0;
BA_ "GenMsgCycleTime" BO_ 818 500;
BA_ "Description" SG_ 818 L_ATCU_Sys_AutoAstTargetTempVal "This value only use for ATCU Library data monitoring (Only use before SOP)";
BA_ "GenSigSendType" SG_ 818 L_ATCU_Sys_AutoAstTargetTempVal 4;
BA_ "UserSigValidity" SG_ 818 L_ATCU_Sys_AutoAstTargetTempVal 0;
BA_REL_ "GenSigTimeoutTime" BU_SG_REL_ L_ATCU_vMON SG_ 818 L_ATCU_Sys_AutoAstTargetTempVal 5000;
BA_ "Version" SG_ 818 L_ATCU_Sys_AutoAstTargetTempVal "23.11.10";
BA_ "Description" SG_ 818 L_ATCU_Sys_AutoAstTempDrState "This value only use for ATCU Library data monitoring (Only use before SOP)";
BA_ "GenSigSendType" SG_ 818 L_ATCU_Sys_AutoAstTempDrState 4;
BA_ "UserSigValidity" SG_ 818 L_ATCU_Sys_AutoAstTempDrState 0;
BA_REL_ "GenSigTimeoutTime" BU_SG_REL_ L_ATCU_vMON SG_ 818 L_ATCU_Sys_AutoAstTempDrState 5000;
BA_ "Version" SG_ 818 L_ATCU_Sys_AutoAstTempDrState "23.11.10";
BA_ "Description" SG_ 818 L_ATCU_Sys_AutoDrvTargetTempVal "This value only use for ATCU Library data monitoring (Only use before SOP)";
BA_ "GenSigSendType" SG_ 818 L_ATCU_Sys_AutoDrvTargetTempVal 4;
BA_ "UserSigValidity" SG_ 818 L_ATCU_Sys_AutoDrvTargetTempVal 0;
BA_REL_ "GenSigTimeoutTime" BU_SG_REL_ L_ATCU_vMON SG_ 818 L_ATCU_Sys_AutoDrvTargetTempVal 5000;
BA_ "Version" SG_ 818 L_ATCU_Sys_AutoDrvTargetTempVal "23.11.10";
BA_ "Description" SG_ 818 L_ATCU_Sys_AutoDrvTempDrState "This value only use for ATCU Library data monitoring (Only use before SOP)";
BA_ "GenSigSendType" SG_ 818 L_ATCU_Sys_AutoDrvTempDrState 4;
BA_ "UserSigValidity" SG_ 818 L_ATCU_Sys_AutoDrvTempDrState 0;
BA_REL_ "GenSigTimeoutTime" BU_SG_REL_ L_ATCU_vMON SG_ 818 L_ATCU_Sys_AutoDrvTempDrState 5000;
BA_ "Version" SG_ 818 L_ATCU_Sys_AutoDrvTempDrState "23.11.10";
BA_ "GenMsgSendType" BO_ 819 0;
BA_ "GenMsgCycleTime" BO_ 819 500;
BA_ "Description" SG_ 819 L_ATCU_Sys_Auto2LHBlrVtgVal "This value only use for ATCU Library data monitoring (Only use before SOP)";
BA_ "GenSigSendType" SG_ 819 L_ATCU_Sys_Auto2LHBlrVtgVal 4;
BA_ "UserSigValidity" SG_ 819 L_ATCU_Sys_Auto2LHBlrVtgVal 0;
BA_REL_ "GenSigTimeoutTime" BU_SG_REL_ L_ATCU_vMON SG_ 819 L_ATCU_Sys_Auto2LHBlrVtgVal 5000;
BA_ "Version" SG_ 819 L_ATCU_Sys_Auto2LHBlrVtgVal "23.11.10";
BA_ "Description" SG_ 819 L_ATCU_Sys_Auto2LHModState "This value only use for ATCU Library data monitoring (Only use before SOP)";
BA_ "GenSigSendType" SG_ 819 L_ATCU_Sys_Auto2LHModState 4;
BA_ "UserSigValidity" SG_ 819 L_ATCU_Sys_Auto2LHModState 0;
BA_REL_ "GenSigTimeoutTime" BU_SG_REL_ L_ATCU_vMON SG_ 819 L_ATCU_Sys_Auto2LHModState 5000;
BA_ "Version" SG_ 819 L_ATCU_Sys_Auto2LHModState "23.11.10";
BA_ "Description" SG_ 819 L_ATCU_Sys_Auto2LHTempDrState "This value only use for ATCU Library data monitoring (Only use before SOP)";
BA_ "GenSigSendType" SG_ 819 L_ATCU_Sys_Auto2LHTempDrState 4;
BA_ "UserSigValidity" SG_ 819 L_ATCU_Sys_Auto2LHTempDrState 0;
BA_REL_ "GenSigTimeoutTime" BU_SG_REL_ L_ATCU_vMON SG_ 819 L_ATCU_Sys_Auto2LHTempDrState 5000;
BA_ "Version" SG_ 819 L_ATCU_Sys_Auto2LHTempDrState "23.11.10";
BA_ "Description" SG_ 819 L_ATCU_Sys_AutoHeatloadStep "This value only use for ATCU Library data monitoring (Only use before SOP)";
BA_ "GenSigSendType" SG_ 819 L_ATCU_Sys_AutoHeatloadStep 4;
BA_ "UserSigValidity" SG_ 819 L_ATCU_Sys_AutoHeatloadStep 0;
BA_REL_ "GenSigTimeoutTime" BU_SG_REL_ L_ATCU_vMON SG_ 819 L_ATCU_Sys_AutoHeatloadStep 5000;
BA_ "Version" SG_ 819 L_ATCU_Sys_AutoHeatloadStep "23.11.10";
BA_ "Description" SG_ 819 L_ATCU_Sys_AutoHVPTCDuty "This value only use for ATCU Library data monitoring (Only use before SOP)";
BA_ "GenSigSendType" SG_ 819 L_ATCU_Sys_AutoHVPTCDuty 4;
BA_ "UserSigValidity" SG_ 819 L_ATCU_Sys_AutoHVPTCDuty 0;
BA_REL_ "GenSigTimeoutTime" BU_SG_REL_ L_ATCU_vMON SG_ 819 L_ATCU_Sys_AutoHVPTCDuty 5000;
BA_ "Version" SG_ 819 L_ATCU_Sys_AutoHVPTCDuty "23.11.10";
BA_ "Description" SG_ 819 L_ATCU_Sys_AutoECompRpm "This value only use for ATCU Library data monitoring (Only use before SOP)";
BA_ "GenSigSendType" SG_ 819 L_ATCU_Sys_AutoECompRpm 4;
BA_ "UserSigValidity" SG_ 819 L_ATCU_Sys_AutoECompRpm 0;
BA_REL_ "GenSigTimeoutTime" BU_SG_REL_ L_ATCU_vMON SG_ 819 L_ATCU_Sys_AutoECompRpm 5000;
BA_ "Version" SG_ 819 L_ATCU_Sys_AutoECompRpm "23.11.10";
BA_ "GenMsgSendType" BO_ 820 0;
BA_ "GenMsgCycleTime" BO_ 820 500;
BA_ "Description" SG_ 820 L_ATCU_Sys_DrvMod "This value only use for ATCU Library data monitoring (Only use before SOP)";
BA_ "GenSigSendType" SG_ 820 L_ATCU_Sys_DrvMod 4;
BA_ "UserSigValidity" SG_ 820 L_ATCU_Sys_DrvMod 0;
BA_REL_ "GenSigTimeoutTime" BU_SG_REL_ L_ATCU_vMON SG_ 820 L_ATCU_Sys_DrvMod 5000;
BA_ "Version" SG_ 820 L_ATCU_Sys_DrvMod "23.11.10";
BA_ "Description" SG_ 820 L_ATCU_Sys_DEF "This value only use for ATCU Library data monitoring (Only use before SOP)";
BA_ "GenSigSendType" SG_ 820 L_ATCU_Sys_DEF 4;
BA_ "UserSigValidity" SG_ 820 L_ATCU_Sys_DEF 0;
BA_REL_ "GenSigTimeoutTime" BU_SG_REL_ L_ATCU_vMON SG_ 820 L_ATCU_Sys_DEF 5000;
BA_ "Version" SG_ 820 L_ATCU_Sys_DEF "23.11.10";
BA_ "Description" SG_ 820 L_ATCU_Sys_BlrStep "This value only use for ATCU Library data monitoring (Only use before SOP)";
BA_ "GenSigSendType" SG_ 820 L_ATCU_Sys_BlrStep 4;
BA_ "UserSigValidity" SG_ 820 L_ATCU_Sys_BlrStep 0;
BA_REL_ "GenSigTimeoutTime" BU_SG_REL_ L_ATCU_vMON SG_ 820 L_ATCU_Sys_BlrStep 5000;
BA_ "Version" SG_ 820 L_ATCU_Sys_BlrStep "23.11.10";
BA_ "Description" SG_ 820 L_ATCU_Sys_AstMod "This value only use for ATCU Library data monitoring (Only use before SOP)";
BA_ "GenSigSendType" SG_ 820 L_ATCU_Sys_AstMod 4;
BA_ "UserSigValidity" SG_ 820 L_ATCU_Sys_AstMod 0;
BA_REL_ "GenSigTimeoutTime" BU_SG_REL_ L_ATCU_vMON SG_ 820 L_ATCU_Sys_AstMod 5000;
BA_ "Version" SG_ 820 L_ATCU_Sys_AstMod "23.11.10";
BA_ "Description" SG_ 820 L_ATCU_Sys_Intake "This value only use for ATCU Library data monitoring (Only use before SOP)";
BA_ "GenSigSendType" SG_ 820 L_ATCU_Sys_Intake 4;
BA_ "UserSigValidity" SG_ 820 L_ATCU_Sys_Intake 0;
BA_REL_ "GenSigTimeoutTime" BU_SG_REL_ L_ATCU_vMON SG_ 820 L_ATCU_Sys_Intake 5000;
BA_ "Version" SG_ 820 L_ATCU_Sys_Intake "23.11.10";
BA_ "Description" SG_ 820 L_ATCU_Sys_AC "This value only use for ATCU Library data monitoring (Only use before SOP)";
BA_ "GenSigSendType" SG_ 820 L_ATCU_Sys_AC 4;
BA_ "UserSigValidity" SG_ 820 L_ATCU_Sys_AC 0;
BA_REL_ "GenSigTimeoutTime" BU_SG_REL_ L_ATCU_vMON SG_ 820 L_ATCU_Sys_AC 5000;
BA_ "Version" SG_ 820 L_ATCU_Sys_AC "23.11.10";
BA_ "Description" SG_ 820 L_ATCU_Sys_HVPTCDuty "This value only use for ATCU Library data monitoring (Only use before SOP)";
BA_ "GenSigSendType" SG_ 820 L_ATCU_Sys_HVPTCDuty 4;
BA_ "UserSigValidity" SG_ 820 L_ATCU_Sys_HVPTCDuty 0;
BA_REL_ "GenSigTimeoutTime" BU_SG_REL_ L_ATCU_vMON SG_ 820 L_ATCU_Sys_HVPTCDuty 5000;
BA_ "Version" SG_ 820 L_ATCU_Sys_HVPTCDuty "23.11.10";
BA_ "Description" SG_ 820 L_ATCU_Sys_BlrVtg "This value only use for ATCU Library data monitoring (Only use before SOP)";
BA_ "GenSigSendType" SG_ 820 L_ATCU_Sys_BlrVtg 4;
BA_ "UserSigValidity" SG_ 820 L_ATCU_Sys_BlrVtg 0;
BA_REL_ "GenSigTimeoutTime" BU_SG_REL_ L_ATCU_vMON SG_ 820 L_ATCU_Sys_BlrVtg 5000;
BA_ "Version" SG_ 820 L_ATCU_Sys_BlrVtg "23.11.10";
BA_ "GenMsgSendType" BO_ 821 0;
BA_ "GenMsgCycleTime" BO_ 821 500;
BA_ "Description" SG_ 821 L_ATCU_Sys_EcompRPM "This value only use for ATCU Library data monitoring (Only use before SOP)";
BA_ "GenSigSendType" SG_ 821 L_ATCU_Sys_EcompRPM 4;
BA_ "UserSigValidity" SG_ 821 L_ATCU_Sys_EcompRPM 0;
BA_REL_ "GenSigTimeoutTime" BU_SG_REL_ L_ATCU_vMON SG_ 821 L_ATCU_Sys_EcompRPM 5000;
BA_ "Version" SG_ 821 L_ATCU_Sys_EcompRPM "23.11.10";
BA_ "Description" SG_ 821 L_ATCU_Sys_EvapTargetTemp "This value only use for ATCU Library data monitoring (Only use before SOP)";
BA_ "GenSigSendType" SG_ 821 L_ATCU_Sys_EvapTargetTemp 4;
BA_ "UserSigValidity" SG_ 821 L_ATCU_Sys_EvapTargetTemp 0;
BA_REL_ "GenSigTimeoutTime" BU_SG_REL_ L_ATCU_vMON SG_ 821 L_ATCU_Sys_EvapTargetTemp 5000;
BA_ "Version" SG_ 821 L_ATCU_Sys_EvapTargetTemp "23.11.10";
BA_ "Description" SG_ 821 L_ATCU_Sys_DrvTempDoor "This value only use for ATCU Library data monitoring (Only use before SOP)";
BA_ "GenSigSendType" SG_ 821 L_ATCU_Sys_DrvTempDoor 4;
BA_ "UserSigValidity" SG_ 821 L_ATCU_Sys_DrvTempDoor 0;
BA_REL_ "GenSigTimeoutTime" BU_SG_REL_ L_ATCU_vMON SG_ 821 L_ATCU_Sys_DrvTempDoor 5000;
BA_ "Version" SG_ 821 L_ATCU_Sys_DrvTempDoor "23.11.10";
BA_ "Description" SG_ 821 L_ATCU_Sys_AstTempDoor "This value only use for ATCU Library data monitoring (Only use before SOP)";
BA_ "GenSigSendType" SG_ 821 L_ATCU_Sys_AstTempDoor 4;
BA_ "UserSigValidity" SG_ 821 L_ATCU_Sys_AstTempDoor 0;
BA_REL_ "GenSigTimeoutTime" BU_SG_REL_ L_ATCU_vMON SG_ 821 L_ATCU_Sys_AstTempDoor 5000;
BA_ "Version" SG_ 821 L_ATCU_Sys_AstTempDoor "23.11.10";
BA_ "GenMsgSendType" BO_ 822 0;
BA_ "GenMsgCycleTime" BO_ 822 500;
BA_ "Description" SG_ 822 L_ATCU_Sys_2LHMod "This value only use for ATCU Library data monitoring (Only use before SOP)";
BA_ "GenSigSendType" SG_ 822 L_ATCU_Sys_2LHMod 4;
BA_ "UserSigValidity" SG_ 822 L_ATCU_Sys_2LHMod 0;
BA_REL_ "GenSigTimeoutTime" BU_SG_REL_ L_ATCU_vMON SG_ 822 L_ATCU_Sys_2LHMod 5000;
BA_ "Version" SG_ 822 L_ATCU_Sys_2LHMod "23.11.10";
BA_ "Description" SG_ 822 L_ATCU_Sys_2LHTempDoor "This value only use for ATCU Library data monitoring (Only use before SOP)";
BA_ "GenSigSendType" SG_ 822 L_ATCU_Sys_2LHTempDoor 4;
BA_ "UserSigValidity" SG_ 822 L_ATCU_Sys_2LHTempDoor 0;
BA_REL_ "GenSigTimeoutTime" BU_SG_REL_ L_ATCU_vMON SG_ 822 L_ATCU_Sys_2LHTempDoor 5000;
BA_ "Version" SG_ 822 L_ATCU_Sys_2LHTempDoor "23.11.10";
BA_ "Description" SG_ 822 L_ATCU_Sys_2LHBlrStep "This value only use for ATCU Library data monitoring (Only use before SOP)";
BA_ "GenSigSendType" SG_ 822 L_ATCU_Sys_2LHBlrStep 4;
BA_ "UserSigValidity" SG_ 822 L_ATCU_Sys_2LHBlrStep 0;
BA_REL_ "GenSigTimeoutTime" BU_SG_REL_ L_ATCU_vMON SG_ 822 L_ATCU_Sys_2LHBlrStep 5000;
BA_ "Version" SG_ 822 L_ATCU_Sys_2LHBlrStep "23.11.10";
BA_ "Description" SG_ 822 L_ATCU_Sys_2LHBlrVtg "This value only use for ATCU Library data monitoring (Only use before SOP)";
BA_ "GenSigSendType" SG_ 822 L_ATCU_Sys_2LHBlrVtg 4;
BA_ "UserSigValidity" SG_ 822 L_ATCU_Sys_2LHBlrVtg 0;
BA_REL_ "GenSigTimeoutTime" BU_SG_REL_ L_ATCU_vMON SG_ 822 L_ATCU_Sys_2LHBlrVtg 5000;
BA_ "Version" SG_ 822 L_ATCU_Sys_2LHBlrVtg "23.11.10";
VAL_ 33 L_ATCU_Typ1 0 "Defualt" 1 "Domestic" 2 "General or MiddleEast or Australia" 3 "Europe or Russia" 4 "America" 5 "Canada" 6 "China" 7 "India" 8 "Invalid" 9 "Invalid" 10 "Invalid" 11 "Invalid" 12 "Invalid" 13 "Invalid" 14 "Invalid" 15 "Invalid" ;
VAL_ 33 L_ATCU_TempDispSta 0 "OLD Set Temp Display range" 1 "NEW Set Temp Display Range(Default)" 2 "None Heater Set Temp Display Range" 3 "Error Indicator" ;
VAL_ 33 L_ATCU_StrgWhlHeatingOpt 0 "Not Applied" 1 "Applied(steering wheel applied)" 2 "RESERVED" 3 "Invalid" ;
VAL_ 33 L_ATCU_Drv_SeatOptSta 0 "Init" 1 "Heater only 2step" 2 "Heater only 3step" 3 "Vent only 2step" 4 "Vent only 3step" 5 "Heater and Vent 2step" 6 "Heater and Vent 3step" 7 "Invalid" ;
VAL_ 33 L_ATCU_Ast_SeatOptSta 0 "Init" 1 "Heater only 2step" 2 "Heater only 3step" 3 "Vent only 2step" 4 "Vent only 3step" 5 "Heater and Vent 2step" 6 "Heater and Vent 3step" 7 "Invalid" ;
VAL_ 33 L_ATCU_RL_SeatOptSta 0 "Init" 1 "Heater only 2step" 2 "Heater only 3step" 3 "Vent only 2step" 4 "Vent only 3step" 5 "Heater and Vent 2step" 6 "Heater and Vent 3step" 7 "Invalid" ;
VAL_ 33 L_ATCU_RR_SeatOptSta 0 "Init" 1 "Heater only 2step" 2 "Heater only 3step" 3 "Vent only 2step" 4 "Vent only 3step" 5 "Heater and Vent 2step" 6 "Heater and Vent 3step" 7 "Invalid" ;
VAL_ 33 L_ATCU_SmartZoneDis 0 "Default" 1 "On" 2 "Off" 3 "Invalid" ;
VAL_ 34 L_ATCU_DrTempCDis 0 "Blank Display (Default)" 1 "'LO' Display" 2 "15.0¡É~32.0¡É" 3 "15.0¡É~32.0¡É" 4 "15.0¡É~32.0¡É" 5 "15.0¡É~32.0¡É" 6 "15.0¡É~32.0¡É" 7 "15.0¡É~32.0¡É" 8 "15.0¡É~32.0¡É" 9 "15.0¡É~32.0¡É" 10 "15.0¡É~32.0¡É" 11 "15.0¡É~32.0¡É" 12 "15.0¡É~32.0¡É" 13 "15.0¡É~32.0¡É" 14 "15.0¡É~32.0¡É" 15 "15.0¡É~32.0¡É" 16 "15.0¡É~32.0¡É" 17 "15.0¡É~32.0¡É" 18 "15.0¡É~32.0¡É" 19 "15.0¡É~32.0¡É" 20 "15.0¡É~32.0¡É" 21 "15.0¡É~32.0¡É" 22 "15.0¡É~32.0¡É" 23 "15.0¡É~32.0¡É" 24 "15.0¡É~32.0¡É" 25 "15.0¡É~32.0¡É" 26 "15.0¡É~32.0¡É" 27 "15.0¡É~32.0¡É" 28 "15.0¡É~32.0¡É" 29 "15.0¡É~32.0¡É" 30 "15.0¡É~32.0¡É" 31 "15.0¡É~32.0¡É" 32 "15.0¡É~32.0¡É" 33 "15.0¡É~32.0¡É" 34 "15.0¡É~32.0¡É" 35 "15.0¡É~32.0¡É" 36 "15.0¡É~32.0¡É" 37 "25~0xFD:RESERVED" 253 "25~0xFD:RESERVED" 254 "'HI' Display" 255 "Error Indicator" ;
VAL_ 34 L_ATCU_DrTempFDis 0 "Blank Display(Default)" 1 "'LO' Display" 2 "58¢µ~92¢µ" 3 "58¢µ~92¢µ" 4 "58¢µ~92¢µ" 5 "58¢µ~92¢µ" 6 "58¢µ~92¢µ" 7 "58¢µ~92¢µ" 8 "58¢µ~92¢µ" 9 "58¢µ~92¢µ" 10 "58¢µ~92¢µ" 11 "58¢µ~92¢µ" 12 "58¢µ~92¢µ" 13 "58¢µ~92¢µ" 14 "58¢µ~92¢µ" 15 "58¢µ~92¢µ" 16 "58¢µ~92¢µ" 17 "58¢µ~92¢µ" 18 "58¢µ~92¢µ" 19 "58¢µ~92¢µ" 20 "58¢µ~92¢µ" 21 "58¢µ~92¢µ" 22 "58¢µ~92¢µ" 23 "58¢µ~92¢µ" 24 "58¢µ~92¢µ" 25 "58¢µ~92¢µ" 26 "58¢µ~92¢µ" 27 "58¢µ~92¢µ" 28 "58¢µ~92¢µ" 29 "58¢µ~92¢µ" 30 "58¢µ~92¢µ" 31 "58¢µ~92¢µ" 32 "58¢µ~92¢µ" 33 "58¢µ~92¢µ" 34 "58¢µ~92¢µ" 35 "58¢µ~92¢µ" 36 "58¢µ~92¢µ" 37 "25~0xFD:RESERVED" 253 "25~0xFD:RESERVED" 254 "'HI' Display" 255 "Error Indicator" ;
VAL_ 34 L_ATCU_PassTempFDis 0 "Blank Display(Default)" 1 "'LO' Display" 2 "58¢µ~92¢µ" 3 "58¢µ~92¢µ" 4 "58¢µ~92¢µ" 5 "58¢µ~92¢µ" 6 "58¢µ~92¢µ" 7 "58¢µ~92¢µ" 8 "58¢µ~92¢µ" 9 "58¢µ~92¢µ" 10 "58¢µ~92¢µ" 11 "58¢µ~92¢µ" 12 "58¢µ~92¢µ" 13 "58¢µ~92¢µ" 14 "58¢µ~92¢µ" 15 "58¢µ~92¢µ" 16 "58¢µ~92¢µ" 17 "58¢µ~92¢µ" 18 "58¢µ~92¢µ" 19 "58¢µ~92¢µ" 20 "58¢µ~92¢µ" 21 "58¢µ~92¢µ" 22 "58¢µ~92¢µ" 23 "58¢µ~92¢µ" 24 "58¢µ~92¢µ" 25 "58¢µ~92¢µ" 26 "58¢µ~92¢µ" 27 "58¢µ~92¢µ" 28 "58¢µ~92¢µ" 29 "58¢µ~92¢µ" 30 "58¢µ~92¢µ" 31 "58¢µ~92¢µ" 32 "58¢µ~92¢µ" 33 "58¢µ~92¢µ" 34 "58¢µ~92¢µ" 35 "58¢µ~92¢µ" 36 "58¢µ~92¢µ" 37 "25~0xFD:RESERVED" 253 "25~0xFD:RESERVED" 254 "'HI' Display" 255 "Error Indicator" ;
VAL_ 34 L_ATCU_FrDrModDis 0 "Off(Blank Display, Vent mode not Display ex) Auto(Default)" 1 "VENT" 2 "B_L" 3 "FLOOR" 4 "MIX (7 MODE DEF FLOOR)" 5 "DEF (MAX DEF)" 6 "AUTO DEFOG" 7 "7 MODE DEF VENT" 8 "MODE AUTO" 9 "7 MODE DEF VENT FLOOR" 10 "7 MODE DEF" 11 "DEF VENT (Arrow)" 12 "DEF FLOOR (Arrow)" 13 "DEF VENT FLOOR (Arrow)" 14 "DEF (Arrow)" 15 "Error Indicator" ;
VAL_ 34 L_ATCU_FrPassModDis 0 "Off(Blank Display, Vent mode not Display ex) Auto(Default)" 1 "VENT" 2 "B_L" 3 "FLOOR" 4 "MIX (7 MODE DEF FLOOR)" 5 "DEF (MAX DEF)" 6 "AUTO DEFOG" 7 "7 MODE DEF VENT" 8 "MODE AUTO" 9 "7 MODE DEF VENT FLOOR" 10 "7 MODE DEF" 11 "DEF VENT (Arrow)" 12 "DEF FLOOR (Arrow)" 13 "DEF VENT FLOOR (Arrow)" 14 "DEF (Arrow)" 15 "Error Indicator" ;
VAL_ 34 L_ATCU_FrDrBlwDis 0 "OFF(System Off)" 1 "Blank Display(No Blower level display, ex)Auto" 2 "1 Level" 3 "2 Level" 4 "3 Level" 5 "4 Level" 6 "5 Level" 7 "6 Level" 8 "7 Level" 9 "8 Level" 10 "Not used" 11 "Not used" 12 "Not used" 13 "Not used" 14 "Not used" 15 "Error Indicator" ;
VAL_ 34 L_ATCU_FrPassBlwDis 0 "OFF(System Off)" 1 "Blank Display(No Blower level display, ex)Auto" 2 "1 Level" 3 "2 Level" 4 "3 Level" 5 "4 Level" 6 "5 Level" 7 "6 Level" 8 "7 Level" 9 "8 Level" 10 "Not used" 11 "Not used" 12 "Not used" 13 "Not used" 14 "Not used" 15 "Error Indicator" ;
VAL_ 34 L_ATCU_DrAutoDis 0 "DrAUTO Off" 1 "DrAUTO On" 2 "Not used" 3 "Error Indicator" ;
VAL_ 34 L_ATCU_PassAutoDis 0 "PsAUTO Off" 1 "PsAUTO On" 2 "Not used" 3 "Error Indicator" ;
VAL_ 34 L_ATCU_DrMultiAutoBlwDis 0 "MultiAutoBlr Display Off" 1 "Multi Auto Blower Low" 2 "Multi Auto Blower Mid" 3 "Multi Auto Blower High" ;
VAL_ 34 L_ATCU_PassMultiAutoBlwDis 0 "MultiAutoBlr Display Off" 1 "Multi Auto Blower Low" 2 "Multi Auto Blower Mid" 3 "Multi Auto Blower High" ;
VAL_ 34 L_ATCU_AcDis 0 "A/C Off" 1 "A/C ON" 2 "Not used" 3 "Error Indicator" ;
VAL_ 34 L_ATCU_IntakeDis 0 "Default(Fresh off & Rec off)" 1 "REC (Fresh off)" 2 "FRE (REC off)" 3 "Error Indicator" ;
VAL_ 34 L_ATCU_SyncDis 0 "SYNC Off" 1 "SYNC On" 2 "Not used" 3 "Error Indicator" ;
VAL_ 34 L_ATCU_FrDefDis 0 "Front Def Off" 1 "Front Def On" 2 "Not used" 3 "Error Indicator" ;
VAL_ 34 L_ATCU_PassTempCDis 0 "Blank Display (Default)" 1 "'LO' Display" 2 "15.0¡É~32.0¡É" 3 "15.0¡É~32.0¡É" 4 "15.0¡É~32.0¡É" 5 "15.0¡É~32.0¡É" 6 "15.0¡É~32.0¡É" 7 "15.0¡É~32.0¡É" 8 "15.0¡É~32.0¡É" 9 "15.0¡É~32.0¡É" 10 "15.0¡É~32.0¡É" 11 "15.0¡É~32.0¡É" 12 "15.0¡É~32.0¡É" 13 "15.0¡É~32.0¡É" 14 "15.0¡É~32.0¡É" 15 "15.0¡É~32.0¡É" 16 "15.0¡É~32.0¡É" 17 "15.0¡É~32.0¡É" 18 "15.0¡É~32.0¡É" 19 "15.0¡É~32.0¡É" 20 "15.0¡É~32.0¡É" 21 "15.0¡É~32.0¡É" 22 "15.0¡É~32.0¡É" 23 "15.0¡É~32.0¡É" 24 "15.0¡É~32.0¡É" 25 "15.0¡É~32.0¡É" 26 "15.0¡É~32.0¡É" 27 "15.0¡É~32.0¡É" 28 "15.0¡É~32.0¡É" 29 "15.0¡É~32.0¡É" 30 "15.0¡É~32.0¡É" 31 "15.0¡É~32.0¡É" 32 "15.0¡É~32.0¡É" 33 "15.0¡É~32.0¡É" 34 "15.0¡É~32.0¡É" 35 "15.0¡É~32.0¡É" 36 "15.0¡É~32.0¡É" 37 "25~0xFD:RESERVED" 253 "25~0xFD:RESERVED" 254 "'HI' Display" 255 "Error Indicator" ;
VAL_ 35 L_ATCU_DrOnlyDis 0 "Initial (Dual Temp Display)" 1 "Driver Only Status (Only Display Driver Temp)" 2 "Not used" 3 "Error Indicator" ;
VAL_ 35 L_ATCU_SmrtVntDis 0 "Off" 1 "Smart Ventilation" 2 "Smart CO2" 3 "Error Indicator" ;
VAL_ 35 L_ATCU_FrWndShldHtInd 0 "Off" 1 "On" 2 "RESERVED" ;
VAL_ 35 L_ATCU_IncarMtrOnReq 0 "OFF" 1 "ON" ;
VAL_ 35 L_ATCU_LanguageInfo 0 "Off" 1 "Korea" 2 "English(US)" 3 "English(UK)" 4 "Simplified chinese" 5 "Traditional chinese" 6 "French(EU)" 7 "Spanish(EU)" 8 "Arabic" 9 "Czech" 10 "Danish" 11 "German" 12 "Italian" 13 "Dutch" 14 "Polish" 15 "Portuguese" 16 "Russain" 17 "Slovak" 18 "Swedish" 19 "Turkish" 20 "French(US)" 21 "Spanish(US)" 22 "English(India)" 23 "Norwegian" 24 "Finnish" 25 "Indonesian" 26 "Brazilian Portuguese" 27 "Malay" 28 "Hungarian" 29 "English (Australia)" 30 "Japanese" 31 "Hindi" 32 "Hebrew" 33 "Greek" 34 "Ukrainian" 35 "Slovenian" 36 "Bulgarian" 37 "Croatian" 38 "Romanian" 39 "Bengali" 40 "Marathi" 41 "Telugu" 42 "Tamil" 43 "Gujarati" 44 "Kannada" 45 "Odia" 46 "Malayalam" 47 "Punjabi" 48 "Thai" 49 "Tagalog" 50 "Vietnamese" 51 "33~0xFE:RESERVED" 254 "33~0xFE:RESERVED" 255 "Invalid" ;
VAL_ 35 L_ATCU_RrDefInd 0 "OFF" 1 "ON" ;
VAL_ 35 L_ATCU_AfterBlowDisplay 0 "Default" 1 "AfterBlower Waiting" 2 "AfterBlower Operating(Symbol Off)" 3 "AfterBlower Operating(Symbol On)" ;
VAL_ 35 L_ATCU_SchdldVentDisplay 0 "Default" 1 "SchdldVent Waiting" 2 "SchdldVent Operating(Symbol Off)" 3 "SchdldVent Operating(Symbol On)" ;
VAL_ 35 L_ATCU_FLStHeatSwHInd 0 "OFF" 1 "ON" ;
VAL_ 35 L_ATCU_FLStHeatSwMInd 0 "OFF" 1 "ON" ;
VAL_ 35 L_ATCU_ADSBlinkDis 0 "AutoDefogBlink Non Request" 1 "AutoDefogBlink Request" 2 "Not used" 3 "Error Indicator" ;
VAL_ 35 L_ATCU_FLStHeatSwLInd 0 "OFF" 1 "ON" ;
VAL_ 35 L_ATCU_FLStVntSwHInd 0 "OFF" 1 "ON" ;
VAL_ 35 L_ATCU_FLStVntSwMInd 0 "OFF" 1 "ON" ;
VAL_ 35 L_ATCU_FLStVntSwLInd 0 "OFF" 1 "ON" ;
VAL_ 35 L_ATCU_FRStHeatSwHInd 0 "OFF" 1 "ON" ;
VAL_ 35 L_ATCU_FRStHeatSwMInd 0 "OFF" 1 "ON" ;
VAL_ 35 L_ATCU_FRStHeatSwLInd 0 "OFF" 1 "ON" ;
VAL_ 35 L_ATCU_FRStVntSwHInd 0 "OFF" 1 "ON" ;
VAL_ 35 L_ATCU_FRStVntSwMInd 0 "OFF" 1 "ON" ;
VAL_ 35 L_ATCU_FRStVntSwLInd 0 "OFF" 1 "ON" ;
VAL_ 35 L_ATCU_StrWhlHeatInd 0 "OFF" 1 "Step1" 2 "Step2" 3 "RESERVED" ;
VAL_ 35 L_ATCU_RhstaLvlSta 0 "RESERVED" 1 "Step1" 2 "Step2" 3 "Step 3" 4 "Step 4" 5 "Step5" 6 "Step 6" 7 "Step 7" 8 "Step8" 9 "Step 9" 10 "Step 10" 11 "Step11" 12 "Step 12" 13 "Step 13" 14 "Step14" 15 "Step 15" 16 "Step 16" 17 "Step17" 18 "Step 18" 19 "Step 19" 20 "Step 20 (Reset Value)" 21 "Step 21(Detent)" ;
VAL_ 35 L_ATCU_IntTailOnOff 0 "OFF" 1 "ON" ;
VAL_ 35 L_ATCU_AutoLightSta 0 "Off (not Night)" 1 "Night" ;
VAL_ 35 L_ATCU_FrBckLightSta 0 "OFF" 1 "ON" ;
VAL_ 35 L_ATCU_DisplayTheme 0 "Default" 1 "White Theme" 2 "Black Theme" 3 "Invalid" ;
VAL_ 35 L_ATCU_GUIBlankDis 0 "Default" 1 "GUI Blank Display" ;
VAL_ 35 L_ATCU_HptIntnstySet 0 "Default" 1 "Haptic OFF" 2 "Haptic Intensity Level 1" 3 "Haptic Intensity Level 2" 4 "Haptic Intensity Level 3" 5 "Haptic Intensity Level 4" 6 "Haptic Intensity Level 5" 7 "RESERVED" 8 "RESERVED" 9 "RESERVED" 10 "RESERVED" 11 "RESERVED" 12 "RESERVED" 13 "RESERVED" 14 "RESERVED" 15 "Invalid" ;
VAL_ 35 L_ATCU_TlltLmpDis 0 "ON Lamp off OFF Lamp off" 1 "ON Lamp off OFF Lamp on" 2 "ON Lamp on Off Lamp off" 3 "ON Lamp on OFF Lamp on" 4 "RESERVED" 5 "RESERVED" 6 "RESERVED" 7 "Error Indicator" ;
VAL_ 35 L_ATCU_AvTailOnOff 0 "OFF" 1 "ON" ;
VAL_ 35 L_ATCU_SchdldClimateDisplay 0 "Reservation Not Set" 1 "Reservation Set" 2 "Not used" 3 "Error Indicator" ;
VAL_ 35 L_ATCU_AirClnDis 0 "AirClean Off" 1 "AirClean On" 2 "Not used" 3 "Error Indicator" ;
VAL_ 35 L_ATCU_CO2WrngDis 0 "Co2 Warning Off" 1 "Co2 Warning On" 2 "Not used" 3 "Error Indicator" ;
VAL_ 38 L_ATCU_3rdRrTempCDis 0 "Blank Display (Default)" 1 "'LO' Display" 2 "15.0¡É~32.0¡É" 3 "15.0¡É~32.0¡É" 4 "15.0¡É~32.0¡É" 5 "15.0¡É~32.0¡É" 6 "15.0¡É~32.0¡É" 7 "15.0¡É~32.0¡É" 8 "15.0¡É~32.0¡É" 9 "15.0¡É~32.0¡É" 10 "15.0¡É~32.0¡É" 11 "15.0¡É~32.0¡É" 12 "15.0¡É~32.0¡É" 13 "15.0¡É~32.0¡É" 14 "15.0¡É~32.0¡É" 15 "15.0¡É~32.0¡É" 16 "15.0¡É~32.0¡É" 17 "15.0¡É~32.0¡É" 18 "15.0¡É~32.0¡É" 19 "15.0¡É~32.0¡É" 20 "15.0¡É~32.0¡É" 21 "15.0¡É~32.0¡É" 22 "15.0¡É~32.0¡É" 23 "15.0¡É~32.0¡É" 24 "15.0¡É~32.0¡É" 25 "15.0¡É~32.0¡É" 26 "15.0¡É~32.0¡É" 27 "15.0¡É~32.0¡É" 28 "15.0¡É~32.0¡É" 29 "15.0¡É~32.0¡É" 30 "15.0¡É~32.0¡É" 31 "15.0¡É~32.0¡É" 32 "15.0¡É~32.0¡É" 33 "15.0¡É~32.0¡É" 34 "15.0¡É~32.0¡É" 35 "15.0¡É~32.0¡É" 36 "15.0¡É~32.0¡É" 37 "25~0xFD:RESERVED" 253 "25~0xFD:RESERVED" 254 "'HI' Display" 255 "Error Indicator" ;
VAL_ 38 L_ATCU_3rdRrModDis 0 "Off(Blank Display, Vent mode not Display ex) Auto" 1 "VENT" 2 "B_L" 3 "FLOOR" 4 "MIX" 5 "DEF(Including Max DEF)" 6 "AUTO DEFOG" 7 "Def (7 mode only)" 8 "DefVent(7 mode only)" 9 "DefFL(7 mode only)" 10 "VentFL(7 mode only)" 11 "DefVentFL(7 mode only)" 12 "Not used" 13 "Not used" 14 "Not used" 15 "Error Indicator" ;
VAL_ 38 L_ATCU_3rdRrBlwDis 0 "OFF(System Off)" 1 "Blank Display(Blower Level no display, ex)Auto mode)" 2 "1 Level" 3 "2 Level" 4 "3 Level" 5 "4 Level" 6 "5 Level" 7 "6 Level" 8 "7 Level" 9 "8 Level" 10 "Not used" 11 "Not used" 12 "Not used" 13 "Not used" 14 "Not used" 15 "Error Indicator" ;
VAL_ 38 L_ATCU_3rdRrAutoDis 0 "3rdRrAUTO Off" 1 "3rdRrAUTO On" 2 "Not used" 3 "Error Indicator" ;
VAL_ 38 L_ATCU_3rdRrMultiAutoBlwDis 0 "MultiAutoBlr Display Off" 1 "Multi Auto Blower Low" 2 "Multi Auto Blower Mid" 3 "Multi Auto Blower High" 4 "RESERVED" 5 "RESERVED" 6 "RESERVED" 7 "Error Indicator" ;
VAL_ 38 L_ATCU_3rdRrSyncDis 0 "RearAc Off" 1 "RearAc On" 2 "Not Used" 3 "Error Indicator" ;
VAL_ 38 L_ATCU_3rdRrOnInd 0 "Off" 1 "On" 2 "RESERVED" ;
VAL_ 38 L_ATCU_3rdRrLockDis 0 "RearLock Off" 1 "RearLock On" 2 "Not Used" 3 "Error Indicator" ;
VAL_ 38 L_ATCU_3rdRrLcdBckLightSta 0 "OFF" 1 "ON" ;
VAL_ 38 L_ATCU_3rdRrGUIBlankDis 0 "OFF" 1 "ON" ;
VAL_ 38 L_ATCU_3rdRLStHeatSwHInd 0 "OFF" 1 "ON" ;
VAL_ 38 L_ATCU_3rdRLStHeatSwMInd 0 "OFF" 1 "ON" ;
VAL_ 38 L_ATCU_3rdRLStHeatSwLInd 0 "OFF" 1 "ON" ;
VAL_ 38 L_ATCU_3rdRLStVntSwHInd 0 "OFF" 1 "ON" ;
VAL_ 38 L_ATCU_3rdRLStVntSwMInd 0 "OFF" 1 "ON" ;
VAL_ 38 L_ATCU_3rdRLStVntSwLInd 0 "OFF" 1 "ON" ;
VAL_ 38 L_ATCU_3rdRRStHeatSwHInd 0 "OFF" 1 "ON" ;
VAL_ 38 L_ATCU_3rdRRStHeatSwMInd 0 "OFF" 1 "ON" ;
VAL_ 38 L_ATCU_3rdRRStHeatSwLInd 0 "OFF" 1 "ON" ;
VAL_ 38 L_ATCU_3rdRRStVntSwHInd 0 "OFF" 1 "ON" ;
VAL_ 38 L_ATCU_3rdRRStVntSwMInd 0 "OFF" 1 "ON" ;
VAL_ 38 L_ATCU_3rdRRStVntSwLInd 0 "OFF" 1 "ON" ;
VAL_ 38 L_ATCU_3rdRrMTCOpSta 0 "DATC Off (Power Down)" 1 "DATC Normal" 2 "DATC System Off (Blower Off)" 3 "Error Indicator" ;
VAL_ 38 L_ATCU_3rdRrMtcTempLvl 0 "Off" 1 "Level 1" 2 "Level 2" 3 "Level 3" 4 "Level 4" 5 "Level 5" 6 "Level 6" 7 "Level 7" 8 "Level 8" ;
VAL_ 38 L_ATCU_3rdAUTOStep 0 "Default" 1 "OFF" 2 "1st & 2nd & 3rd On (3 Step Type)" 3 "1st & 2nd On (3 Step Type)" 4 "1st On (3 Step Type)" 5 "1st & 2nd On (2 Step Type)" 6 "1st On (2 Step Type)" 7 "Error Indicator" ;
VAL_ 38 L_ATCU_RrPassMultiAutoBlwDis 0 "MultiAutoBlr Display Off" 1 "Multi Auto Blower Low" 2 "Multi Auto Blower Mid" 3 "Multi Auto Blower High" 4 "RESERVED" 5 "RESERVED" 6 "RESERVED" 7 "Error Indicator" ;
VAL_ 38 L_ATCU_DisPnlState 0 "Front Display State(Default)" 1 "Rear Display State" 2 "RESERVED" 3 "Error Indicator" ;
VAL_ 38 L_ATCU_3rdRrTempFDis 0 "Blank Display(Default)" 1 "'LO' Display" 2 "58¢µ~92¢µ" 3 "58¢µ~92¢µ" 4 "58¢µ~92¢µ" 5 "58¢µ~92¢µ" 6 "58¢µ~92¢µ" 7 "58¢µ~92¢µ" 8 "58¢µ~92¢µ" 9 "58¢µ~92¢µ" 10 "58¢µ~92¢µ" 11 "58¢µ~92¢µ" 12 "58¢µ~92¢µ" 13 "58¢µ~92¢µ" 14 "58¢µ~92¢µ" 15 "58¢µ~92¢µ" 16 "58¢µ~92¢µ" 17 "58¢µ~92¢µ" 18 "58¢µ~92¢µ" 19 "58¢µ~92¢µ" 20 "58¢µ~92¢µ" 21 "58¢µ~92¢µ" 22 "58¢µ~92¢µ" 23 "58¢µ~92¢µ" 24 "58¢µ~92¢µ" 25 "58¢µ~92¢µ" 26 "58¢µ~92¢µ" 27 "58¢µ~92¢µ" 28 "58¢µ~92¢µ" 29 "58¢µ~92¢µ" 30 "58¢µ~92¢µ" 31 "58¢µ~92¢µ" 32 "58¢µ~92¢µ" 33 "58¢µ~92¢µ" 34 "58¢µ~92¢µ" 35 "58¢µ~92¢µ" 36 "58¢µ~92¢µ" 37 "25~0xFD:RESERVED" 253 "25~0xFD:RESERVED" 254 "'HI' Display" 255 "Error Indicator" ;
VAL_ 39 L_ATCU_RrHVACTempActrTgt 0 "0x0~0x3FF:AD = Factor*Hex + Offset" 1023 "0x0~0x3FF:AD = Factor*Hex + Offset" ;
VAL_ 39 L_ATCU_RrHVACTempAsstActrTgt 0 "0x0~0x3FF:AD = Factor*Hex + Offset" 1023 "0x0~0x3FF:AD = Factor*Hex + Offset" ;
VAL_ 39 L_ATCU_RrDrHVACModeActrTgt 0 "0x0~0x3FF:AD = Factor*Hex + Offset" 1023 "0x0~0x3FF:AD = Factor*Hex + Offset" ;
VAL_ 39 L_ATCU_RrHVACBlowerTgtV 0 "0x0~0xFF:V = Factor*Hex + Offset" 255 "0x0~0xFF:V = Factor*Hex + Offset" ;
VAL_ 39 L_ATCU_RrHVACBLDCRpmVal 0 "0x0~0x1388:Factor * Hex + Offset" 5000 "0x0~0x1388:Factor * Hex + Offset" 5001 "1389~0x7FFF:RESERVED" 32767 "1389~0x7FFF:RESERVED" ;
VAL_ 39 L_ATCU_RrPsHVACModeActrTgt 0 "0x0~0x3FF:AD=Factor*Hex + Offset" 1023 "0x0~0x3FF:AD=Factor*Hex + Offset" ;
VAL_ 273 L_ATCU_FHPTCOpPrmssnSta 0 "Not Permiited" 1 "Permitted" ;
VAL_ 273 L_ATCU_FHPTCPassTrgtDty 0 "0x0~0xC8:Duty" 200 "0x0~0xC8:Duty" 201 "RESERVED" 202 "RESERVED" 203 "RESERVED" 204 "RESERVED" 205 "RESERVED" 206 "RESERVED" 207 "RESERVED" 208 "RESERVED" 209 "RESERVED" 210 "RESERVED" 211 "RESERVED" 212 "RESERVED" 213 "RESERVED" 214 "RESERVED" 215 "RESERVED" 216 "RESERVED" 217 "RESERVED" 218 "RESERVED" 219 "RESERVED" 220 "RESERVED" 221 "RESERVED" 222 "RESERVED" 223 "RESERVED" 224 "RESERVED" 225 "RESERVED" 226 "RESERVED" 227 "RESERVED" 228 "RESERVED" 229 "RESERVED" 230 "RESERVED" 231 "RESERVED" 232 "RESERVED" 233 "RESERVED" 234 "RESERVED" 235 "RESERVED" 236 "RESERVED" 237 "RESERVED" 238 "RESERVED" 239 "RESERVED" 240 "RESERVED" 241 "RESERVED" 242 "RESERVED" 243 "RESERVED" 244 "RESERVED" 245 "RESERVED" 246 "RESERVED" 247 "RESERVED" 248 "RESERVED" 249 "RESERVED" 250 "RESERVED" 251 "RESERVED" 252 "RESERVED" 253 "RESERVED" 254 "RESERVED" 255 "ERROR" ;
VAL_ 273 L_ATCU_FHPTCDischrgReq 0 "Non-Request" 1 "Request" ;
VAL_ 273 L_ATCU_FltMsgTmOutFHPTC1 0 "Normal" 1 "Message Timeout" ;
VAL_ 273 L_ATCU_FltMsgTmOutFHPTC2 0 "Normal" 1 "Message Timeout" ;
VAL_ 273 L_ATCU_FltMsgTmOutFHPTC3 0 "Normal" 1 "Message Timeout" ;
VAL_ 273 L_ATCU_FltMsgTmOutFHPTC4 0 "Normal" 1 "Message Timeout" ;
VAL_ 273 L_ATCU_FrBlwLvl 0 "OFF" 1 "0 level" 2 "1 level" 3 "2 level" 4 "3 level" 5 "4 level" 6 "5 level" 7 "6 level" 8 "7 evel" 9 "8 level" 10 "RESERVED" 11 "RESERVED" 12 "RESERVED" 13 "RESERVED" 14 "RESERVED" 15 "Error Indicator" ;
VAL_ 273 L_ATCU_FrBlwLvlSigVaildSta 0 "Invaild (Blower Level Info Not supported)" 1 "Vaild (Blower Level Info Supported) (Initial Value:0H)" ;
VAL_ 273 L_ATCU_DrvrSdTyp 0 "LHD" 1 "RHD" ;
VAL_ 273 L_ATCU_FrBlwFltSta 0 "Normal" 1 "Blower Fault" ;
VAL_ 273 L_ATCU_PassBlwLvl 0 "OFF(Default)" 1 "0 Level" 2 "1 Level" 3 "2 Level" 4 "3 Level" 5 "4 Level" 6 "5 Level" 7 "6 Level" 8 "7 Level" 9 "8 Level" 10 "RESERVED" 11 "RESERVED" 12 "RESERVED" 13 "RESERVED" 14 "RESERVED" 15 "Error Indicator" ;
VAL_ 273 L_ATCU_FHPTCDrTrgtDty 0 "0x0~0xC8:Duty" 200 "0x0~0xC8:Duty" 201 "RESERVED" 202 "RESERVED" 203 "RESERVED" 204 "RESERVED" 205 "RESERVED" 206 "RESERVED" 207 "RESERVED" 208 "RESERVED" 209 "RESERVED" 210 "RESERVED" 211 "RESERVED" 212 "RESERVED" 213 "RESERVED" 214 "RESERVED" 215 "RESERVED" 216 "RESERVED" 217 "RESERVED" 218 "RESERVED" 219 "RESERVED" 220 "RESERVED" 221 "RESERVED" 222 "RESERVED" 223 "RESERVED" 224 "RESERVED" 225 "RESERVED" 226 "RESERVED" 227 "RESERVED" 228 "RESERVED" 229 "RESERVED" 230 "RESERVED" 231 "RESERVED" 232 "RESERVED" 233 "RESERVED" 234 "RESERVED" 235 "RESERVED" 236 "RESERVED" 237 "RESERVED" 238 "RESERVED" 239 "RESERVED" 240 "RESERVED" 241 "RESERVED" 242 "RESERVED" 243 "RESERVED" 244 "RESERVED" 245 "RESERVED" 246 "RESERVED" 247 "RESERVED" 248 "RESERVED" 249 "RESERVED" 250 "RESERVED" 251 "RESERVED" 252 "RESERVED" 253 "RESERVED" 254 "RESERVED" 255 "ERROR" ;
VAL_ 274 L_ATCU_RHPTCOpPrmssnSta 0 "Operation is not allowed" 1 "Operation is allowed" ;
VAL_ 274 L_ATCU_RHPTCZone2TrgtDty 0 "0x0~0xC8:Duty" 200 "0x0~0xC8:Duty" 201 "RESERVED" 202 "RESERVED" 203 "RESERVED" 204 "RESERVED" 205 "RESERVED" 206 "RESERVED" 207 "RESERVED" 208 "RESERVED" 209 "RESERVED" 210 "RESERVED" 211 "RESERVED" 212 "RESERVED" 213 "RESERVED" 214 "RESERVED" 215 "RESERVED" 216 "RESERVED" 217 "RESERVED" 218 "RESERVED" 219 "RESERVED" 220 "RESERVED" 221 "RESERVED" 222 "RESERVED" 223 "RESERVED" 224 "RESERVED" 225 "RESERVED" 226 "RESERVED" 227 "RESERVED" 228 "RESERVED" 229 "RESERVED" 230 "RESERVED" 231 "RESERVED" 232 "RESERVED" 233 "RESERVED" 234 "RESERVED" 235 "RESERVED" 236 "RESERVED" 237 "RESERVED" 238 "RESERVED" 239 "RESERVED" 240 "RESERVED" 241 "RESERVED" 242 "RESERVED" 243 "RESERVED" 244 "RESERVED" 245 "RESERVED" 246 "RESERVED" 247 "RESERVED" 248 "RESERVED" 249 "RESERVED" 250 "RESERVED" 251 "RESERVED" 252 "RESERVED" 253 "RESERVED" 254 "RESERVED" 255 "ERROR" ;
VAL_ 274 L_ATCU_RHPTCDischrgReq 0 "Non-Request" 1 "Request" ;
VAL_ 274 L_ATCU_FltMsgTmOutRHPTC1 0 "Normal" 1 "Message Timeout" ;
VAL_ 274 L_ATCU_FltMsgTmOutRHPTC2 0 "Normal" 1 "Message Timeout" ;
VAL_ 274 L_ATCU_FltMsgTmOutRHPTC3 0 "Normal" 1 "Message Timeout" ;
VAL_ 274 L_ATCU_FltMsgTmOutRHPTC4 0 "Normal" 1 "Message Timeout" ;
VAL_ 274 L_ATCU_RrBlwLvl 0 "OFF" 1 "0 level" 2 "1 level" 3 "2 level" 4 "3 level" 5 "4 level" 6 "5 level" 7 "6 level" 8 "7 evel" 9 "8 level" 10 "RESERVED" 11 "RESERVED" 12 "RESERVED" 13 "RESERVED" 14 "RESERVED" 15 "Error Indicator" ;
VAL_ 274 L_ATCU_RrBlwLvlSigVaildSta 0 "Invaild (Blower Level Info Not supported)" 1 "Vaild (Blower Level Info Supported) (Initial Value:0H)" ;
VAL_ 274 L_ATCU_RHPTCZone1TrgtDty 0 "0x0~0xC8:Duty" 200 "0x0~0xC8:Duty" 201 "RESERVED" 202 "RESERVED" 203 "RESERVED" 204 "RESERVED" 205 "RESERVED" 206 "RESERVED" 207 "RESERVED" 208 "RESERVED" 209 "RESERVED" 210 "RESERVED" 211 "RESERVED" 212 "RESERVED" 213 "RESERVED" 214 "RESERVED" 215 "RESERVED" 216 "RESERVED" 217 "RESERVED" 218 "RESERVED" 219 "RESERVED" 220 "RESERVED" 221 "RESERVED" 222 "RESERVED" 223 "RESERVED" 224 "RESERVED" 225 "RESERVED" 226 "RESERVED" 227 "RESERVED" 228 "RESERVED" 229 "RESERVED" 230 "RESERVED" 231 "RESERVED" 232 "RESERVED" 233 "RESERVED" 234 "RESERVED" 235 "RESERVED" 236 "RESERVED" 237 "RESERVED" 238 "RESERVED" 239 "RESERVED" 240 "RESERVED" 241 "RESERVED" 242 "RESERVED" 243 "RESERVED" 244 "RESERVED" 245 "RESERVED" 246 "RESERVED" 247 "RESERVED" 248 "RESERVED" 249 "RESERVED" 250 "RESERVED" 251 "RESERVED" 252 "RESERVED" 253 "RESERVED" 254 "RESERVED" 255 "ERROR" ;
VAL_ 274 L_ATCU_RrBlwFltSta 0 "Normal" 1 "Blower Fault" ;
VAL_ 275 L_ATCU_PCMActTgtPos 0 "OFF" 1 "Cartridge#1" 2 "Cartridge#2" 3 "~0x6:RESERVED" 7 "Cartridge Off Position" ;
VAL_ 275 L_ATCU_VehPowerIGN2 0 "Off" 1 "On" ;
VAL_ 275 L_ATCU_VehPowerISGB 0 "Off" 1 "On" ;
VAL_ 275 L_ATCU_CurrentDy 0 "Not used" 1 "1~31 day" 2 "1~31 day" 3 "1~31 day" 4 "1~31 day" 5 "1~31 day" 6 "1~31 day" 7 "1~31 day" 8 "1~31 day" 9 "1~31 day" 10 "1~31 day" 11 "1~31 day" 12 "1~31 day" 13 "1~31 day" 14 "1~31 day" 15 "1~31 day" 16 "1~31 day" 17 "1~31 day" 18 "1~31 day" 19 "1~31 day" 20 "1~31 day" 21 "1~31 day" 22 "1~31 day" 23 "1~31 day" 24 "1~31 day" 25 "1~31 day" 26 "1~31 day" 27 "1~31 day" 28 "1~31 day" 29 "1~31 day" 30 "1~31 day" 31 "1~31 day" 32 "20~0xFE:RESERVED" 254 "20~0xFE:RESERVED" 255 "Invalid" ;
VAL_ 275 L_ATCU_CurrentMon 0 "Not used" 1 "1~12 month" 2 "1~12 month" 3 "1~12 month" 4 "1~12 month" 5 "1~12 month" 6 "1~12 month" 7 "1~12 month" 8 "1~12 month" 9 "1~12 month" 10 "1~12 month" 11 "1~12 month" 12 "1~12 month" 13 "RESERVED" 14 "RESERVED" 15 "Invalid" ;
VAL_ 275 L_ATCU_CurrentYrPre 0 "19" 1 "20" 2 "21" 3 "invalid" ;
VAL_ 275 L_ATCU_CurrentYrPost 0 "00 year" 1 "01~99 year" 2 "01~99 year" 3 "01~99 year" 4 "01~99 year" 5 "01~99 year" 6 "01~99 year" 7 "01~99 year" 8 "01~99 year" 9 "01~99 year" 10 "01~99 year" 11 "01~99 year" 12 "01~99 year" 13 "01~99 year" 14 "01~99 year" 15 "01~99 year" 16 "01~99 year" 17 "01~99 year" 18 "01~99 year" 19 "01~99 year" 20 "01~99 year" 21 "01~99 year" 22 "01~99 year" 23 "01~99 year" 24 "01~99 year" 25 "01~99 year" 26 "01~99 year" 27 "01~99 year" 28 "01~99 year" 29 "01~99 year" 30 "01~99 year" 31 "01~99 year" 32 "01~99 year" 33 "01~99 year" 34 "01~99 year" 35 "01~99 year" 36 "01~99 year" 37 "01~99 year" 38 "01~99 year" 39 "01~99 year" 40 "01~99 year" 41 "01~99 year" 42 "01~99 year" 43 "01~99 year" 44 "01~99 year" 45 "01~99 year" 46 "01~99 year" 47 "01~99 year" 48 "01~99 year" 49 "01~99 year" 50 "01~99 year" 51 "01~99 year" 52 "01~99 year" 53 "01~99 year" 54 "01~99 year" 55 "01~99 year" 56 "01~99 year" 57 "01~99 year" 58 "01~99 year" 59 "01~99 year" 60 "01~99 year" 61 "01~99 year" 62 "01~99 year" 63 "01~99 year" 64 "01~99 year" 65 "01~99 year" 66 "01~99 year" 67 "01~99 year" 68 "01~99 year" 69 "01~99 year" 70 "01~99 year" 71 "01~99 year" 72 "01~99 year" 73 "01~99 year" 74 "01~99 year" 75 "01~99 year" 76 "01~99 year" 77 "01~99 year" 78 "01~99 year" 79 "01~99 year" 80 "01~99 year" 81 "01~99 year" 82 "01~99 year" 83 "01~99 year" 84 "01~99 year" 85 "01~99 year" 86 "01~99 year" 87 "01~99 year" 88 "01~99 year" 89 "01~99 year" 90 "01~99 year" 91 "01~99 year" 92 "01~99 year" 93 "01~99 year" 94 "01~99 year" 95 "01~99 year" 96 "01~99 year" 97 "01~99 year" 98 "01~99 year" 99 "01~99 year" 100 "64~0xFE:RESERVED" 254 "64~0xFE:RESERVED" 255 "Invalid" ;
VAL_ 275 L_ATCU_BlwrTgtOnOff 0 "Default" 1 "Off" 2 "On" 3 "Reserved" ;
VAL_ 275 L_ATCU_VehPowerBatt 0 "Off" 1 "On" ;
VAL_ 275 L_ATCU_VehPowerIGN1_3 0 "Off" 1 "On" ;
VAL_ 276 L_ATCU_Volatilization_gmin 0 "Invalid" ;
VAL_ 276 L_ATCU_Frag1Amount_g 0 "0x00~0xFE:0.0~25.4" 254 "0x00~0xFE:0.0~25.4" 255 "Error Indicator" ;
VAL_ 276 L_ATCU_Frag2Amount_g 0 "0x00~0xFE:0.0~25.4" 254 "0x00~0xFE:0.0~25.4" 255 "Error Indicator" ;
VAL_ 276 L_ATCU_Cart1ExpDate_year 0 "Error Indicator" 1 "1~3Year" 2 "1~3Year" 3 "1~3Year" 4 "Reserved" 5 "Reserved" 6 "Reserved" 7 "Reserved" 8 "Reserved" 9 "Reserved" 10 "Reserved" 11 "Reserved" 12 "Reserved" 13 "Reserved" 14 "Reserved" 15 "Reserved" ;
VAL_ 276 L_ATCU_Cart2ExpDate_year 0 "Error Indicator" 1 "1~3Year" 2 "1~3Year" 3 "1~3Year" 4 "Reserved" 5 "Reserved" 6 "Reserved" 7 "Reserved" 8 "Reserved" 9 "Reserved" 10 "Reserved" 11 "Reserved" 12 "Reserved" 13 "Reserved" 14 "Reserved" 15 "Reserved" ;
VAL_ 277 L_ATCU_FHPTC2ndDrTrgtDty 0 "0x0~0xC8:Duty" 200 "0x0~0xC8:Duty" 201 "RESERVED" 202 "RESERVED" 203 "RESERVED" 204 "RESERVED" 205 "RESERVED" 206 "RESERVED" 207 "RESERVED" 208 "RESERVED" 209 "RESERVED" 210 "RESERVED" 211 "RESERVED" 212 "RESERVED" 213 "RESERVED" 214 "RESERVED" 215 "RESERVED" 216 "RESERVED" 217 "RESERVED" 218 "RESERVED" 219 "RESERVED" 220 "RESERVED" 221 "RESERVED" 222 "RESERVED" 223 "RESERVED" 224 "RESERVED" 225 "RESERVED" 226 "RESERVED" 227 "RESERVED" 228 "RESERVED" 229 "RESERVED" 230 "RESERVED" 231 "RESERVED" 232 "RESERVED" 233 "RESERVED" 234 "RESERVED" 235 "RESERVED" 236 "RESERVED" 237 "RESERVED" 238 "RESERVED" 239 "RESERVED" 240 "RESERVED" 241 "RESERVED" 242 "RESERVED" 243 "RESERVED" 244 "RESERVED" 245 "RESERVED" 246 "RESERVED" 247 "RESERVED" 248 "RESERVED" 249 "RESERVED" 250 "RESERVED" 251 "RESERVED" 252 "RESERVED" 253 "RESERVED" 254 "RESERVED" 255 "ERROR" ;
VAL_ 277 L_ATCU_FltMsgTmOutFHPTC5 0 "Normal" 1 "Message Timeout" ;
VAL_ 277 L_ATCU_FltMsgTmOutFHPTC6 0 "Normal" 1 "Message Timeout" ;
VAL_ 277 L_ATCU_FltMsgTmOutFHPTC7 0 "Normal" 1 "Message Timeout" ;
VAL_ 277 L_ATCU_FltMsgTmOutFHPTC8 0 "Normal" 1 "Message Timeout" ;
VAL_ 277 L_ATCU_2ndDrBlwLvl 0 "OFF" 1 "0 level" 2 "1 level" 3 "2 level" 4 "3 level" 5 "4 level" 6 "5 level" 7 "6 level" 8 "7 evel" 9 "8 level" 10 "RESERVED" 11 "RESERVED" 12 "RESERVED" 13 "RESERVED" 14 "RESERVED" 15 "Error Indicator" ;
VAL_ 277 L_ATCU_2ndPsBlwLvl 0 "OFF" 1 "0 level" 2 "1 level" 3 "2 level" 4 "3 level" 5 "4 level" 6 "5 level" 7 "6 level" 8 "7 evel" 9 "8 level" 10 "RESERVED" 11 "RESERVED" 12 "RESERVED" 13 "RESERVED" 14 "RESERVED" 15 "Error Indicator" ;
VAL_ 277 L_ATCU_2ndBlwLvlSigVaildSta 0 "Invaild (Blower Level Info Not supported)" 1 "Vaild (Blower Level Info Supported) (Initial Value:0H)" ;
VAL_ 277 L_ATCU_2ndBlwFltSta 0 "Normal" 1 "Blower Fault" ;
VAL_ 277 L_ATCU_FHPTC2ndPsTrgtDty 0 "0x0~0xC8:Duty" 200 "0x0~0xC8:Duty" 201 "RESERVED" 202 "RESERVED" 203 "RESERVED" 204 "RESERVED" 205 "RESERVED" 206 "RESERVED" 207 "RESERVED" 208 "RESERVED" 209 "RESERVED" 210 "RESERVED" 211 "RESERVED" 212 "RESERVED" 213 "RESERVED" 214 "RESERVED" 215 "RESERVED" 216 "RESERVED" 217 "RESERVED" 218 "RESERVED" 219 "RESERVED" 220 "RESERVED" 221 "RESERVED" 222 "RESERVED" 223 "RESERVED" 224 "RESERVED" 225 "RESERVED" 226 "RESERVED" 227 "RESERVED" 228 "RESERVED" 229 "RESERVED" 230 "RESERVED" 231 "RESERVED" 232 "RESERVED" 233 "RESERVED" 234 "RESERVED" 235 "RESERVED" 236 "RESERVED" 237 "RESERVED" 238 "RESERVED" 239 "RESERVED" 240 "RESERVED" 241 "RESERVED" 242 "RESERVED" 243 "RESERVED" 244 "RESERVED" 245 "RESERVED" 246 "RESERVED" 247 "RESERVED" 248 "RESERVED" 249 "RESERVED" 250 "RESERVED" 251 "RESERVED" 252 "RESERVED" 253 "RESERVED" 254 "RESERVED" 255 "ERROR" ;
VAL_ 278 L_ATCU_HU_MasterProfile_ResetIndex 0 "Default" 1 "Profile 1~Profile 9" 2 "Profile 1~Profile 9" 3 "Profile 1~Profile 9" 4 "Profile 1~Profile 9" 5 "Profile 1~Profile 9" 6 "Profile 1~Profile 9" 7 "Profile 1~Profile 9" 8 "Profile 1~Profile 9" 9 "Profile 1~Profile 9" 10 "RESERVED" 11 "RESERVED" 12 "RESERVED" 13 "RESERVED" 14 "RESERVED" 15 "Invalid" ;
VAL_ 278 L_ATCU_HU_OptionInfo 0 "0x0000~0x0FFF:Bit allocation" 4095 "0x0000~0x0FFF:Bit allocation" 4096 "1000~0x7FFF:RESERVED" 32767 "1000~0x7FFF:RESERVED" 32768 "Invalid" 32769 "8001~0xFFFF:Not used" 65535 "8001~0xFFFF:Not used" ;
VAL_ 281 L_ATCU_HU_FrDrEVntSidePt_X 0 "Default" 1 "001~0x780:PHY=HEX*1 + 0" 1920 "001~0x780:PHY=HEX*1 + 0" 1921 "781~0x7FE:RESERVED" 2046 "781~0x7FE:RESERVED" 2047 "Invalid" ;
VAL_ 281 L_ATCU_HU_FrDrEVntSidePt_Y 0 "Default" 1 "001~0x780:PHY=HEX*1 + 0" 1920 "001~0x780:PHY=HEX*1 + 0" 1921 "781~0x7FE:RESERVED" 2046 "781~0x7FE:RESERVED" 2047 "Invalid" ;
VAL_ 281 L_ATCU_HU_FrDrEVntCtrPt_X 0 "Default" 1 "001~0x780:PHY=HEX*1 + 0" 1920 "001~0x780:PHY=HEX*1 + 0" 1921 "781~0x7FE:RESERVED" 2046 "781~0x7FE:RESERVED" 2047 "Invalid" ;
VAL_ 281 L_ATCU_HU_FrDrEVntCtrPt_Y 0 "Default" 1 "001~0x780:PHY=HEX*1 + 0" 1920 "001~0x780:PHY=HEX*1 + 0" 1921 "781~0x7FE:RESERVED" 2046 "781~0x7FE:RESERVED" 2047 "Invalid" ;
VAL_ 305 L_ATCU_HU_FrPsEVntSidePt_X 0 "Default" 1 "001~0x780:PHY=HEX*1 + 0" 1920 "001~0x780:PHY=HEX*1 + 0" 1921 "781~0x7FE:RESERVED" 2046 "781~0x7FE:RESERVED" 2047 "Invalid" ;
VAL_ 305 L_ATCU_HU_FrPsEVntSidePt_Y 0 "Default" 1 "001~0x780:PHY=HEX*1 + 0" 1920 "001~0x780:PHY=HEX*1 + 0" 1921 "781~0x7FE:RESERVED" 2046 "781~0x7FE:RESERVED" 2047 "Invalid" ;
VAL_ 305 L_ATCU_HU_FrPsEVntCtrPt_X 0 "Default" 1 "001~0x780:PHY=HEX*1 + 0" 1920 "001~0x780:PHY=HEX*1 + 0" 1921 "781~0x7FE:RESERVED" 2046 "781~0x7FE:RESERVED" 2047 "Invalid" ;
VAL_ 305 L_ATCU_HU_FrPsEVntCtrPt_Y 0 "Default" 1 "001~0x780:PHY=HEX*1 + 0" 1920 "001~0x780:PHY=HEX*1 + 0" 1921 "781~0x7FE:RESERVED" 2046 "781~0x7FE:RESERVED" 2047 "Invalid" ;
VAL_ 306 L_ATCU_HU_RrDrEVntConsPt_X 0 "Default" 1 "001~0x780:PHY=HEX*1 + 0" 1920 "001~0x780:PHY=HEX*1 + 0" 1921 "781~0x7FE:RESERVED" 2046 "781~0x7FE:RESERVED" 2047 "Invalid" ;
VAL_ 306 L_ATCU_HU_RrDrEVntConsPt_Y 0 "Default" 1 "001~0x780:PHY=HEX*1 + 0" 1920 "001~0x780:PHY=HEX*1 + 0" 1921 "781~0x7FE:RESERVED" 2046 "781~0x7FE:RESERVED" 2047 "Invalid" ;
VAL_ 306 L_ATCU_HU_RrPsEVntConsPt_X 0 "Default" 1 "001~0x780:PHY=HEX*1 + 0" 1920 "001~0x780:PHY=HEX*1 + 0" 1921 "781~0x7FE:RESERVED" 2046 "781~0x7FE:RESERVED" 2047 "Invalid" ;
VAL_ 306 L_ATCU_HU_RrPsEVntConsPt_Y 0 "Default" 1 "001~0x780:PHY=HEX*1 + 0" 1920 "001~0x780:PHY=HEX*1 + 0" 1921 "781~0x7FE:RESERVED" 2046 "781~0x7FE:RESERVED" 2047 "Invalid" ;
VAL_ 306 L_ATCU_HU_RrDrEVntConsOpnCls 0 "Default" 1 "OPEN" 2 "CLOSE" 3 "Invalid" ;
VAL_ 306 L_ATCU_HU_RrPsEVntConsOpnCls 0 "Default" 1 "OPEN" 2 "CLOSE" 3 "Invalid" ;
VAL_ 306 L_ATCU_HU_RrDrEVntModeSet 0 "Default" 1 "FOCUS Mode" 2 "SPREAD Mode" 3 "CYCLE Mode" 4 "FREE Mode" 5 "OFF" 6 "RESERVED" 7 "RESERVED" 8 "RESERVED" 9 "RESERVED" 10 "RESERVED" 11 "RESERVED" 12 "RESERVED" 13 "RESERVED" 14 "RESERVED" 15 "Invalid" ;
VAL_ 306 L_ATCU_HU_RrPsEVntModeSet 0 "Default" 1 "FOCUS Mode" 2 "SPREAD Mode" 3 "CYCLE Mode" 4 "FREE Mode" 5 "OFF" 6 "RESERVED" 7 "RESERVED" 8 "RESERVED" 9 "RESERVED" 10 "RESERVED" 11 "RESERVED" 12 "RESERVED" 13 "RESERVED" 14 "RESERVED" 15 "Invalid" ;
VAL_ 304 L_ATCU_CTS_RrDrEVntConsBdryUp_X 0 "Default" 1 "01~0xC0:PHY=HEX*10 + 0" 192 "01~0xC0:PHY=HEX*10 + 0" 193 "RESERVED" 194 "RESERVED" 195 "RESERVED" 196 "RESERVED" 197 "RESERVED" 198 "RESERVED" 199 "RESERVED" 200 "RESERVED" 201 "RESERVED" 202 "RESERVED" 203 "RESERVED" 204 "RESERVED" 205 "RESERVED" 206 "RESERVED" 207 "RESERVED" 208 "RESERVED" 209 "RESERVED" 210 "RESERVED" 211 "RESERVED" 212 "RESERVED" 213 "RESERVED" 214 "RESERVED" 215 "RESERVED" 216 "RESERVED" 217 "RESERVED" 218 "RESERVED" 219 "RESERVED" 220 "RESERVED" 221 "RESERVED" 222 "RESERVED" 223 "RESERVED" 224 "RESERVED" 225 "RESERVED" 226 "RESERVED" 227 "RESERVED" 228 "RESERVED" 229 "RESERVED" 230 "RESERVED" 231 "RESERVED" 232 "RESERVED" 233 "RESERVED" 234 "RESERVED" 235 "RESERVED" 236 "RESERVED" 237 "RESERVED" 238 "RESERVED" 239 "RESERVED" 240 "RESERVED" 241 "RESERVED" 242 "RESERVED" 243 "RESERVED" 244 "RESERVED" 245 "RESERVED" 246 "RESERVED" 247 "RESERVED" 248 "RESERVED" 249 "RESERVED" 250 "RESERVED" 251 "RESERVED" 252 "RESERVED" 253 "RESERVED" 254 "RESERVED" 255 "Invalid" ;
VAL_ 304 L_ATCU_CTS_RrDrEVntConsBdryLo_X 0 "Default" 1 "01~0xC0:PHY=HEX*10 + 0" 192 "01~0xC0:PHY=HEX*10 + 0" 193 "RESERVED" 194 "RESERVED" 195 "RESERVED" 196 "RESERVED" 197 "RESERVED" 198 "RESERVED" 199 "RESERVED" 200 "RESERVED" 201 "RESERVED" 202 "RESERVED" 203 "RESERVED" 204 "RESERVED" 205 "RESERVED" 206 "RESERVED" 207 "RESERVED" 208 "RESERVED" 209 "RESERVED" 210 "RESERVED" 211 "RESERVED" 212 "RESERVED" 213 "RESERVED" 214 "RESERVED" 215 "RESERVED" 216 "RESERVED" 217 "RESERVED" 218 "RESERVED" 219 "RESERVED" 220 "RESERVED" 221 "RESERVED" 222 "RESERVED" 223 "RESERVED" 224 "RESERVED" 225 "RESERVED" 226 "RESERVED" 227 "RESERVED" 228 "RESERVED" 229 "RESERVED" 230 "RESERVED" 231 "RESERVED" 232 "RESERVED" 233 "RESERVED" 234 "RESERVED" 235 "RESERVED" 236 "RESERVED" 237 "RESERVED" 238 "RESERVED" 239 "RESERVED" 240 "RESERVED" 241 "RESERVED" 242 "RESERVED" 243 "RESERVED" 244 "RESERVED" 245 "RESERVED" 246 "RESERVED" 247 "RESERVED" 248 "RESERVED" 249 "RESERVED" 250 "RESERVED" 251 "RESERVED" 252 "RESERVED" 253 "RESERVED" 254 "RESERVED" 255 "Invalid" ;
VAL_ 304 L_ATCU_CTS_RrDrEVntConsBdryLo_Y 0 "Default" 1 "01~0xC0:PHY=HEX*10 + 0" 192 "01~0xC0:PHY=HEX*10 + 0" 193 "RESERVED" 194 "RESERVED" 195 "RESERVED" 196 "RESERVED" 197 "RESERVED" 198 "RESERVED" 199 "RESERVED" 200 "RESERVED" 201 "RESERVED" 202 "RESERVED" 203 "RESERVED" 204 "RESERVED" 205 "RESERVED" 206 "RESERVED" 207 "RESERVED" 208 "RESERVED" 209 "RESERVED" 210 "RESERVED" 211 "RESERVED" 212 "RESERVED" 213 "RESERVED" 214 "RESERVED" 215 "RESERVED" 216 "RESERVED" 217 "RESERVED" 218 "RESERVED" 219 "RESERVED" 220 "RESERVED" 221 "RESERVED" 222 "RESERVED" 223 "RESERVED" 224 "RESERVED" 225 "RESERVED" 226 "RESERVED" 227 "RESERVED" 228 "RESERVED" 229 "RESERVED" 230 "RESERVED" 231 "RESERVED" 232 "RESERVED" 233 "RESERVED" 234 "RESERVED" 235 "RESERVED" 236 "RESERVED" 237 "RESERVED" 238 "RESERVED" 239 "RESERVED" 240 "RESERVED" 241 "RESERVED" 242 "RESERVED" 243 "RESERVED" 244 "RESERVED" 245 "RESERVED" 246 "RESERVED" 247 "RESERVED" 248 "RESERVED" 249 "RESERVED" 250 "RESERVED" 251 "RESERVED" 252 "RESERVED" 253 "RESERVED" 254 "RESERVED" 255 "Invalid" ;
VAL_ 304 L_ATCU_CTS_RrPsEVntConsBdryUp_X 0 "Default" 1 "01~0xC0:PHY=HEX*10 + 0" 192 "01~0xC0:PHY=HEX*10 + 0" 193 "RESERVED" 194 "RESERVED" 195 "RESERVED" 196 "RESERVED" 197 "RESERVED" 198 "RESERVED" 199 "RESERVED" 200 "RESERVED" 201 "RESERVED" 202 "RESERVED" 203 "RESERVED" 204 "RESERVED" 205 "RESERVED" 206 "RESERVED" 207 "RESERVED" 208 "RESERVED" 209 "RESERVED" 210 "RESERVED" 211 "RESERVED" 212 "RESERVED" 213 "RESERVED" 214 "RESERVED" 215 "RESERVED" 216 "RESERVED" 217 "RESERVED" 218 "RESERVED" 219 "RESERVED" 220 "RESERVED" 221 "RESERVED" 222 "RESERVED" 223 "RESERVED" 224 "RESERVED" 225 "RESERVED" 226 "RESERVED" 227 "RESERVED" 228 "RESERVED" 229 "RESERVED" 230 "RESERVED" 231 "RESERVED" 232 "RESERVED" 233 "RESERVED" 234 "RESERVED" 235 "RESERVED" 236 "RESERVED" 237 "RESERVED" 238 "RESERVED" 239 "RESERVED" 240 "RESERVED" 241 "RESERVED" 242 "RESERVED" 243 "RESERVED" 244 "RESERVED" 245 "RESERVED" 246 "RESERVED" 247 "RESERVED" 248 "RESERVED" 249 "RESERVED" 250 "RESERVED" 251 "RESERVED" 252 "RESERVED" 253 "RESERVED" 254 "RESERVED" 255 "Invalid" ;
VAL_ 304 L_ATCU_CTS_RrPsEVntConsBdryUp_Y 0 "Default" 1 "01~0xC0:PHY=HEX*10 + 0" 192 "01~0xC0:PHY=HEX*10 + 0" 193 "RESERVED" 194 "RESERVED" 195 "RESERVED" 196 "RESERVED" 197 "RESERVED" 198 "RESERVED" 199 "RESERVED" 200 "RESERVED" 201 "RESERVED" 202 "RESERVED" 203 "RESERVED" 204 "RESERVED" 205 "RESERVED" 206 "RESERVED" 207 "RESERVED" 208 "RESERVED" 209 "RESERVED" 210 "RESERVED" 211 "RESERVED" 212 "RESERVED" 213 "RESERVED" 214 "RESERVED" 215 "RESERVED" 216 "RESERVED" 217 "RESERVED" 218 "RESERVED" 219 "RESERVED" 220 "RESERVED" 221 "RESERVED" 222 "RESERVED" 223 "RESERVED" 224 "RESERVED" 225 "RESERVED" 226 "RESERVED" 227 "RESERVED" 228 "RESERVED" 229 "RESERVED" 230 "RESERVED" 231 "RESERVED" 232 "RESERVED" 233 "RESERVED" 234 "RESERVED" 235 "RESERVED" 236 "RESERVED" 237 "RESERVED" 238 "RESERVED" 239 "RESERVED" 240 "RESERVED" 241 "RESERVED" 242 "RESERVED" 243 "RESERVED" 244 "RESERVED" 245 "RESERVED" 246 "RESERVED" 247 "RESERVED" 248 "RESERVED" 249 "RESERVED" 250 "RESERVED" 251 "RESERVED" 252 "RESERVED" 253 "RESERVED" 254 "RESERVED" 255 "Invalid" ;
VAL_ 304 L_ATCU_CTS_RrPsEVntConsBdryLo_X 0 "Default" 1 "01~0xC0:PHY=HEX*10 + 0" 192 "01~0xC0:PHY=HEX*10 + 0" 193 "RESERVED" 194 "RESERVED" 195 "RESERVED" 196 "RESERVED" 197 "RESERVED" 198 "RESERVED" 199 "RESERVED" 200 "RESERVED" 201 "RESERVED" 202 "RESERVED" 203 "RESERVED" 204 "RESERVED" 205 "RESERVED" 206 "RESERVED" 207 "RESERVED" 208 "RESERVED" 209 "RESERVED" 210 "RESERVED" 211 "RESERVED" 212 "RESERVED" 213 "RESERVED" 214 "RESERVED" 215 "RESERVED" 216 "RESERVED" 217 "RESERVED" 218 "RESERVED" 219 "RESERVED" 220 "RESERVED" 221 "RESERVED" 222 "RESERVED" 223 "RESERVED" 224 "RESERVED" 225 "RESERVED" 226 "RESERVED" 227 "RESERVED" 228 "RESERVED" 229 "RESERVED" 230 "RESERVED" 231 "RESERVED" 232 "RESERVED" 233 "RESERVED" 234 "RESERVED" 235 "RESERVED" 236 "RESERVED" 237 "RESERVED" 238 "RESERVED" 239 "RESERVED" 240 "RESERVED" 241 "RESERVED" 242 "RESERVED" 243 "RESERVED" 244 "RESERVED" 245 "RESERVED" 246 "RESERVED" 247 "RESERVED" 248 "RESERVED" 249 "RESERVED" 250 "RESERVED" 251 "RESERVED" 252 "RESERVED" 253 "RESERVED" 254 "RESERVED" 255 "Invalid" ;
VAL_ 304 L_ATCU_CTS_RrPsEVntConsBdryLo_Y 0 "Default" 1 "01~0xC0:PHY=HEX*10 + 0" 192 "01~0xC0:PHY=HEX*10 + 0" 193 "RESERVED" 194 "RESERVED" 195 "RESERVED" 196 "RESERVED" 197 "RESERVED" 198 "RESERVED" 199 "RESERVED" 200 "RESERVED" 201 "RESERVED" 202 "RESERVED" 203 "RESERVED" 204 "RESERVED" 205 "RESERVED" 206 "RESERVED" 207 "RESERVED" 208 "RESERVED" 209 "RESERVED" 210 "RESERVED" 211 "RESERVED" 212 "RESERVED" 213 "RESERVED" 214 "RESERVED" 215 "RESERVED" 216 "RESERVED" 217 "RESERVED" 218 "RESERVED" 219 "RESERVED" 220 "RESERVED" 221 "RESERVED" 222 "RESERVED" 223 "RESERVED" 224 "RESERVED" 225 "RESERVED" 226 "RESERVED" 227 "RESERVED" 228 "RESERVED" 229 "RESERVED" 230 "RESERVED" 231 "RESERVED" 232 "RESERVED" 233 "RESERVED" 234 "RESERVED" 235 "RESERVED" 236 "RESERVED" 237 "RESERVED" 238 "RESERVED" 239 "RESERVED" 240 "RESERVED" 241 "RESERVED" 242 "RESERVED" 243 "RESERVED" 244 "RESERVED" 245 "RESERVED" 246 "RESERVED" 247 "RESERVED" 248 "RESERVED" 249 "RESERVED" 250 "RESERVED" 251 "RESERVED" 252 "RESERVED" 253 "RESERVED" 254 "RESERVED" 255 "Invalid" ;
VAL_ 304 L_ATCU_CTS_RrDrEVntConsBdryUp_Y 0 "Default" 1 "01~0xC0:PHY=HEX*10 + 0" 192 "01~0xC0:PHY=HEX*10 + 0" 193 "RESERVED" 194 "RESERVED" 195 "RESERVED" 196 "RESERVED" 197 "RESERVED" 198 "RESERVED" 199 "RESERVED" 200 "RESERVED" 201 "RESERVED" 202 "RESERVED" 203 "RESERVED" 204 "RESERVED" 205 "RESERVED" 206 "RESERVED" 207 "RESERVED" 208 "RESERVED" 209 "RESERVED" 210 "RESERVED" 211 "RESERVED" 212 "RESERVED" 213 "RESERVED" 214 "RESERVED" 215 "RESERVED" 216 "RESERVED" 217 "RESERVED" 218 "RESERVED" 219 "RESERVED" 220 "RESERVED" 221 "RESERVED" 222 "RESERVED" 223 "RESERVED" 224 "RESERVED" 225 "RESERVED" 226 "RESERVED" 227 "RESERVED" 228 "RESERVED" 229 "RESERVED" 230 "RESERVED" 231 "RESERVED" 232 "RESERVED" 233 "RESERVED" 234 "RESERVED" 235 "RESERVED" 236 "RESERVED" 237 "RESERVED" 238 "RESERVED" 239 "RESERVED" 240 "RESERVED" 241 "RESERVED" 242 "RESERVED" 243 "RESERVED" 244 "RESERVED" 245 "RESERVED" 246 "RESERVED" 247 "RESERVED" 248 "RESERVED" 249 "RESERVED" 250 "RESERVED" 251 "RESERVED" 252 "RESERVED" 253 "RESERVED" 254 "RESERVED" 255 "Invalid" ;
VAL_ 801 MON_LibMngrDrvMod 0 "OFF" 1 "FLOOR" 2 "VENT" 3 "B_L (VENT_FLOOR)" 4 "DEF_EU" 5 "MIX (DEF_FLOOR)" 6 "DEF_VENT" 7 "ALL (DEF_VENT_FLOOR)" 8 "VENT_BLEED" 9 "FLOOR_100" 10 "WARM_FLOOR" 11 "COOL_MIX" 12 "DEF (MAX_DEF)" ;
VAL_ 801 MON_LibMngrAC 0 "OFF / 0x01:ON" ;
VAL_ 801 MON_LibMngrActvIncarMotPwr 0 "OFF" 1 "ON" ;
VAL_ 801 MON_LibMngrPDCWakeUpReq 0 "OFF" 1 "ON" ;
VAL_ 801 MON_LibMngrLVPTCRly1State 0 "OFF" 1 "ON" ;
VAL_ 801 MON_LibMngrLVPTCRly2State 0 "OFF" 1 "ON" ;
VAL_ 801 MON_LibMngrVRLedOpReq 0 "OFF" 1 "ON" ;
VAL_ 801 MON_LibMngrBlrVtg 0 "0x0~0x34BC:0~13.500" 13500 "0x0~0x34BC:0~13.500" 13501 "34BD~0xFFFE:RESERVED" 65534 "34BD~0xFFFE:RESERVED" 65535 "None" ;
VAL_ 801 MON_LibMngrAstMod 0 "OFF" 1 "FLOOR" 2 "VENT" 3 "B_L (VENT_FLOOR)" 4 "DEF_EU" 5 "MIX (DEF_FLOOR)" 6 "DEF_VENT" 7 "ALL (DEF_VENT_FLOOR)" 8 "VENT_BLEED" 9 "FLOOR_100" 10 "WARM_FLOOR" 11 "COOL_MIX" 12 "DEF (MAX_DEF)" ;
VAL_ 801 MON_LibMngrDrvTmpDr 0 "0x0~0x3E8:0~100" 1000 "0x0~0x3E8:0~100" 1001 "RESERVED" 1002 "RESERVED" 1003 "RESERVED" 1004 "RESERVED" 1005 "RESERVED" 1006 "RESERVED" 1007 "RESERVED" 1008 "RESERVED" 1009 "RESERVED" 1010 "RESERVED" 1011 "RESERVED" 1012 "RESERVED" 1013 "RESERVED" 1014 "RESERVED" 1015 "RESERVED" 1016 "RESERVED" 1017 "RESERVED" 1018 "RESERVED" 1019 "RESERVED" 1020 "RESERVED" 1021 "RESERVED" 1022 "RESERVED" 1023 "None" ;
VAL_ 801 MON_LibMngrAstTmpDr 0 "0x0~0x3E8:0~100" 1000 "0x0~0x3E8:0~100" 1001 "RESERVED" 1002 "RESERVED" 1003 "RESERVED" 1004 "RESERVED" 1005 "RESERVED" 1006 "RESERVED" 1007 "RESERVED" 1008 "RESERVED" 1009 "RESERVED" 1010 "RESERVED" 1011 "RESERVED" 1012 "RESERVED" 1013 "RESERVED" 1014 "RESERVED" 1015 "RESERVED" 1016 "RESERVED" 1017 "RESERVED" 1018 "RESERVED" 1019 "RESERVED" 1020 "RESERVED" 1021 "RESERVED" 1022 "RESERVED" 1023 "None" ;
VAL_ 801 MON_LibMngrIntake 0 "0x0~0x3E8:0~100" 1000 "0x0~0x3E8:0~100" 1001 "RESERVED" 1002 "RESERVED" 1003 "RESERVED" 1004 "RESERVED" 1005 "RESERVED" 1006 "RESERVED" 1007 "RESERVED" 1008 "RESERVED" 1009 "RESERVED" 1010 "RESERVED" 1011 "RESERVED" 1012 "RESERVED" 1013 "RESERVED" 1014 "RESERVED" 1015 "RESERVED" 1016 "RESERVED" 1017 "RESERVED" 1018 "RESERVED" 1019 "RESERVED" 1020 "RESERVED" 1021 "RESERVED" 1022 "RESERVED" 1023 "None" ;
VAL_ 802 MON_LibMngrDEFDr 0 "0x0~0x3E8:0~100" 1000 "0x0~0x3E8:0~100" 1001 "RESERVED" 1002 "RESERVED" 1003 "RESERVED" 1004 "RESERVED" 1005 "RESERVED" 1006 "RESERVED" 1007 "RESERVED" 1008 "RESERVED" 1009 "RESERVED" 1010 "RESERVED" 1011 "RESERVED" 1012 "RESERVED" 1013 "RESERVED" 1014 "RESERVED" 1015 "RESERVED" 1016 "RESERVED" 1017 "RESERVED" 1018 "RESERVED" 1019 "RESERVED" 1020 "RESERVED" 1021 "RESERVED" 1022 "RESERVED" 1023 "None" ;
VAL_ 802 MON_LibMngr2LHMod 0 "OFF" 1 "FLOOR" 2 "VENT" 3 "B_L (VENT_FLOOR)" 4 "DEF_EU" 5 "MIX (DEF_FLOOR)" 6 "DEF_VENT" 7 "ALL (DEF_VENT_FLOOR)" 8 "VENT_BLEED" 9 "FLOOR_100" 10 "WARM_FLOOR" 11 "COOL_MIX" 12 "DEF (MAX_DEF)" ;
VAL_ 802 MON_LibMngrPwrSleep 0 "OFF" 1 "ON" ;
VAL_ 802 MON_LibMngr2LHBlrVtg 0 "0x0~0x34BC:0~13.500" 13500 "0x0~0x34BC:0~13.500" 13501 "34BD~0xFFFE:RESERVED" 65534 "34BD~0xFFFE:RESERVED" 65535 "None" ;
VAL_ 802 MON_LibMngr2LHTmpDr 0 "0x0~0x3E8:0~100" 1000 "0x0~0x3E8:0~100" 1001 "RESERVED" 1002 "RESERVED" 1003 "RESERVED" 1004 "RESERVED" 1005 "RESERVED" 1006 "RESERVED" 1007 "RESERVED" 1008 "RESERVED" 1009 "RESERVED" 1010 "RESERVED" 1011 "RESERVED" 1012 "RESERVED" 1013 "RESERVED" 1014 "RESERVED" 1015 "RESERVED" 1016 "RESERVED" 1017 "RESERVED" 1018 "RESERVED" 1019 "RESERVED" 1020 "RESERVED" 1021 "RESERVED" 1022 "RESERVED" 1023 "None" ;
VAL_ 802 MON_LibMngr2LHBlrStep 0 "None" 1 "Step1" 2 "Step2" 3 "Step3" 4 "Step4" 5 "Step5" 6 "Step6" 7 "Step7" 8 "Step8" 9 "OFF" 10 "NUM" ;
VAL_ 803 MON_LibFuncSysKeyState 0 "SystemDisable (*)" 1 "SystemOff" 2 "SystemOn" 3 "ST" 4 "SystemLimitedEnable" 5 "SystemEnable" ;
VAL_ 803 MON_LibFuncSwBlrStatus 0 "AUTO" 1 "MANUAL" ;
VAL_ 803 MON_LibFuncSwIntakeStatus 0 "AUTO" 1 "MANUAL" ;
VAL_ 803 MON_LibFuncSwACStatus 0 "AUTO" 1 "MANUAL" ;
VAL_ 803 MON_LibFuncAutoSw 0 "OFF" 1 "ON" ;
VAL_ 803 MON_LibFuncSwIntakeState 0 "0x0~0x3E8:0~100" 1000 "0x0~0x3E8:0~100" 1001 "RESERVED" 1002 "RESERVED" 1003 "RESERVED" 1004 "RESERVED" 1005 "RESERVED" 1006 "RESERVED" 1007 "RESERVED" 1008 "RESERVED" 1009 "RESERVED" 1010 "RESERVED" 1011 "RESERVED" 1012 "RESERVED" 1013 "RESERVED" 1014 "RESERVED" 1015 "RESERVED" 1016 "RESERVED" 1017 "RESERVED" 1018 "RESERVED" 1019 "RESERVED" 1020 "RESERVED" 1021 "RESERVED" 1022 "RESERVED" 1023 "Default" ;
VAL_ 803 MON_LibFuncIntakeRECSw 0 "OFF" 1 "ON" ;
VAL_ 803 MON_LibFuncSwDrvTempStepState 0 "OFF" 1 "MAX_COOL" 2 "Step" 3 "Step" 4 "Step" 5 "Step" 6 "Step" 7 "Step" 8 "Step" 9 "Step" 10 "Step" 11 "Step" 12 "Step" 13 "Step" 14 "Step" 15 "Step" 16 "Step" 17 "Step" 18 "Step" 19 "Step" 20 "Step" 21 "Step" 22 "Step" 23 "MAX_HOT" ;
VAL_ 803 MON_LibFuncSwModState 0 "OFF (*)" 1 "FLOOR" 2 "VENT" 3 "B_L (VENT_FLOOR)" 4 "DEF_EU" 5 "MIX (DEF_FLOOR)" 6 "DEF_VENT" 7 "ALL (DEF_VENT_FLOOR)" 12 "DEF (MAX_DEF)" ;
VAL_ 803 MON_LibFunc2LHSwTempStepState 0 "OFF" 1 "MAX_COOL" 2 "Step" 3 "Step" 4 "Step" 5 "Step" 6 "Step" 7 "Step" 8 "Step" 9 "Step" 10 "Step" 11 "Step" 12 "Step" 13 "Step" 14 "Step" 15 "Step" 16 "Step" 17 "Step" 18 "Step" 19 "Step" 20 "Step" 21 "Step" 22 "Step" 23 "MAX_HOT" ;
VAL_ 803 MON_LibFuncIntakeFRESw 0 "OFF" 1 "ON" ;
VAL_ 803 MON_LibFunc2LHSwModStatus 0 "AUTO" 1 "MANUAL" ;
VAL_ 803 MON_LibFunc2LHBlowerProfileProhibit 0 "OFF" 1 "ON" ;
VAL_ 803 MON_LibFunc2LHSwModState 0 "OFF (*)" 1 "FLOOR" 2 "VENT" 3 "B_L (VENT_FLOOR)" 4 "DEF_EU" 5 "MIX (DEF_FLOOR)" 6 "DEF_VENT" 7 "ALL (DEF_VENT_FLOOR)" 12 "DEF (MAX_DEF)" ;
VAL_ 803 MON_LibFunc2LHBlrStepState 0 "None" 1 "Step1" 2 "Step2" 3 "Step3" 4 "Step4" 5 "Step5" 6 "Step6" 7 "Step7" 8 "Step8" 9 "OFF" 10 "NUM" ;
VAL_ 803 MON_LibFunc2LHAutoSw 0 "OFF" 1 "ON" ;
VAL_ 803 MON_LibFunc2LHSwBlrStatus 0 "AUTO" 1 "MANUAL" ;
VAL_ 803 MON_LibFuncSwModStatus 0 "AUTO" 1 "MANUAL" ;
VAL_ 803 MON_LibFuncBlrStepState 0 "None" 1 "Step1" 2 "Step2" 3 "Step3" 4 "Step4" 5 "Step5" 6 "Step6" 7 "Step7" 8 "Step8" 9 "OFF" 10 "NUM" ;
VAL_ 804 MON_LibFuncHotStart2LHBlrPrfleChgReq 0 "OFF" 1 "ON" ;
VAL_ 804 MON_LibFuncAmbFilterResetOpState 0 "Default" 1 "Timer Request" 2 "Operation Request" ;
VAL_ 804 MON_LibFuncDEFACState 0 "OFF" 1 "ON" ;
VAL_ 804 MON_LibFuncETCIntlckHVActOffReq 0 "OFF" 1 "ON" ;
VAL_ 804 MON_LibFuncHVACIntlckHVActOffReq 0 "OFF" 1 "ON" ;
VAL_ 804 MON_LibFuncMainRlyProtectOpState 0 "OFF" 1 "ON" ;
VAL_ 804 MON_LibFuncMIXACState 0 "OFF" 1 "ON" ;
VAL_ 804 MON_LibFuncRmtFATCRmtState 0 "OFF" 1 "ON" ;
VAL_ 804 MON_LibFuncUSM_ADSState 0 "USM Not Apply" 1 "USM OFF" 2 "USM ON" 3 "USM Invalid" ;
VAL_ 804 MON_LibFuncBlowerProfileProhibit 0 "OFF" 1 "ON" ;
VAL_ 806 MON_LibFuncAfterBlowStandbyTime 0 "0x0~0xFFFFFFFA:0~4294967290" 2147483647 "0x0~0xFFFFFFFA:0~4294967290" ;
VAL_ 806 MON_LibFuncSchdldVentStandbyTime 0 "0x0~0x15180:0~86400" 86400 "0x0~0x15180:0~86400" ;
VAL_ 807 MON_LibFuncHICCSWVer 0 "0x0~0xFFFFFFFA:0~4294967290" 2147483647 "0x0~0xFFFFFFFA:0~4294967290" ;
VAL_ 817 L_ATCU_Sys_AutoDrvModState 0 "Off" 1 "Floor" 2 "Vent" 3 "BL" 4 "Def_EU" 5 "Mix" 6 "Def_Vent" 7 "All" 8 "Vent_Bleed" 9 "Floor_100" 10 "Warm_Floor" 11 "Cool_Mix" 12 "Def" 13 "RESERVED" 14 "RESERVED" 15 "None" ;
VAL_ 817 L_ATCU_Sys_AutoIntakeState 0 "FRE(0.0%)" 1 "1~0x3E7:Intake(0.1~99.9%)" 999 "1~0x3E7:Intake(0.1~99.9%)" 1000 "REC(100.0%)" 1001 "RESERVED" 1002 "RESERVED" 1003 "RESERVED" 1004 "RESERVED" 1005 "RESERVED" 1006 "RESERVED" 1007 "RESERVED" 1008 "RESERVED" 1009 "RESERVED" 1010 "RESERVED" 1011 "RESERVED" 1012 "RESERVED" 1013 "RESERVED" 1014 "RESERVED" 1015 "RESERVED" 1016 "RESERVED" 1017 "RESERVED" 1018 "RESERVED" 1019 "RESERVED" 1020 "RESERVED" 1021 "RESERVED" 1022 "RESERVED" 1023 "None" ;
VAL_ 817 L_ATCU_Sys_AutoACState 0 "Off" 1 "On" 2 "RESERVED" 3 "RESERVED" ;
VAL_ 817 L_ATCU_Sys_AutoEvapTargetTemp 0 "0x0~0x258:-20.0~40.0¡É" 600 "0x0~0x258:-20.0~40.0¡É" 601 "259~0xFFFE:RESERVED" 65534 "259~0xFFFE:RESERVED" 65535 "Invalid" ;
VAL_ 817 L_ATCU_Sys_AutoBlrVtgVal 0 "0x0~0x34BC:0~13.500V" 13500 "0x0~0x34BC:0~13.500V" 13501 "34BD~0xFFFE:RESERVED" 65534 "34BD~0xFFFE:RESERVED" 65535 "None" ;
VAL_ 818 L_ATCU_Sys_AutoAstTargetTempVal 0 "0x0~0x3EB:-40.0~60.0¡É" 1003 "0x0~0x3EB:-40.0~60.0¡É" 1004 "3EC~0xFFFE:RESERVED" 65534 "3EC~0xFFFE:RESERVED" 65535 "Invalid" ;
VAL_ 818 L_ATCU_Sys_AutoAstTempDrState 0 "0x0~0x3E8:0~100.0%" 1000 "0x0~0x3E8:0~100.0%" 1001 "RESERVED" 1002 "RESERVED" 1003 "RESERVED" 1004 "RESERVED" 1005 "RESERVED" 1006 "RESERVED" 1007 "RESERVED" 1008 "RESERVED" 1009 "RESERVED" 1010 "RESERVED" 1011 "RESERVED" 1012 "RESERVED" 1013 "RESERVED" 1014 "RESERVED" 1015 "RESERVED" 1016 "RESERVED" 1017 "RESERVED" 1018 "RESERVED" 1019 "RESERVED" 1020 "RESERVED" 1021 "RESERVED" 1022 "RESERVED" 1023 "None" ;
VAL_ 818 L_ATCU_Sys_AutoDrvTargetTempVal 0 "0x0~0x3EB:-40.0~60.0¡É" 1003 "0x0~0x3EB:-40.0~60.0¡É" 1004 "3EC~0xFFFE:RESERVED" 65534 "3EC~0xFFFE:RESERVED" 65535 "Invalid" ;
VAL_ 818 L_ATCU_Sys_AutoDrvTempDrState 0 "0x0~0x3E8:0~100.0%" 1000 "0x0~0x3E8:0~100.0%" 1001 "RESERVED" 1002 "RESERVED" 1003 "RESERVED" 1004 "RESERVED" 1005 "RESERVED" 1006 "RESERVED" 1007 "RESERVED" 1008 "RESERVED" 1009 "RESERVED" 1010 "RESERVED" 1011 "RESERVED" 1012 "RESERVED" 1013 "RESERVED" 1014 "RESERVED" 1015 "RESERVED" 1016 "RESERVED" 1017 "RESERVED" 1018 "RESERVED" 1019 "RESERVED" 1020 "RESERVED" 1021 "RESERVED" 1022 "RESERVED" 1023 "None" ;
VAL_ 819 L_ATCU_Sys_Auto2LHBlrVtgVal 0 "0x0~0x34BC:0~13.500V" 13500 "0x0~0x34BC:0~13.500V" 13501 "34BD~0xFFFE:RESERVED" 65534 "34BD~0xFFFE:RESERVED" 65535 "None" ;
VAL_ 819 L_ATCU_Sys_Auto2LHModState 0 "Off" 1 "Floor" 2 "Vent" 3 "BL" 4 "Def_EU" 5 "Mix" 6 "Def_Vent" 7 "All" 8 "Vent_Bleed" 9 "Floor_100" 10 "Warm_Floor" 11 "Cool_Mix" 12 "Def" 13 "RESERVED" 14 "RESERVED" 15 "None" ;
VAL_ 819 L_ATCU_Sys_Auto2LHTempDrState 0 "0x0~0x3E8:0~100.0%" 1000 "0x0~0x3E8:0~100.0%" 1001 "RESERVED" 1002 "RESERVED" 1003 "RESERVED" 1004 "RESERVED" 1005 "RESERVED" 1006 "RESERVED" 1007 "RESERVED" 1008 "RESERVED" 1009 "RESERVED" 1010 "RESERVED" 1011 "RESERVED" 1012 "RESERVED" 1013 "RESERVED" 1014 "RESERVED" 1015 "RESERVED" 1016 "RESERVED" 1017 "RESERVED" 1018 "RESERVED" 1019 "RESERVED" 1020 "RESERVED" 1021 "RESERVED" 1022 "RESERVED" 1023 "None" ;
VAL_ 819 L_ATCU_Sys_AutoHeatloadStep 0 "Off" 1 "1Step" 2 "2Step" 3 "3Step" 4 "4Step" 5 "5Step" 6 "6Step" 7 "7Step" 8 "8Step" 9 "9Step" 10 "10Step" 11 "11Step" 12 "12Step" 13 "13Step" 14 "14Step" 15 "15Step" 16 "16Step" 17 "RESERVED" 18 "RESERVED" 19 "RESERVED" 20 "RESERVED" 21 "RESERVED" 22 "RESERVED" 23 "RESERVED" 24 "RESERVED" 25 "RESERVED" 26 "RESERVED" 27 "RESERVED" 28 "RESERVED" 29 "RESERVED" 30 "RESERVED" 31 "RESERVED" ;
VAL_ 819 L_ATCU_Sys_AutoHVPTCDuty 0 "0x0~0x64:0~100%" 100 "0x0~0x64:0~100%" 101 "65~0xFE:RESERVED" 254 "65~0xFE:RESERVED" 255 "Invalid" ;
VAL_ 819 L_ATCU_Sys_AutoECompRpm 0 "0x0~0xFFFE:0~65534RPM" 65534 "0x0~0xFFFE:0~65534RPM" 65535 "Invalid" ;
VAL_ 820 L_ATCU_Sys_DrvMod 0 "Off" 1 "Floor" 2 "Vent" 3 "BL" 4 "Def_EU" 5 "Mix" 6 "Def_Vent" 7 "All" 8 "Vent_Bleed" 9 "Floor_100" 10 "Warm_Floor" 11 "Cool_Mix" 12 "Def" 13 "RESERVED" 14 "RESERVED" 15 "None" ;
VAL_ 820 L_ATCU_Sys_DEF 0 "0x0~0x3E8:0~100.0%" 1000 "0x0~0x3E8:0~100.0%" 1001 "RESERVED" 1002 "RESERVED" 1003 "RESERVED" 1004 "RESERVED" 1005 "RESERVED" 1006 "RESERVED" 1007 "RESERVED" 1008 "RESERVED" 1009 "RESERVED" 1010 "RESERVED" 1011 "RESERVED" 1012 "RESERVED" 1013 "RESERVED" 1014 "RESERVED" 1015 "RESERVED" 1016 "RESERVED" 1017 "RESERVED" 1018 "RESERVED" 1019 "RESERVED" 1020 "RESERVED" 1021 "RESERVED" 1022 "RESERVED" 1023 "None" ;
VAL_ 820 L_ATCU_Sys_BlrStep 0 "Off" 1 "1Step" 2 "2Step" 3 "3Step" 4 "4Step" 5 "5Step" 6 "6Step" 7 "7Step" 8 "8Step" 9 "RESERVED" 10 "RESERVED" 11 "RESERVED" 12 "RESERVED" 13 "RESERVED" 14 "RESERVED" 15 "RESERVED" 16 "RESERVED" 17 "RESERVED" 18 "RESERVED" 19 "RESERVED" 20 "RESERVED" 21 "RESERVED" 22 "RESERVED" 23 "RESERVED" 24 "RESERVED" 25 "RESERVED" 26 "RESERVED" 27 "RESERVED" 28 "RESERVED" 29 "RESERVED" 30 "RESERVED" 31 "RESERVED" ;
VAL_ 820 L_ATCU_Sys_AstMod 0 "Off" 1 "Floor" 2 "Vent" 3 "BL" 4 "Def_EU" 5 "Mix" 6 "Def_Vent" 7 "All" 8 "Vent_Bleed" 9 "Floor_100" 10 "Warm_Floor" 11 "Cool_Mix" 12 "Def" 13 "RESERVED" 14 "RESERVED" 15 "None" ;
VAL_ 820 L_ATCU_Sys_Intake 0 "0x0~0x3E8:0~100.0%" 1000 "0x0~0x3E8:0~100.0%" 1001 "RESERVED" 1002 "RESERVED" 1003 "RESERVED" 1004 "RESERVED" 1005 "RESERVED" 1006 "RESERVED" 1007 "RESERVED" 1008 "RESERVED" 1009 "RESERVED" 1010 "RESERVED" 1011 "RESERVED" 1012 "RESERVED" 1013 "RESERVED" 1014 "RESERVED" 1015 "RESERVED" 1016 "RESERVED" 1017 "RESERVED" 1018 "RESERVED" 1019 "RESERVED" 1020 "RESERVED" 1021 "RESERVED" 1022 "RESERVED" 1023 "None" ;
VAL_ 820 L_ATCU_Sys_AC 0 "Off" 1 "On" 2 "RESERVED" 3 "RESERVED" ;
VAL_ 820 L_ATCU_Sys_HVPTCDuty 0 "0x0~0x64:0~100%" 100 "0x0~0x64:0~100%" 101 "65~0xFE:RESERVED" 254 "65~0xFE:RESERVED" 255 "Invalid" ;
VAL_ 820 L_ATCU_Sys_BlrVtg 0 "0x0~0x34BC:0~13.500V" 13500 "0x0~0x34BC:0~13.500V" 13501 "34BD~0xFFFE:RESERVED" 65534 "34BD~0xFFFE:RESERVED" 65535 "None" ;
VAL_ 821 L_ATCU_Sys_EcompRPM 0 "0x0~0xFFFE:0~65534RPM" 65534 "0x0~0xFFFE:0~65534RPM" 65535 "Invalid" ;
VAL_ 821 L_ATCU_Sys_EvapTargetTemp 0 "0x0~0x258:-20.0~40.0¡É" 600 "0x0~0x258:-20.0~40.0¡É" 601 "259~0xFFFE:RESERVED" 65534 "259~0xFFFE:RESERVED" 65535 "Invalid" ;
VAL_ 821 L_ATCU_Sys_DrvTempDoor 0 "0x0~0x3E8:0~100.0%" 1000 "0x0~0x3E8:0~100.0%" 1001 "RESERVED" 1002 "RESERVED" 1003 "RESERVED" 1004 "RESERVED" 1005 "RESERVED" 1006 "RESERVED" 1007 "RESERVED" 1008 "RESERVED" 1009 "RESERVED" 1010 "RESERVED" 1011 "RESERVED" 1012 "RESERVED" 1013 "RESERVED" 1014 "RESERVED" 1015 "RESERVED" 1016 "RESERVED" 1017 "RESERVED" 1018 "RESERVED" 1019 "RESERVED" 1020 "RESERVED" 1021 "RESERVED" 1022 "RESERVED" 1023 "None" ;
VAL_ 821 L_ATCU_Sys_AstTempDoor 0 "0x0~0x3E8:0~100.0%" 1000 "0x0~0x3E8:0~100.0%" 1001 "RESERVED" 1002 "RESERVED" 1003 "RESERVED" 1004 "RESERVED" 1005 "RESERVED" 1006 "RESERVED" 1007 "RESERVED" 1008 "RESERVED" 1009 "RESERVED" 1010 "RESERVED" 1011 "RESERVED" 1012 "RESERVED" 1013 "RESERVED" 1014 "RESERVED" 1015 "RESERVED" 1016 "RESERVED" 1017 "RESERVED" 1018 "RESERVED" 1019 "RESERVED" 1020 "RESERVED" 1021 "RESERVED" 1022 "RESERVED" 1023 "None" ;
VAL_ 822 L_ATCU_Sys_2LHMod 0 "Off" 1 "Floor" 2 "Vent" 3 "BL" 4 "Def_EU" 5 "Mix" 6 "Def_Vent" 7 "All" 8 "Vent_Bleed" 9 "Floor_100" 10 "Warm_Floor" 11 "Cool_Mix" 12 "Def" 13 "RESERVED" 14 "RESERVED" 15 "None" ;
VAL_ 822 L_ATCU_Sys_2LHTempDoor 0 "0x0~0x3E8:0~100.0%" 1000 "0x0~0x3E8:0~100.0%" 1001 "RESERVED" 1002 "RESERVED" 1003 "RESERVED" 1004 "RESERVED" 1005 "RESERVED" 1006 "RESERVED" 1007 "RESERVED" 1008 "RESERVED" 1009 "RESERVED" 1010 "RESERVED" 1011 "RESERVED" 1012 "RESERVED" 1013 "RESERVED" 1014 "RESERVED" 1015 "RESERVED" 1016 "RESERVED" 1017 "RESERVED" 1018 "RESERVED" 1019 "RESERVED" 1020 "RESERVED" 1021 "RESERVED" 1022 "RESERVED" 1023 "None" ;
VAL_ 822 L_ATCU_Sys_2LHBlrStep 0 "Off" 1 "1Step" 2 "2Step" 3 "3Step" 4 "4Step" 5 "5Step" 6 "6Step" 7 "7Step" 8 "8Step" 9 "RESERVED" 10 "RESERVED" 11 "RESERVED" 12 "RESERVED" 13 "RESERVED" 14 "RESERVED" 15 "RESERVED" 16 "RESERVED" 17 "RESERVED" 18 "RESERVED" 19 "RESERVED" 20 "RESERVED" 21 "RESERVED" 22 "RESERVED" 23 "RESERVED" 24 "RESERVED" 25 "RESERVED" 26 "RESERVED" 27 "RESERVED" 28 "RESERVED" 29 "RESERVED" 30 "RESERVED" 31 "RESERVED" ;
VAL_ 822 L_ATCU_Sys_2LHBlrVtg 0 "0x0~0x34BC:0~13.500V" 13500 "0x0~0x34BC:0~13.500V" 13501 "34BD~0xFFFE:RESERVED" 65534 "34BD~0xFFFE:RESERVED" 65535 "None" ;
